[part 1 of 2: package /STELLANTIS/EPT/ASWCs]
AUTOSAR XML (schema 4-2-2)
package /STELLANTIS/EPT/ASWCs
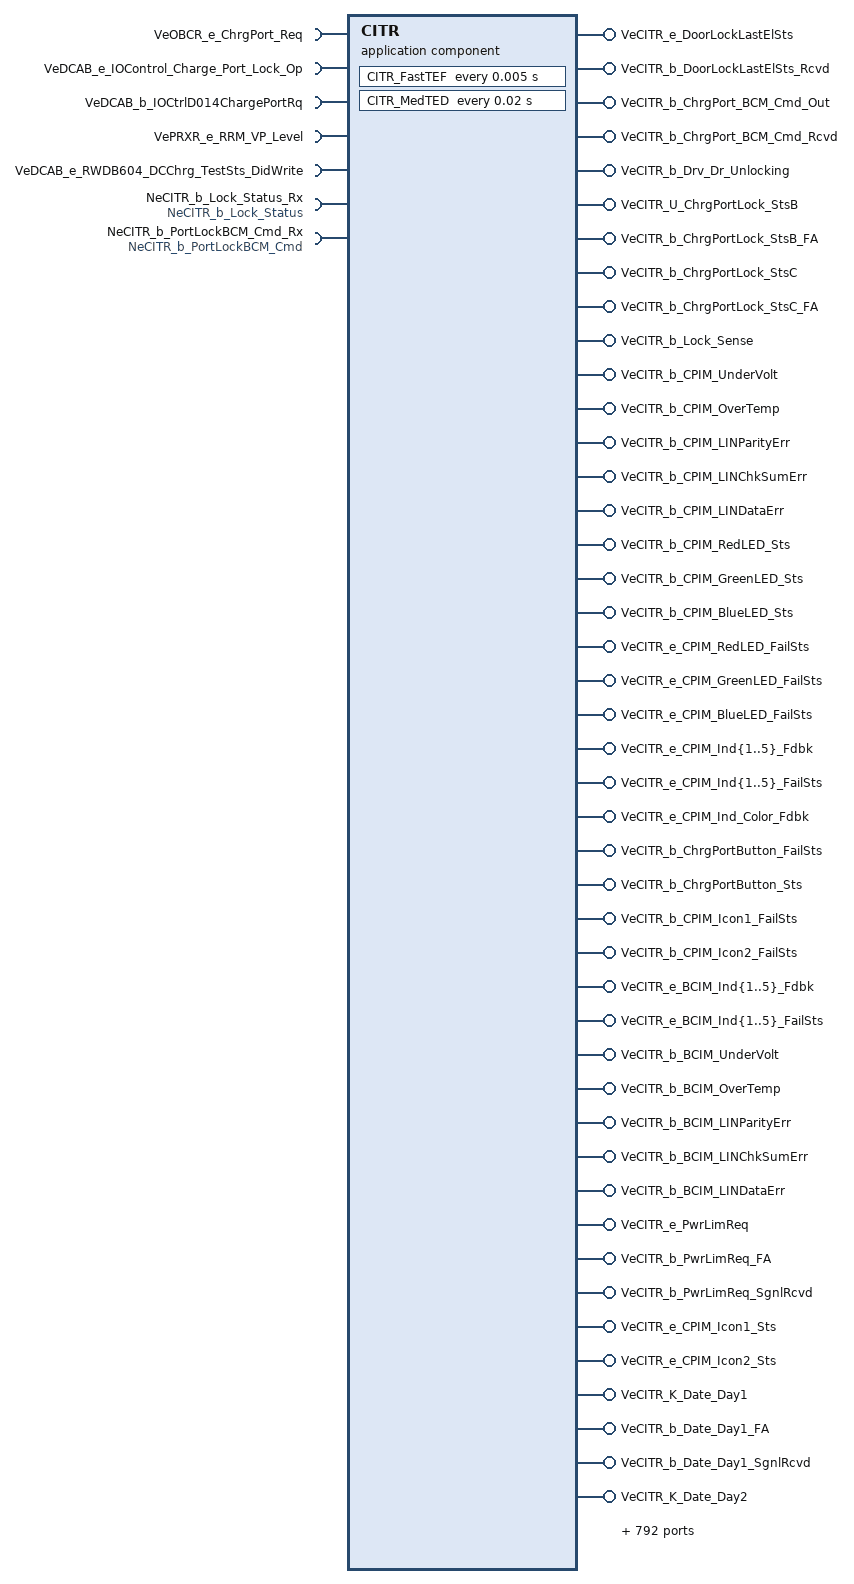
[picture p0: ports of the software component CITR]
  application sw component type CITR
    5 x require port:
      VeOBCR_e_ChrgPort_Req: nonqueued-receiver-com-spec{data-element=Value, init-value=CeOBCR_e_PortNoRequest}, required-interface=VeOBCR_e_ChrgPort_Req
      VeDCAB_e_IOControl_Charge_Port_Lock_Op: nonqueued-receiver-com-spec{data-element=Value, init-value=CeDCAB_e_IO_NOP}, required-interface=VeDCAB_e_IOControl_Charge_Port_Lock_Op
      VeDCAB_b_IOCtrlD014ChargePortRq: nonqueued-receiver-com-spec{data-element=Value, init-value=0}, required-interface=VeDCAB_b_IOCtrlD014ChargePortRq
      VePRXR_e_RRM_VP_Level: nonqueued-receiver-com-spec{data-element=Value, init-value=CePRXR_e_RRM_VP_Absent}, required-interface=VePRXR_e_RRM_VP_Level
      VeDCAB_e_RWDB604_DCChrg_TestSts_DidWrite: nonqueued-receiver-com-spec{data-element=Value, init-value=CeOBCR_e_DCChrg_TestSts_NotInit}, required-interface=VeDCAB_e_RWDB604_DCChrg_TestSts_DidWrite
    892 x provide port:
      VeCITR_e_DoorLockLastElSts: nonqueued-sender-com-spec{data-element=Value, init-value=CeOBCR_e_LKD}, provided-interface=VeCITR_e_DoorLockLastElSts
      VeCITR_b_DoorLockLastElSts_Rcvd: nonqueued-sender-com-spec{data-element=Value, init-value=0}, provided-interface=VeCITR_b_DoorLockLastElSts_Rcvd
      VeCITR_b_ChrgPort_BCM_Cmd_Out: nonqueued-sender-com-spec{data-element=Value, init-value=0}, provided-interface=VeCITR_b_ChrgPort_BCM_Cmd_Out
      VeCITR_b_ChrgPort_BCM_Cmd_Rcvd: nonqueued-sender-com-spec{data-element=Value, init-value=0}, provided-interface=VeCITR_b_ChrgPort_BCM_Cmd_Rcvd
      VeCITR_b_Drv_Dr_Unlocking: nonqueued-sender-com-spec{data-element=Value, init-value=0}, provided-interface=VeCITR_b_Drv_Dr_Unlocking
      VeCITR_U_ChrgPortLock_StsB: nonqueued-sender-com-spec{data-element=Value, init-value=0}, provided-interface=VeCITR_U_ChrgPortLock_StsB
      VeCITR_b_ChrgPortLock_StsB_FA: nonqueued-sender-com-spec{data-element=Value, init-value=0}, provided-interface=VeCITR_b_ChrgPortLock_StsB_FA
      VeCITR_b_ChrgPortLock_StsC: nonqueued-sender-com-spec{data-element=Value, init-value=0}, provided-interface=VeCITR_b_ChrgPortLock_StsC
      VeCITR_b_ChrgPortLock_StsC_FA: nonqueued-sender-com-spec{data-element=Value, init-value=0}, provided-interface=VeCITR_b_ChrgPortLock_StsC_FA
      VeCITR_b_Lock_Sense: nonqueued-sender-com-spec{data-element=Value, init-value=0}, provided-interface=VeCITR_b_Lock_Sense
      VeCITR_b_CPIM_UnderVolt: nonqueued-sender-com-spec{data-element=Value, init-value=0}, provided-interface=VeCITR_b_CPIM_UnderVolt
      VeCITR_b_CPIM_OverTemp: nonqueued-sender-com-spec{data-element=Value, init-value=0}, provided-interface=VeCITR_b_CPIM_OverTemp
      VeCITR_b_CPIM_LINParityErr: nonqueued-sender-com-spec{data-element=Value, init-value=0}, provided-interface=VeCITR_b_CPIM_LINParityErr
      VeCITR_b_CPIM_LINChkSumErr: nonqueued-sender-com-spec{data-element=Value, init-value=0}, provided-interface=VeCITR_b_CPIM_LINChkSumErr
      VeCITR_b_CPIM_LINDataErr: nonqueued-sender-com-spec{data-element=Value, init-value=0}, provided-interface=VeCITR_b_CPIM_LINDataErr
      VeCITR_b_CPIM_RedLED_Sts: nonqueued-sender-com-spec{data-element=Value, init-value=0}, provided-interface=VeCITR_b_CPIM_RedLED_Sts
      VeCITR_b_CPIM_GreenLED_Sts: nonqueued-sender-com-spec{data-element=Value, init-value=0}, provided-interface=VeCITR_b_CPIM_GreenLED_Sts
      VeCITR_b_CPIM_BlueLED_Sts: nonqueued-sender-com-spec{data-element=Value, init-value=0}, provided-interface=VeCITR_b_CPIM_BlueLED_Sts
      VeCITR_e_CPIM_RedLED_FailSts: nonqueued-sender-com-spec{data-element=Value, init-value=CeCITR_e_CPIM_LEDNormal}, provided-interface=VeCITR_e_CPIM_RedLED_FailSts
      VeCITR_e_CPIM_GreenLED_FailSts: nonqueued-sender-com-spec{data-element=Value, init-value=CeCITR_e_CPIM_LEDNormal}, provided-interface=VeCITR_e_CPIM_GreenLED_FailSts
      VeCITR_e_CPIM_BlueLED_FailSts: nonqueued-sender-com-spec{data-element=Value, init-value=CeCITR_e_CPIM_LEDNormal}, provided-interface=VeCITR_e_CPIM_BlueLED_FailSts
      VeCITR_e_CPIM_Ind{1..5}_Fdbk: nonqueued-sender-com-spec{data-element=Value, init-value=CeCITR_e_CPIM_Ind_Off}, provided-interface=VeCITR_e_CPIM_Ind{1..5}_Fdbk
      VeCITR_e_CPIM_Ind{1..5}_FailSts: nonqueued-sender-com-spec{data-element=Value, init-value=CeCITR_e_CPIM_LEDNormal}, provided-interface=VeCITR_e_CPIM_Ind{1..5}_FailSts
      VeCITR_e_CPIM_Ind_Color_Fdbk: nonqueued-sender-com-spec{data-element=Value, init-value=CeCITR_e_CPIM_NoColor}, provided-interface=VeCITR_e_CPIM_Ind_Color_Fdbk
      VeCITR_b_ChrgPortButton_FailSts: nonqueued-sender-com-spec{data-element=Value, init-value=0}, provided-interface=VeCITR_b_ChrgPortButton_FailSts
      VeCITR_b_ChrgPortButton_Sts: nonqueued-sender-com-spec{data-element=Value, init-value=0}, provided-interface=VeCITR_b_ChrgPortButton_Sts
      VeCITR_b_CPIM_Icon1_FailSts: nonqueued-sender-com-spec{data-element=Value, init-value=0}, provided-interface=VeCITR_b_CPIM_Icon1_FailSts
      VeCITR_b_CPIM_Icon2_FailSts: nonqueued-sender-com-spec{data-element=Value, init-value=0}, provided-interface=VeCITR_b_CPIM_Icon2_FailSts
      VeCITR_e_BCIM_Ind{1..5}_Fdbk: nonqueued-sender-com-spec{data-element=Value, init-value=CeCITR_e_BCIM_Ind_Off}, provided-interface=VeCITR_e_BCIM_Ind{1..5}_Fdbk
      VeCITR_e_BCIM_Ind{1..5}_FailSts: nonqueued-sender-com-spec{data-element=Value, init-value=CeCITR_e_BCIM_LEDNormal}, provided-interface=VeCITR_e_BCIM_Ind{1..5}_FailSts
      VeCITR_b_BCIM_UnderVolt: nonqueued-sender-com-spec{data-element=Value, init-value=0}, provided-interface=VeCITR_b_BCIM_UnderVolt
      VeCITR_b_BCIM_OverTemp: nonqueued-sender-com-spec{data-element=Value, init-value=0}, provided-interface=VeCITR_b_BCIM_OverTemp
      VeCITR_b_BCIM_LINParityErr: nonqueued-sender-com-spec{data-element=Value, init-value=0}, provided-interface=VeCITR_b_BCIM_LINParityErr
      VeCITR_b_BCIM_LINChkSumErr: nonqueued-sender-com-spec{data-element=Value, init-value=0}, provided-interface=VeCITR_b_BCIM_LINChkSumErr
      VeCITR_b_BCIM_LINDataErr: nonqueued-sender-com-spec{data-element=Value, init-value=0}, provided-interface=VeCITR_b_BCIM_LINDataErr
      VeCITR_e_PwrLimReq: nonqueued-sender-com-spec{data-element=Value, init-value=CeOBCR_e_PwrLimReq_SNA}, provided-interface=VeCITR_e_PwrLimReq
      VeCITR_b_PwrLimReq_FA: nonqueued-sender-com-spec{data-element=Value, init-value=0}, provided-interface=VeCITR_b_PwrLimReq_FA
      VeCITR_b_PwrLimReq_SgnlRcvd: nonqueued-sender-com-spec{data-element=Value, init-value=0}, provided-interface=VeCITR_b_PwrLimReq_SgnlRcvd
      VeCITR_e_CPIM_Icon1_Sts: nonqueued-sender-com-spec{data-element=Value, init-value=CeCITR_e_CPIM_Icon_OFF}, provided-interface=VeCITR_e_CPIM_Icon1_Sts
      VeCITR_e_CPIM_Icon2_Sts: nonqueued-sender-com-spec{data-element=Value, init-value=CeCITR_e_CPIM_Icon_OFF}, provided-interface=VeCITR_e_CPIM_Icon2_Sts
      VeCITR_K_Date_Day1: nonqueued-sender-com-spec{data-element=Value, init-value=0}, provided-interface=VeCITR_K_Date_Day1
      VeCITR_b_Date_Day1_FA: nonqueued-sender-com-spec{data-element=Value, init-value=0}, provided-interface=VeCITR_b_Date_Day1_FA
      VeCITR_b_Date_Day1_SgnlRcvd: nonqueued-sender-com-spec{data-element=Value, init-value=0}, provided-interface=VeCITR_b_Date_Day1_SgnlRcvd
      VeCITR_K_Date_Day2: nonqueued-sender-com-spec{data-element=Value, init-value=0}, provided-interface=VeCITR_K_Date_Day2
      VeCITR_K_Date_Month1: nonqueued-sender-com-spec{data-element=Value, init-value=0}, provided-interface=VeCITR_K_Date_Month1
      VeCITR_K_Date_Month2: nonqueued-sender-com-spec{data-element=Value, init-value=0}, provided-interface=VeCITR_K_Date_Month2
      VeCITR_K_Date_Year{1..4}: nonqueued-sender-com-spec{data-element=Value, init-value=0}, provided-interface=VeCITR_K_Date_Year{1..4}
      VeCITR_K_Time_Hour1: nonqueued-sender-com-spec{data-element=Value, init-value=0}, provided-interface=VeCITR_K_Time_Hour1
      VeCITR_K_Time_Hour2: nonqueued-sender-com-spec{data-element=Value, init-value=0}, provided-interface=VeCITR_K_Time_Hour2
      VeCITR_K_Time_Minute1: nonqueued-sender-com-spec{data-element=Value, init-value=0}, provided-interface=VeCITR_K_Time_Minute1
      VeCITR_K_Time_Minute2: nonqueued-sender-com-spec{data-element=Value, init-value=0}, provided-interface=VeCITR_K_Time_Minute2
      VeCITR_b_HU_Sch1_Priority: nonqueued-sender-com-spec{data-element=Value, init-value=0}, provided-interface=VeCITR_b_HU_Sch1_Priority
      VeCITR_b_HU_Sch1_ChargeUntilFull: nonqueued-sender-com-spec{data-element=Value, init-value=0}, provided-interface=VeCITR_b_HU_Sch1_ChargeUntilFull
      VeCITR_b_HU_Sch1_Do_Not_Repeat: nonqueued-sender-com-spec{data-element=Value, init-value=0}, provided-interface=VeCITR_b_HU_Sch1_Do_Not_Repeat
      VeCITR_b_HU_Sch1_Enbl: nonqueued-sender-com-spec{data-element=Value, init-value=0}, provided-interface=VeCITR_b_HU_Sch1_Enbl
      VeCITR_b_HU_Sch1_Submit: nonqueued-sender-com-spec{data-element=Value, init-value=0}, provided-interface=VeCITR_b_HU_Sch1_Submit
      VeCITR_K_HU_Sch1_Start_Time_Hr: nonqueued-sender-com-spec{data-element=Value, init-value=0}, provided-interface=VeCITR_K_HU_Sch1_Start_Time_Hr
      VeCITR_K_HU_Sch1_Start_Time_Min: nonqueued-sender-com-spec{data-element=Value, init-value=0}, provided-interface=VeCITR_K_HU_Sch1_Start_Time_Min
      VeCITR_K_HU_Sch1_End_Time_Hr: nonqueued-sender-com-spec{data-element=Value, init-value=0}, provided-interface=VeCITR_K_HU_Sch1_End_Time_Hr
      VeCITR_K_HU_Sch1_End_Time_Min: nonqueued-sender-com-spec{data-element=Value, init-value=0}, provided-interface=VeCITR_K_HU_Sch1_End_Time_Min
      VeCITR_e_HU_Sch1_Type: nonqueued-sender-com-spec{data-element=Value, init-value=CeCITR_e_SchType_NoSelection}, provided-interface=VeCITR_e_HU_Sch1_Type
      VeCITR_K_HU_Sch1_Day: nonqueued-sender-com-spec{data-element=Value, init-value=0}, provided-interface=VeCITR_K_HU_Sch1_Day
      VeCITR_b_HU_Sch1_Day_FA: nonqueued-sender-com-spec{data-element=Value, init-value=0}, provided-interface=VeCITR_b_HU_Sch1_Day_FA
      VeCITR_b_HU_Sch1_Day_SgnlRcvd: nonqueued-sender-com-spec{data-element=Value, init-value=0}, provided-interface=VeCITR_b_HU_Sch1_Day_SgnlRcvd
      VeCITR_b_TBM_Sch1_Priority: nonqueued-sender-com-spec{data-element=Value, init-value=0}, provided-interface=VeCITR_b_TBM_Sch1_Priority
      VeCITR_b_TBM_Sch1_ChargeUntilFull: nonqueued-sender-com-spec{data-element=Value, init-value=0}, provided-interface=VeCITR_b_TBM_Sch1_ChargeUntilFull
      VeCITR_b_TBM_Sch1_Do_Not_Repeat: nonqueued-sender-com-spec{data-element=Value, init-value=0}, provided-interface=VeCITR_b_TBM_Sch1_Do_Not_Repeat
      VeCITR_b_TBM_Sch1_Enbl: nonqueued-sender-com-spec{data-element=Value, init-value=0}, provided-interface=VeCITR_b_TBM_Sch1_Enbl
      VeCITR_b_TBM_Sch1_Submit: nonqueued-sender-com-spec{data-element=Value, init-value=0}, provided-interface=VeCITR_b_TBM_Sch1_Submit
      VeCITR_K_TBM_Sch1_Start_Time_Hr: nonqueued-sender-com-spec{data-element=Value, init-value=0}, provided-interface=VeCITR_K_TBM_Sch1_Start_Time_Hr
      VeCITR_K_TBM_Sch1_Start_Time_Min: nonqueued-sender-com-spec{data-element=Value, init-value=0}, provided-interface=VeCITR_K_TBM_Sch1_Start_Time_Min
      VeCITR_K_TBM_Sch1_End_Time_Hr: nonqueued-sender-com-spec{data-element=Value, init-value=0}, provided-interface=VeCITR_K_TBM_Sch1_End_Time_Hr
      VeCITR_K_TBM_Sch1_End_Time_Min: nonqueued-sender-com-spec{data-element=Value, init-value=0}, provided-interface=VeCITR_K_TBM_Sch1_End_Time_Min
      VeCITR_e_TBM_Sch1_Type: nonqueued-sender-com-spec{data-element=Value, init-value=CeCITR_e_SchType_NoSelection}, provided-interface=VeCITR_e_TBM_Sch1_Type
      VeCITR_K_TBM_Sch1_Day: nonqueued-sender-com-spec{data-element=Value, init-value=0}, provided-interface=VeCITR_K_TBM_Sch1_Day
      VeCITR_b_TBM_Sch1_Day_FA: nonqueued-sender-com-spec{data-element=Value, init-value=0}, provided-interface=VeCITR_b_TBM_Sch1_Day_FA
      VeCITR_b_TBM_Sch1_Day_SgnlRcvd: nonqueued-sender-com-spec{data-element=Value, init-value=0}, provided-interface=VeCITR_b_TBM_Sch1_Day_SgnlRcvd
      VeCITR_b_HU_Sch2_Priority: nonqueued-sender-com-spec{data-element=Value, init-value=0}, provided-interface=VeCITR_b_HU_Sch2_Priority
      VeCITR_b_HU_Sch2_ChargeUntilFull: nonqueued-sender-com-spec{data-element=Value, init-value=0}, provided-interface=VeCITR_b_HU_Sch2_ChargeUntilFull
      VeCITR_b_HU_Sch2_Do_Not_Repeat: nonqueued-sender-com-spec{data-element=Value, init-value=0}, provided-interface=VeCITR_b_HU_Sch2_Do_Not_Repeat
      VeCITR_b_HU_Sch2_Enbl: nonqueued-sender-com-spec{data-element=Value, init-value=0}, provided-interface=VeCITR_b_HU_Sch2_Enbl
      VeCITR_b_HU_Sch2_Submit: nonqueued-sender-com-spec{data-element=Value, init-value=0}, provided-interface=VeCITR_b_HU_Sch2_Submit
      VeCITR_K_HU_Sch2_Start_Time_Hr: nonqueued-sender-com-spec{data-element=Value, init-value=0}, provided-interface=VeCITR_K_HU_Sch2_Start_Time_Hr
      VeCITR_K_HU_Sch2_Start_Time_Min: nonqueued-sender-com-spec{data-element=Value, init-value=0}, provided-interface=VeCITR_K_HU_Sch2_Start_Time_Min
      VeCITR_K_HU_Sch2_End_Time_Hr: nonqueued-sender-com-spec{data-element=Value, init-value=0}, provided-interface=VeCITR_K_HU_Sch2_End_Time_Hr
      VeCITR_K_HU_Sch2_End_Time_Min: nonqueued-sender-com-spec{data-element=Value, init-value=0}, provided-interface=VeCITR_K_HU_Sch2_End_Time_Min
      VeCITR_e_HU_Sch2_Type: nonqueued-sender-com-spec{data-element=Value, init-value=CeCITR_e_SchType_NoSelection}, provided-interface=VeCITR_e_HU_Sch2_Type
      VeCITR_K_HU_Sch2_Day: nonqueued-sender-com-spec{data-element=Value, init-value=0}, provided-interface=VeCITR_K_HU_Sch2_Day
      VeCITR_b_HU_Sch2_Day_FA: nonqueued-sender-com-spec{data-element=Value, init-value=0}, provided-interface=VeCITR_b_HU_Sch2_Day_FA
      VeCITR_b_HU_Sch2_Day_SgnlRcvd: nonqueued-sender-com-spec{data-element=Value, init-value=0}, provided-interface=VeCITR_b_HU_Sch2_Day_SgnlRcvd
      VeCITR_b_TBM_Sch2_Priority: nonqueued-sender-com-spec{data-element=Value, init-value=0}, provided-interface=VeCITR_b_TBM_Sch2_Priority
      VeCITR_b_TBM_Sch2_ChargeUntilFull: nonqueued-sender-com-spec{data-element=Value, init-value=0}, provided-interface=VeCITR_b_TBM_Sch2_ChargeUntilFull
      VeCITR_b_TBM_Sch2_Do_Not_Repeat: nonqueued-sender-com-spec{data-element=Value, init-value=0}, provided-interface=VeCITR_b_TBM_Sch2_Do_Not_Repeat
      VeCITR_b_TBM_Sch2_Enbl: nonqueued-sender-com-spec{data-element=Value, init-value=0}, provided-interface=VeCITR_b_TBM_Sch2_Enbl
      VeCITR_b_TBM_Sch2_Submit: nonqueued-sender-com-spec{data-element=Value, init-value=0}, provided-interface=VeCITR_b_TBM_Sch2_Submit
      VeCITR_K_TBM_Sch2_Start_Time_Hr: nonqueued-sender-com-spec{data-element=Value, init-value=0}, provided-interface=VeCITR_K_TBM_Sch2_Start_Time_Hr
      VeCITR_K_TBM_Sch2_Start_Time_Min: nonqueued-sender-com-spec{data-element=Value, init-value=0}, provided-interface=VeCITR_K_TBM_Sch2_Start_Time_Min
      VeCITR_K_TBM_Sch2_End_Time_Hr: nonqueued-sender-com-spec{data-element=Value, init-value=0}, provided-interface=VeCITR_K_TBM_Sch2_End_Time_Hr
      VeCITR_K_TBM_Sch2_End_Time_Min: nonqueued-sender-com-spec{data-element=Value, init-value=0}, provided-interface=VeCITR_K_TBM_Sch2_End_Time_Min
      VeCITR_e_TBM_Sch2_Type: nonqueued-sender-com-spec{data-element=Value, init-value=CeCITR_e_SchType_NoSelection}, provided-interface=VeCITR_e_TBM_Sch2_Type
      VeCITR_K_TBM_Sch2_Day: nonqueued-sender-com-spec{data-element=Value, init-value=0}, provided-interface=VeCITR_K_TBM_Sch2_Day
      VeCITR_b_TBM_Sch2_Day_FA: nonqueued-sender-com-spec{data-element=Value, init-value=0}, provided-interface=VeCITR_b_TBM_Sch2_Day_FA
      VeCITR_b_TBM_Sch2_Day_SgnlRcvd: nonqueued-sender-com-spec{data-element=Value, init-value=0}, provided-interface=VeCITR_b_TBM_Sch2_Day_SgnlRcvd
      VeCITR_b_HU_Sch3_Priority: nonqueued-sender-com-spec{data-element=Value, init-value=0}, provided-interface=VeCITR_b_HU_Sch3_Priority
      VeCITR_b_HU_Sch3_ChargeUntilFull: nonqueued-sender-com-spec{data-element=Value, init-value=0}, provided-interface=VeCITR_b_HU_Sch3_ChargeUntilFull
      VeCITR_b_HU_Sch3_Do_Not_Repeat: nonqueued-sender-com-spec{data-element=Value, init-value=0}, provided-interface=VeCITR_b_HU_Sch3_Do_Not_Repeat
      VeCITR_b_HU_Sch3_Enbl: nonqueued-sender-com-spec{data-element=Value, init-value=0}, provided-interface=VeCITR_b_HU_Sch3_Enbl
      VeCITR_b_HU_Sch3_Submit: nonqueued-sender-com-spec{data-element=Value, init-value=0}, provided-interface=VeCITR_b_HU_Sch3_Submit
      VeCITR_K_HU_Sch3_Start_Time_Hr: nonqueued-sender-com-spec{data-element=Value, init-value=0}, provided-interface=VeCITR_K_HU_Sch3_Start_Time_Hr
      VeCITR_K_HU_Sch3_Start_Time_Min: nonqueued-sender-com-spec{data-element=Value, init-value=0}, provided-interface=VeCITR_K_HU_Sch3_Start_Time_Min
      VeCITR_K_HU_Sch3_End_Time_Hr: nonqueued-sender-com-spec{data-element=Value, init-value=0}, provided-interface=VeCITR_K_HU_Sch3_End_Time_Hr
      VeCITR_K_HU_Sch3_End_Time_Min: nonqueued-sender-com-spec{data-element=Value, init-value=0}, provided-interface=VeCITR_K_HU_Sch3_End_Time_Min
      VeCITR_e_HU_Sch3_Type: nonqueued-sender-com-spec{data-element=Value, init-value=CeCITR_e_SchType_NoSelection}, provided-interface=VeCITR_e_HU_Sch3_Type
      VeCITR_K_HU_Sch3_Day: nonqueued-sender-com-spec{data-element=Value, init-value=0}, provided-interface=VeCITR_K_HU_Sch3_Day
      VeCITR_b_HU_Sch3_Day_FA: nonqueued-sender-com-spec{data-element=Value, init-value=0}, provided-interface=VeCITR_b_HU_Sch3_Day_FA
      VeCITR_b_HU_Sch3_Day_SgnlRcvd: nonqueued-sender-com-spec{data-element=Value, init-value=0}, provided-interface=VeCITR_b_HU_Sch3_Day_SgnlRcvd
      VeCITR_b_TBM_Sch3_Priority: nonqueued-sender-com-spec{data-element=Value, init-value=0}, provided-interface=VeCITR_b_TBM_Sch3_Priority
      VeCITR_b_TBM_Sch3_ChargeUntilFull: nonqueued-sender-com-spec{data-element=Value, init-value=0}, provided-interface=VeCITR_b_TBM_Sch3_ChargeUntilFull
      VeCITR_b_TBM_Sch3_Do_Not_Repeat: nonqueued-sender-com-spec{data-element=Value, init-value=0}, provided-interface=VeCITR_b_TBM_Sch3_Do_Not_Repeat
      VeCITR_b_TBM_Sch3_Enbl: nonqueued-sender-com-spec{data-element=Value, init-value=0}, provided-interface=VeCITR_b_TBM_Sch3_Enbl
      VeCITR_b_TBM_Sch3_Submit: nonqueued-sender-com-spec{data-element=Value, init-value=0}, provided-interface=VeCITR_b_TBM_Sch3_Submit
      VeCITR_K_TBM_Sch3_Start_Time_Hr: nonqueued-sender-com-spec{data-element=Value, init-value=0}, provided-interface=VeCITR_K_TBM_Sch3_Start_Time_Hr
      VeCITR_K_TBM_Sch3_Start_Time_Min: nonqueued-sender-com-spec{data-element=Value, init-value=0}, provided-interface=VeCITR_K_TBM_Sch3_Start_Time_Min
      VeCITR_K_TBM_Sch3_End_Time_Hr: nonqueued-sender-com-spec{data-element=Value, init-value=0}, provided-interface=VeCITR_K_TBM_Sch3_End_Time_Hr
      VeCITR_K_TBM_Sch3_End_Time_Min: nonqueued-sender-com-spec{data-element=Value, init-value=0}, provided-interface=VeCITR_K_TBM_Sch3_End_Time_Min
      VeCITR_e_TBM_Sch3_Type: nonqueued-sender-com-spec{data-element=Value, init-value=CeCITR_e_SchType_NoSelection}, provided-interface=VeCITR_e_TBM_Sch3_Type
      VeCITR_K_TBM_Sch3_Day: nonqueued-sender-com-spec{data-element=Value, init-value=0}, provided-interface=VeCITR_K_TBM_Sch3_Day
      VeCITR_b_TBM_Sch3_Day_FA: nonqueued-sender-com-spec{data-element=Value, init-value=0}, provided-interface=VeCITR_b_TBM_Sch3_Day_FA
      VeCITR_b_TBM_Sch3_Day_SgnlRcvd: nonqueued-sender-com-spec{data-element=Value, init-value=0}, provided-interface=VeCITR_b_TBM_Sch3_Day_SgnlRcvd
      VeCITR_b_ChargeNow: nonqueued-sender-com-spec{data-element=Value, init-value=0}, provided-interface=VeCITR_b_ChargeNow
      VeCITR_e_CPIM_ChrgPortLock_FailSts: nonqueued-sender-com-spec{data-element=Value, init-value=CeCITR_e_CPIMLock_Nofailure}, provided-interface=VeCITR_e_CPIM_ChrgPortLock_FailSts
      VeCITR_e_RRM_VP_Level: nonqueued-sender-com-spec{data-element=Value, init-value=CeCITR_e_RRM_VP_Absent}, provided-interface=VeCITR_e_RRM_VP_Level
      VeCITR_b_ChrgPortDoorSts: nonqueued-sender-com-spec{data-element=Value, init-value=0}, provided-interface=VeCITR_b_ChrgPortDoorSts
      VeCITR_b_TBM_ChargeNow: nonqueued-sender-com-spec{data-element=Value, init-value=0}, provided-interface=VeCITR_b_TBM_ChargeNow
      VeCITR_d_ChrgPortHbridgeFlt: nonqueued-sender-com-spec{data-element=Value, init-value=0}, provided-interface=VeCITR_d_ChrgPortHbridgeFlt
      VeCITR_b_HU_Sch1_Start_Time_HrFA: nonqueued-sender-com-spec{data-element=Value, init-value=0}, provided-interface=VeCITR_b_HU_Sch1_Start_Time_HrFA
      VeCITR_b_HU_Sch1_Start_Time_MinFA: nonqueued-sender-com-spec{data-element=Value, init-value=0}, provided-interface=VeCITR_b_HU_Sch1_Start_Time_MinFA
      VeCITR_b_HU_Sch1_End_Time_HrFA: nonqueued-sender-com-spec{data-element=Value, init-value=0}, provided-interface=VeCITR_b_HU_Sch1_End_Time_HrFA
      VeCITR_b_HU_Sch1_End_Time_MinFA: nonqueued-sender-com-spec{data-element=Value, init-value=0}, provided-interface=VeCITR_b_HU_Sch1_End_Time_MinFA
      VeCITR_b_HU_Sch1_TypeFA: nonqueued-sender-com-spec{data-element=Value, init-value=0}, provided-interface=VeCITR_b_HU_Sch1_TypeFA
      VeCITR_b_HU_Sch2_Start_Time_HrFA: nonqueued-sender-com-spec{data-element=Value, init-value=0}, provided-interface=VeCITR_b_HU_Sch2_Start_Time_HrFA
      VeCITR_b_HU_Sch2_Start_Time_MinFA: nonqueued-sender-com-spec{data-element=Value, init-value=0}, provided-interface=VeCITR_b_HU_Sch2_Start_Time_MinFA
      VeCITR_b_HU_Sch2_End_Time_HrFA: nonqueued-sender-com-spec{data-element=Value, init-value=0}, provided-interface=VeCITR_b_HU_Sch2_End_Time_HrFA
      VeCITR_b_HU_Sch2_End_Time_MinFA: nonqueued-sender-com-spec{data-element=Value, init-value=0}, provided-interface=VeCITR_b_HU_Sch2_End_Time_MinFA
      VeCITR_b_HU_Sch2_TypeFA: nonqueued-sender-com-spec{data-element=Value, init-value=0}, provided-interface=VeCITR_b_HU_Sch2_TypeFA
      VeCITR_b_HU_Sch3_Start_Time_HrFA: nonqueued-sender-com-spec{data-element=Value, init-value=0}, provided-interface=VeCITR_b_HU_Sch3_Start_Time_HrFA
      VeCITR_b_HU_Sch3_Start_Time_MinFA: nonqueued-sender-com-spec{data-element=Value, init-value=0}, provided-interface=VeCITR_b_HU_Sch3_Start_Time_MinFA
      VeCITR_b_HU_Sch3_End_Time_HrFA: nonqueued-sender-com-spec{data-element=Value, init-value=0}, provided-interface=VeCITR_b_HU_Sch3_End_Time_HrFA
      VeCITR_b_HU_Sch3_End_Time_MinFA: nonqueued-sender-com-spec{data-element=Value, init-value=0}, provided-interface=VeCITR_b_HU_Sch3_End_Time_MinFA
      VeCITR_b_HU_Sch3_TypeFA: nonqueued-sender-com-spec{data-element=Value, init-value=0}, provided-interface=VeCITR_b_HU_Sch3_TypeFA
      VeCITR_b_TBM_Sch1_Start_Time_HrFA: nonqueued-sender-com-spec{data-element=Value, init-value=0}, provided-interface=VeCITR_b_TBM_Sch1_Start_Time_HrFA
      VeCITR_b_TBM_Sch1_Start_Time_MinFA: nonqueued-sender-com-spec{data-element=Value, init-value=0}, provided-interface=VeCITR_b_TBM_Sch1_Start_Time_MinFA
      VeCITR_b_TBM_Sch1_End_Time_HrFA: nonqueued-sender-com-spec{data-element=Value, init-value=0}, provided-interface=VeCITR_b_TBM_Sch1_End_Time_HrFA
      VeCITR_b_TBM_Sch1_End_Time_MinFA: nonqueued-sender-com-spec{data-element=Value, init-value=0}, provided-interface=VeCITR_b_TBM_Sch1_End_Time_MinFA
      VeCITR_b_TBM_Sch1_TypeFA: nonqueued-sender-com-spec{data-element=Value, init-value=0}, provided-interface=VeCITR_b_TBM_Sch1_TypeFA
      VeCITR_b_TBM_Sch2_Start_Time_HrFA: nonqueued-sender-com-spec{data-element=Value, init-value=0}, provided-interface=VeCITR_b_TBM_Sch2_Start_Time_HrFA
      VeCITR_b_TBM_Sch2_Start_Time_MinFA: nonqueued-sender-com-spec{data-element=Value, init-value=0}, provided-interface=VeCITR_b_TBM_Sch2_Start_Time_MinFA
      VeCITR_b_TBM_Sch2_End_Time_HrFA: nonqueued-sender-com-spec{data-element=Value, init-value=0}, provided-interface=VeCITR_b_TBM_Sch2_End_Time_HrFA
      VeCITR_b_TBM_Sch2_End_Time_MinFA: nonqueued-sender-com-spec{data-element=Value, init-value=0}, provided-interface=VeCITR_b_TBM_Sch2_End_Time_MinFA
      VeCITR_b_TBM_Sch2_TypeFA: nonqueued-sender-com-spec{data-element=Value, init-value=0}, provided-interface=VeCITR_b_TBM_Sch2_TypeFA
      VeCITR_b_TBM_Sch3_Start_Time_HrFA: nonqueued-sender-com-spec{data-element=Value, init-value=0}, provided-interface=VeCITR_b_TBM_Sch3_Start_Time_HrFA
      VeCITR_b_TBM_Sch3_Start_Time_MinFA: nonqueued-sender-com-spec{data-element=Value, init-value=0}, provided-interface=VeCITR_b_TBM_Sch3_Start_Time_MinFA
      VeCITR_b_TBM_Sch3_End_Time_HrFA: nonqueued-sender-com-spec{data-element=Value, init-value=0}, provided-interface=VeCITR_b_TBM_Sch3_End_Time_HrFA
      VeCITR_b_TBM_Sch3_End_Time_MinFA: nonqueued-sender-com-spec{data-element=Value, init-value=0}, provided-interface=VeCITR_b_TBM_Sch3_End_Time_MinFA
      VeCITR_b_TBM_Sch3_TypeFA: nonqueued-sender-com-spec{data-element=Value, init-value=0}, provided-interface=VeCITR_b_TBM_Sch3_TypeFA
      VeCITR_b_CPIM_Ind{1..5}_FdbkFA: nonqueued-sender-com-spec{data-element=Value, init-value=0}, provided-interface=VeCITR_b_CPIM_Ind{1..5}_FdbkFA
      VeCITR_b_CPIM_Ind_Color_FdbkFA: nonqueued-sender-com-spec{data-element=Value, init-value=0}, provided-interface=VeCITR_b_CPIM_Ind_Color_FdbkFA
      VeCITR_b_CPIM_Icon1_StsFA: nonqueued-sender-com-spec{data-element=Value, init-value=0}, provided-interface=VeCITR_b_CPIM_Icon1_StsFA
      VeCITR_b_CPIM_Icon2_StsFA: nonqueued-sender-com-spec{data-element=Value, init-value=0}, provided-interface=VeCITR_b_CPIM_Icon2_StsFA
      VeCITR_b_BCIM_Ind{1..5}_FdbkFA: nonqueued-sender-com-spec{data-element=Value, init-value=0}, provided-interface=VeCITR_b_BCIM_Ind{1..5}_FdbkFA
      VeCITR_b_ChrgPortLock_FailStsFA: nonqueued-sender-com-spec{data-element=Value, init-value=0}, provided-interface=VeCITR_b_ChrgPortLock_FailStsFA
      VeCITR_K_DateTmDay: nonqueued-sender-com-spec{data-element=Value, init-value=0}, provided-interface=VeCITR_K_DateTmDay
      VeCITR_b_DateTmDay_FA: nonqueued-sender-com-spec{data-element=Value, init-value=0}, provided-interface=VeCITR_b_DateTmDay_FA
      VeCITR_b_DateTmDay_SgnlRcvd: nonqueued-sender-com-spec{data-element=Value, init-value=0}, provided-interface=VeCITR_b_DateTmDay_SgnlRcvd
      VeCITR_K_DateTmMon: nonqueued-sender-com-spec{data-element=Value, init-value=0}, provided-interface=VeCITR_K_DateTmMon
      VeCITR_K_DateTmYear: nonqueued-sender-com-spec{data-element=Value, init-value=0}, provided-interface=VeCITR_K_DateTmYear
      VeCITR_K_DateTmHour: nonqueued-sender-com-spec{data-element=Value, init-value=0}, provided-interface=VeCITR_K_DateTmHour
      VeCITR_K_DateTmMin: nonqueued-sender-com-spec{data-element=Value, init-value=0}, provided-interface=VeCITR_K_DateTmMin
      VeCITR_K_DateTmSec: nonqueued-sender-com-spec{data-element=Value, init-value=0}, provided-interface=VeCITR_K_DateTmSec
      VeCITR_e_DateTmFormat: nonqueued-sender-com-spec{data-element=Value, init-value=CeCITR_e_DateTm_NotDef}, provided-interface=VeCITR_e_DateTmFormat
      VeCITR_b_DateTmFormat_FA: nonqueued-sender-com-spec{data-element=Value, init-value=0}, provided-interface=VeCITR_b_DateTmFormat_FA
      VeCITR_e_DVC_ChrgPort_IO: nonqueued-sender-com-spec{data-element=Value, init-value=CeODCR_e_Return_ECU_Cntrl}, provided-interface=VeCITR_e_DVC_ChrgPort_IO
      VeCITR_b_DVC_ChrgPortRq: nonqueued-sender-com-spec{data-element=Value, init-value=0}, provided-interface=VeCITR_b_DVC_ChrgPortRq
      VeCITR_e_DCChrg_TestSts: nonqueued-sender-com-spec{data-element=Value, init-value=CeOBCR_e_DCChrg_TestSts_NotInit}, provided-interface=VeCITR_e_DCChrg_TestSts
      VeCITR_Cnt_DCEOL_SgnlRcvd: nonqueued-sender-com-spec{data-element=Value, init-value=0}, provided-interface=VeCITR_Cnt_DCEOL_SgnlRcvd
      VeCITR_b_PortLockBCM_Cmd: nonqueued-sender-com-spec{data-element=Value, init-value=0}, provided-interface=VeCITR_b_PortLockBCM_Cmd
      VeCITR_e_ChrgPortLock_StsB: nonqueued-sender-com-spec{data-element=Value, init-value=CeOBCR_e_DefaultLock_Sts}, provided-interface=VeCITR_e_ChrgPortLock_StsB
      VeCITR_b_HBridge_ChrgPortLck_Cal: nonqueued-sender-com-spec{data-element=Value, init-value=0}, provided-interface=VeCITR_b_HBridge_ChrgPortLck_Cal
      VeCITR_b_ChrgPortLockSts: nonqueued-sender-com-spec{data-element=Value, init-value=0}, provided-interface=VeCITR_b_ChrgPortLockSts
      VeCITR_b_ChrgPortLockSts_FA: nonqueued-sender-com-spec{data-element=Value, init-value=0}, provided-interface=VeCITR_b_ChrgPortLockSts_FA
      VeCITR_b_ChrgPortSts: nonqueued-sender-com-spec{data-element=Value, init-value=0}, provided-interface=VeCITR_b_ChrgPortSts
      VeCITR_e_DVC_BCIM_IO: nonqueued-sender-com-spec{data-element=Value, init-value=CeODCR_e_Return_ECU_Cntrl}, provided-interface=VeCITR_e_DVC_BCIM_IO
      VeCITR_e_DVC_BCIM_Ind{1..5}: nonqueued-sender-com-spec{data-element=Value, init-value=CeCITR_e_BCIM_Ind_Off}, provided-interface=VeCITR_e_DVC_BCIM_Ind{1..5}
      VeCITR_e_DVC_CPIM_IO: nonqueued-sender-com-spec{data-element=Value, init-value=CeODCR_e_Return_ECU_Cntrl}, provided-interface=VeCITR_e_DVC_CPIM_IO
      VeCITR_e_DVC_CPIM_Ind{1..5}: nonqueued-sender-com-spec{data-element=Value, init-value=CeCITR_e_CPIM_Ind_Off}, provided-interface=VeCITR_e_DVC_CPIM_Ind{1..5}
      VeCITR_e_DVC_CPIMBlinkRate: nonqueued-sender-com-spec{data-element=Value, init-value=CeCITR_e_CPIM_NoBlink}, provided-interface=VeCITR_e_DVC_CPIMBlinkRate
      VeCITR_e_DVC_CPIM_Color: nonqueued-sender-com-spec{data-element=Value, init-value=CeCITR_e_CPIM_NoColor}, provided-interface=VeCITR_e_DVC_CPIM_Color
      VeCITR_e_DVC_CPIM_IconI1: nonqueued-sender-com-spec{data-element=Value, init-value=CeCITR_e_CPIM_Icon_OFF}, provided-interface=VeCITR_e_DVC_CPIM_IconI1
      VeCITR_e_DVC_CPIM_IconI2: nonqueued-sender-com-spec{data-element=Value, init-value=CeCITR_e_CPIM_Icon_OFF}, provided-interface=VeCITR_e_DVC_CPIM_IconI2
      VeCITR_e_DVC_BCIM_BlinkRate: nonqueued-sender-com-spec{data-element=Value, init-value=CeCITR_e_BCIM_NoBlink}, provided-interface=VeCITR_e_DVC_BCIM_BlinkRate
      VeCITR_T_HU_Sch1_Temperature: nonqueued-sender-com-spec{data-element=Value, init-value=0}, provided-interface=VeCITR_T_HU_Sch1_Temperature
      VeCITR_b_HU_Sch1_TemperatureFA: nonqueued-sender-com-spec{data-element=Value, init-value=0}, provided-interface=VeCITR_b_HU_Sch1_TemperatureFA
      VeCITR_T_TBM_Sch1_Temperature: nonqueued-sender-com-spec{data-element=Value, init-value=0}, provided-interface=VeCITR_T_TBM_Sch1_Temperature
      VeCITR_b_TBM_Sch1_TemperatureFA: nonqueued-sender-com-spec{data-element=Value, init-value=0}, provided-interface=VeCITR_b_TBM_Sch1_TemperatureFA
      VeCITR_T_HU_Sch2_Temperature: nonqueued-sender-com-spec{data-element=Value, init-value=0}, provided-interface=VeCITR_T_HU_Sch2_Temperature
      VeCITR_b_HU_Sch2_TemperatureFA: nonqueued-sender-com-spec{data-element=Value, init-value=0}, provided-interface=VeCITR_b_HU_Sch2_TemperatureFA
      VeCITR_T_TBM_Sch2_Temperature: nonqueued-sender-com-spec{data-element=Value, init-value=0}, provided-interface=VeCITR_T_TBM_Sch2_Temperature
      VeCITR_b_TBM_Sch2_TemperatureFA: nonqueued-sender-com-spec{data-element=Value, init-value=0}, provided-interface=VeCITR_b_TBM_Sch2_TemperatureFA
      VeCITR_T_HU_Sch3_Temperature: nonqueued-sender-com-spec{data-element=Value, init-value=0}, provided-interface=VeCITR_T_HU_Sch3_Temperature
      VeCITR_b_HU_Sch3_TemperatureFA: nonqueued-sender-com-spec{data-element=Value, init-value=0}, provided-interface=VeCITR_b_HU_Sch3_TemperatureFA
      VeCITR_T_TBM_Sch3_Temperature: nonqueued-sender-com-spec{data-element=Value, init-value=0}, provided-interface=VeCITR_T_TBM_Sch3_Temperature
      VeCITR_b_TBM_Sch3_TemperatureFA: nonqueued-sender-com-spec{data-element=Value, init-value=0}, provided-interface=VeCITR_b_TBM_Sch3_TemperatureFA
      VeCITR_e_HU_Sch3_Allow: nonqueued-sender-com-spec{data-element=Value, init-value=CeCITR_e_AnyTime}, provided-interface=VeCITR_e_HU_Sch3_Allow
      VeCITR_b_HU_Sch3_AllowFA: nonqueued-sender-com-spec{data-element=Value, init-value=0}, provided-interface=VeCITR_b_HU_Sch3_AllowFA
      VeCITR_e_TBM_Sch3_Allow: nonqueued-sender-com-spec{data-element=Value, init-value=CeCITR_e_AnyTime}, provided-interface=VeCITR_e_TBM_Sch3_Allow
      VeCITR_b_TBM_Sch3_AllowFA: nonqueued-sender-com-spec{data-element=Value, init-value=0}, provided-interface=VeCITR_b_TBM_Sch3_AllowFA
      VeCITR_b_HU_Sch4_Enbl: nonqueued-sender-com-spec{data-element=Value, init-value=0}, provided-interface=VeCITR_b_HU_Sch4_Enbl
      VeCITR_b_HU_Sch4_Submit: nonqueued-sender-com-spec{data-element=Value, init-value=0}, provided-interface=VeCITR_b_HU_Sch4_Submit
      VeCITR_K_HU_Sch4_Start_Time_Hr: nonqueued-sender-com-spec{data-element=Value, init-value=0}, provided-interface=VeCITR_K_HU_Sch4_Start_Time_Hr
      VeCITR_K_HU_Sch4_Start_Time_Min: nonqueued-sender-com-spec{data-element=Value, init-value=0}, provided-interface=VeCITR_K_HU_Sch4_Start_Time_Min
      VeCITR_K_HU_Sch4_Day: nonqueued-sender-com-spec{data-element=Value, init-value=0}, provided-interface=VeCITR_K_HU_Sch4_Day
      VeCITR_b_HU_Sch4_Day_FA: nonqueued-sender-com-spec{data-element=Value, init-value=0}, provided-interface=VeCITR_b_HU_Sch4_Day_FA
      VeCITR_b_HU_Sch4_Day_SgnlRcvd: nonqueued-sender-com-spec{data-element=Value, init-value=0}, provided-interface=VeCITR_b_HU_Sch4_Day_SgnlRcvd
      VeCITR_b_HU_Sch4_Start_Time_HrFA: nonqueued-sender-com-spec{data-element=Value, init-value=0}, provided-interface=VeCITR_b_HU_Sch4_Start_Time_HrFA
      VeCITR_b_HU_Sch4_Start_Time_MinFA: nonqueued-sender-com-spec{data-element=Value, init-value=0}, provided-interface=VeCITR_b_HU_Sch4_Start_Time_MinFA
      VeCITR_T_HU_Sch4_Temperature: nonqueued-sender-com-spec{data-element=Value, init-value=0}, provided-interface=VeCITR_T_HU_Sch4_Temperature
      VeCITR_b_HU_Sch4_TemperatureFA: nonqueued-sender-com-spec{data-element=Value, init-value=0}, provided-interface=VeCITR_b_HU_Sch4_TemperatureFA
      VeCITR_e_HU_Sch4_Allow: nonqueued-sender-com-spec{data-element=Value, init-value=CeCITR_e_AnyTime}, provided-interface=VeCITR_e_HU_Sch4_Allow
      VeCITR_b_HU_Sch4_AllowFA: nonqueued-sender-com-spec{data-element=Value, init-value=0}, provided-interface=VeCITR_b_HU_Sch4_AllowFA
      VeCITR_b_TBM_Sch4_Enbl: nonqueued-sender-com-spec{data-element=Value, init-value=0}, provided-interface=VeCITR_b_TBM_Sch4_Enbl
      VeCITR_b_TBM_Sch4_Submit: nonqueued-sender-com-spec{data-element=Value, init-value=0}, provided-interface=VeCITR_b_TBM_Sch4_Submit
      VeCITR_K_TBM_Sch4_Start_Time_Hr: nonqueued-sender-com-spec{data-element=Value, init-value=0}, provided-interface=VeCITR_K_TBM_Sch4_Start_Time_Hr
      VeCITR_K_TBM_Sch4_Start_Time_Min: nonqueued-sender-com-spec{data-element=Value, init-value=0}, provided-interface=VeCITR_K_TBM_Sch4_Start_Time_Min
      VeCITR_K_TBM_Sch4_Day: nonqueued-sender-com-spec{data-element=Value, init-value=0}, provided-interface=VeCITR_K_TBM_Sch4_Day
      VeCITR_b_TBM_Sch4_Day_FA: nonqueued-sender-com-spec{data-element=Value, init-value=0}, provided-interface=VeCITR_b_TBM_Sch4_Day_FA
      VeCITR_b_TBM_Sch4_Day_SgnlRcvd: nonqueued-sender-com-spec{data-element=Value, init-value=0}, provided-interface=VeCITR_b_TBM_Sch4_Day_SgnlRcvd
      VeCITR_b_TBM_Sch4_Start_Time_HrFA: nonqueued-sender-com-spec{data-element=Value, init-value=0}, provided-interface=VeCITR_b_TBM_Sch4_Start_Time_HrFA
      VeCITR_b_TBM_Sch4_Start_Time_MinFA: nonqueued-sender-com-spec{data-element=Value, init-value=0}, provided-interface=VeCITR_b_TBM_Sch4_Start_Time_MinFA
      VeCITR_T_TBM_Sch4_Temperature: nonqueued-sender-com-spec{data-element=Value, init-value=0}, provided-interface=VeCITR_T_TBM_Sch4_Temperature
      VeCITR_b_TBM_Sch4_TemperatureFA: nonqueued-sender-com-spec{data-element=Value, init-value=0}, provided-interface=VeCITR_b_TBM_Sch4_TemperatureFA
      VeCITR_e_TBM_Sch4_Allow: nonqueued-sender-com-spec{data-element=Value, init-value=CeCITR_e_AnyTime}, provided-interface=VeCITR_e_TBM_Sch4_Allow
      VeCITR_b_TBM_Sch4_AllowFA: nonqueued-sender-com-spec{data-element=Value, init-value=0}, provided-interface=VeCITR_b_TBM_Sch4_AllowFA
      VeCITR_P_ChargingDestinationPwr: nonqueued-sender-com-spec{data-element=Value, init-value=0}, provided-interface=VeCITR_P_ChargingDestinationPwr
      VeCITR_b_ChargingDestinationPwr_FA: nonqueued-sender-com-spec{data-element=Value, init-value=0}, provided-interface=VeCITR_b_ChargingDestinationPwr_FA
      VeCITR_l_DistanceToCharge: nonqueued-sender-com-spec{data-element=Value, init-value=0}, provided-interface=VeCITR_l_DistanceToCharge
      VeCITR_b_DistanceToCharge_FA: nonqueued-sender-com-spec{data-element=Value, init-value=0}, provided-interface=VeCITR_b_DistanceToCharge_FA
      VeCITR_t_TimeToCharge: nonqueued-sender-com-spec{data-element=Value, init-value=0}, provided-interface=VeCITR_t_TimeToCharge
      VeCITR_b_TimeToCharge_FA: nonqueued-sender-com-spec{data-element=Value, init-value=0}, provided-interface=VeCITR_b_TimeToCharge_FA
      VeCITR_e_FOTA_Install_Type: nonqueued-sender-com-spec{data-element=Value, init-value=CeCITR_e_NoFOTA}, provided-interface=VeCITR_e_FOTA_Install_Type
      VeCITR_b_FOTA_Install_Type_FA: nonqueued-sender-com-spec{data-element=Value, init-value=0}, provided-interface=VeCITR_b_FOTA_Install_Type_FA
      VeCITR_e_FOTA_Install_Status: nonqueued-sender-com-spec{data-element=Value, init-value=CeCITR_e_Installation_Default}, provided-interface=VeCITR_e_FOTA_Install_Status
      VeCITR_b_SOC_Max_Lev: nonqueued-sender-com-spec{data-element=Value, init-value=0}, provided-interface=VeCITR_b_SOC_Max_Lev
      VeCITR_b_SOC_Max_Lev_FA: nonqueued-sender-com-spec{data-element=Value, init-value=0}, provided-interface=VeCITR_b_SOC_Max_Lev_FA
      VeCITR_b_DC_PwrLev: nonqueued-sender-com-spec{data-element=Value, init-value=0}, provided-interface=VeCITR_b_DC_PwrLev
      VeCITR_b_DC_PwrLev_FA: nonqueued-sender-com-spec{data-element=Value, init-value=0}, provided-interface=VeCITR_b_DC_PwrLev_FA
      VeCITR_b_DC_PwrLev_SgnlRcvd: nonqueued-sender-com-spec{data-element=Value, init-value=0}, provided-interface=VeCITR_b_DC_PwrLev_SgnlRcvd
      VeCITR_e_ChrgrFlapSts: nonqueued-sender-com-spec{data-element=Value, init-value=CeCITR_e_ChrgrFlap_Closed}, provided-interface=VeCITR_e_ChrgrFlapSts
      VeCITR_b_ChrgrFlapSts_FA: nonqueued-sender-com-spec{data-element=Value, init-value=0}, provided-interface=VeCITR_b_ChrgrFlapSts_FA
      VeCITR_e_BCIM_Ind_Color_Fdbk: nonqueued-sender-com-spec{data-element=Value, init-value=CeCITR_e_BCIM_NoColor}, provided-interface=VeCITR_e_BCIM_Ind_Color_Fdbk
      VeCITR_b_BCIM_Ind_Color_FdbkFA: nonqueued-sender-com-spec{data-element=Value, init-value=0}, provided-interface=VeCITR_b_BCIM_Ind_Color_FdbkFA
      VeCITR_e_DVC_BCIM_Color: nonqueued-sender-com-spec{data-element=Value, init-value=CeCITR_e_BCIM_NoColor}, provided-interface=VeCITR_e_DVC_BCIM_Color
      VeCITR_e_HU_ChrgSchedType1: nonqueued-sender-com-spec{data-element=Value, init-value=CeCITR_e_No_Selection}, provided-interface=VeCITR_e_HU_ChrgSchedType1
      VeCITR_b_HU_ChrgSchedType1FA: nonqueued-sender-com-spec{data-element=Value, init-value=0}, provided-interface=VeCITR_b_HU_ChrgSchedType1FA
      VeCITR_e_HU_ChrgSchedType2: nonqueued-sender-com-spec{data-element=Value, init-value=CeCITR_e_No_Selection}, provided-interface=VeCITR_e_HU_ChrgSchedType2
      VeCITR_b_HU_ChrgSchedType2FA: nonqueued-sender-com-spec{data-element=Value, init-value=0}, provided-interface=VeCITR_b_HU_ChrgSchedType2FA
      VeCITR_Pct_HU_ExtChrgTarget1: nonqueued-sender-com-spec{data-element=Value, init-value=0}, provided-interface=VeCITR_Pct_HU_ExtChrgTarget1
      VeCITR_b_HU_ExtChrgTarget1FA: nonqueued-sender-com-spec{data-element=Value, init-value=0}, provided-interface=VeCITR_b_HU_ExtChrgTarget1FA
      VeCITR_Pct_HU_ExtChrgTarget2: nonqueued-sender-com-spec{data-element=Value, init-value=0}, provided-interface=VeCITR_Pct_HU_ExtChrgTarget2
      VeCITR_b_HU_ExtChrgTarget2FA: nonqueued-sender-com-spec{data-element=Value, init-value=0}, provided-interface=VeCITR_b_HU_ExtChrgTarget2FA
      VeCITR_Pct_HU_ImmChrgTarget1: nonqueued-sender-com-spec{data-element=Value, init-value=0}, provided-interface=VeCITR_Pct_HU_ImmChrgTarget1
      VeCITR_b_HU_ImmChrgTarget1FA: nonqueued-sender-com-spec{data-element=Value, init-value=0}, provided-interface=VeCITR_b_HU_ImmChrgTarget1FA
      VeCITR_Pct_HU_ImmChrgTarget2: nonqueued-sender-com-spec{data-element=Value, init-value=0}, provided-interface=VeCITR_Pct_HU_ImmChrgTarget2
      VeCITR_b_HU_ImmChrgTarget2FA: nonqueued-sender-com-spec{data-element=Value, init-value=0}, provided-interface=VeCITR_b_HU_ImmChrgTarget2FA
      VeCITR_b_CoopCh_VehLocation: nonqueued-sender-com-spec{data-element=Value, init-value=0}, provided-interface=VeCITR_b_CoopCh_VehLocation
      VeCITR_b_CoopCh_VehLocationFA: nonqueued-sender-com-spec{data-element=Value, init-value=0}, provided-interface=VeCITR_b_CoopCh_VehLocationFA
      VeCITR_e_RmtChrgPortLkCmd: nonqueued-sender-com-spec{data-element=Value, init-value=CeCITR_e_Default}, provided-interface=VeCITR_e_RmtChrgPortLkCmd
      VeCITR_b_RmtChrgPortLkCmdFA: nonqueued-sender-com-spec{data-element=Value, init-value=0}, provided-interface=VeCITR_b_RmtChrgPortLkCmdFA
      VeCITR_b_RmtChrgPortLkCmd_SgnlRcvd: nonqueued-sender-com-spec{data-element=Value, init-value=0}, provided-interface=VeCITR_b_RmtChrgPortLkCmd_SgnlRcvd
      VeCITR_e_CoopCh_ChrgCmd: nonqueued-sender-com-spec{data-element=Value, init-value=CeCITR_e_DEFAULT}, provided-interface=VeCITR_e_CoopCh_ChrgCmd
      VeCITR_b_CoopCh_ChrgCmdFA: nonqueued-sender-com-spec{data-element=Value, init-value=0}, provided-interface=VeCITR_b_CoopCh_ChrgCmdFA
      VeCITR_b_TBMStopChrg: nonqueued-sender-com-spec{data-element=Value, init-value=0}, provided-interface=VeCITR_b_TBMStopChrg
      VeCITR_b_TBMStopChrgFA: nonqueued-sender-com-spec{data-element=Value, init-value=0}, provided-interface=VeCITR_b_TBMStopChrgFA
      VeCITR_e_TBM_ChrgSchedType1: nonqueued-sender-com-spec{data-element=Value, init-value=CeCITR_e_No_Selection}, provided-interface=VeCITR_e_TBM_ChrgSchedType1
      VeCITR_b_TBM_ChrgSchedType1FA: nonqueued-sender-com-spec{data-element=Value, init-value=0}, provided-interface=VeCITR_b_TBM_ChrgSchedType1FA
      VeCITR_e_TBM_ChrgSchedType2: nonqueued-sender-com-spec{data-element=Value, init-value=CeCITR_e_No_Selection}, provided-interface=VeCITR_e_TBM_ChrgSchedType2
      VeCITR_b_TBM_ChrgSchedType2FA: nonqueued-sender-com-spec{data-element=Value, init-value=0}, provided-interface=VeCITR_b_TBM_ChrgSchedType2FA
      VeCITR_Pct_TBM_ExtChrgTarget1: nonqueued-sender-com-spec{data-element=Value, init-value=0}, provided-interface=VeCITR_Pct_TBM_ExtChrgTarget1
      VeCITR_b_TBM_ExtChrgTarget1FA: nonqueued-sender-com-spec{data-element=Value, init-value=0}, provided-interface=VeCITR_b_TBM_ExtChrgTarget1FA
      VeCITR_Pct_TBM_ExtChrgTarget2: nonqueued-sender-com-spec{data-element=Value, init-value=0}, provided-interface=VeCITR_Pct_TBM_ExtChrgTarget2
      VeCITR_b_TBM_ExtChrgTarget2FA: nonqueued-sender-com-spec{data-element=Value, init-value=0}, provided-interface=VeCITR_b_TBM_ExtChrgTarget2FA
      VeCITR_Pct_TBM_ImmChrgTarget1: nonqueued-sender-com-spec{data-element=Value, init-value=0}, provided-interface=VeCITR_Pct_TBM_ImmChrgTarget1
      VeCITR_b_TBM_ImmChrgTarget1FA: nonqueued-sender-com-spec{data-element=Value, init-value=0}, provided-interface=VeCITR_b_TBM_ImmChrgTarget1FA
      VeCITR_Pct_TBM_ImmChrgTarget2: nonqueued-sender-com-spec{data-element=Value, init-value=0}, provided-interface=VeCITR_Pct_TBM_ImmChrgTarget2
      VeCITR_b_TBM_ImmChrgTarget2FA: nonqueued-sender-com-spec{data-element=Value, init-value=0}, provided-interface=VeCITR_b_TBM_ImmChrgTarget2FA
      VeCITR_b_V2HModeReq: nonqueued-sender-com-spec{data-element=Value, init-value=0}, provided-interface=VeCITR_b_V2HModeReq
      VeCITR_b_V2HModeReqFA: nonqueued-sender-com-spec{data-element=Value, init-value=0}, provided-interface=VeCITR_b_V2HModeReqFA
      VeCITR_b_V2HReq: nonqueued-sender-com-spec{data-element=Value, init-value=0}, provided-interface=VeCITR_b_V2HReq
      VeCITR_b_V2HReqFA: nonqueued-sender-com-spec{data-element=Value, init-value=0}, provided-interface=VeCITR_b_V2HReqFA
      VeCITR_Pct_V2HRsrvBatt: nonqueued-sender-com-spec{data-element=Value, init-value=0}, provided-interface=VeCITR_Pct_V2HRsrvBatt
      VeCITR_b_V2HRsrvBattFA: nonqueued-sender-com-spec{data-element=Value, init-value=0}, provided-interface=VeCITR_b_V2HRsrvBattFA
      VeCITR_b_V2HSubmit: nonqueued-sender-com-spec{data-element=Value, init-value=0}, provided-interface=VeCITR_b_V2HSubmit
      VeCITR_b_V2HSubmitFA: nonqueued-sender-com-spec{data-element=Value, init-value=0}, provided-interface=VeCITR_b_V2HSubmitFA
      VeCITR_b_V2L_AllReq: nonqueued-sender-com-spec{data-element=Value, init-value=0}, provided-interface=VeCITR_b_V2L_AllReq
      VeCITR_b_V2L_AllReqFA: nonqueued-sender-com-spec{data-element=Value, init-value=0}, provided-interface=VeCITR_b_V2L_AllReqFA
      VeCITR_b_V2L_FrunkReq: nonqueued-sender-com-spec{data-element=Value, init-value=0}, provided-interface=VeCITR_b_V2L_FrunkReq
      VeCITR_b_V2L_FrunkReqFA: nonqueued-sender-com-spec{data-element=Value, init-value=0}, provided-interface=VeCITR_b_V2L_FrunkReqFA
      VeCITR_b_V2LModeReq: nonqueued-sender-com-spec{data-element=Value, init-value=0}, provided-interface=VeCITR_b_V2LModeReq
      VeCITR_b_V2LModeReqFA: nonqueued-sender-com-spec{data-element=Value, init-value=0}, provided-interface=VeCITR_b_V2LModeReqFA
      VeCITR_Pct_V2LRsrvBatt: nonqueued-sender-com-spec{data-element=Value, init-value=0}, provided-interface=VeCITR_Pct_V2LRsrvBatt
      VeCITR_b_V2LRsrvBattFA: nonqueued-sender-com-spec{data-element=Value, init-value=0}, provided-interface=VeCITR_b_V2LRsrvBattFA
      VeCITR_b_V2LSubmit: nonqueued-sender-com-spec{data-element=Value, init-value=0}, provided-interface=VeCITR_b_V2LSubmit
      VeCITR_b_V2LSubmitFA: nonqueued-sender-com-spec{data-element=Value, init-value=0}, provided-interface=VeCITR_b_V2LSubmitFA
      VeCITR_b_V2LTrunkReq: nonqueued-sender-com-spec{data-element=Value, init-value=0}, provided-interface=VeCITR_b_V2LTrunkReq
      VeCITR_b_V2LTrunkReqFA: nonqueued-sender-com-spec{data-element=Value, init-value=0}, provided-interface=VeCITR_b_V2LTrunkReqFA
      VeCITR_b_V2VModeReq: nonqueued-sender-com-spec{data-element=Value, init-value=0}, provided-interface=VeCITR_b_V2VModeReq
      VeCITR_b_V2VModeReqFA: nonqueued-sender-com-spec{data-element=Value, init-value=0}, provided-interface=VeCITR_b_V2VModeReqFA
      VeCITR_b_V2VReq: nonqueued-sender-com-spec{data-element=Value, init-value=0}, provided-interface=VeCITR_b_V2VReq
      VeCITR_b_V2VReqFA: nonqueued-sender-com-spec{data-element=Value, init-value=0}, provided-interface=VeCITR_b_V2VReqFA
      VeCITR_Pct_V2VRsrvBatt: nonqueued-sender-com-spec{data-element=Value, init-value=0}, provided-interface=VeCITR_Pct_V2VRsrvBatt
      VeCITR_b_V2VRsrvBattFA: nonqueued-sender-com-spec{data-element=Value, init-value=0}, provided-interface=VeCITR_b_V2VRsrvBattFA
      VeCITR_b_V2VSubmit: nonqueued-sender-com-spec{data-element=Value, init-value=0}, provided-interface=VeCITR_b_V2VSubmit
      VeCITR_b_V2VSubmitFA: nonqueued-sender-com-spec{data-element=Value, init-value=0}, provided-interface=VeCITR_b_V2VSubmitFA
      VeCITR_I_PPCurrentDrawSens1: nonqueued-sender-com-spec{data-element=Value, init-value=0}, provided-interface=VeCITR_I_PPCurrentDrawSens1
      VeCITR_b_PPCurrentDrawSens1FA: nonqueued-sender-com-spec{data-element=Value, init-value=0}, provided-interface=VeCITR_b_PPCurrentDrawSens1FA
      VeCITR_b_PPButtonSts: nonqueued-sender-com-spec{data-element=Value, init-value=0}, provided-interface=VeCITR_b_PPButtonSts
      VeCITR_b_PPButtonStsFA: nonqueued-sender-com-spec{data-element=Value, init-value=0}, provided-interface=VeCITR_b_PPButtonStsFA
      VeCITR_b_PPLidSwitchSts120A: nonqueued-sender-com-spec{data-element=Value, init-value=0}, provided-interface=VeCITR_b_PPLidSwitchSts120A
      VeCITR_b_PPLidSwitchSts120AFA: nonqueued-sender-com-spec{data-element=Value, init-value=0}, provided-interface=VeCITR_b_PPLidSwitchSts120AFA
      VeCITR_b_PPLidSwitchSts120B: nonqueued-sender-com-spec{data-element=Value, init-value=0}, provided-interface=VeCITR_b_PPLidSwitchSts120B
      VeCITR_b_PPLidSwitchSts120BFA: nonqueued-sender-com-spec{data-element=Value, init-value=0}, provided-interface=VeCITR_b_PPLidSwitchSts120BFA
      VeCITR_b_PPLidSwitchSts240: nonqueued-sender-com-spec{data-element=Value, init-value=0}, provided-interface=VeCITR_b_PPLidSwitchSts240
      VeCITR_b_PPLidSwitchSts240FA: nonqueued-sender-com-spec{data-element=Value, init-value=0}, provided-interface=VeCITR_b_PPLidSwitchSts240FA
      VeCITR_b_PPACPresentSens1: nonqueued-sender-com-spec{data-element=Value, init-value=0}, provided-interface=VeCITR_b_PPACPresentSens1
      VeCITR_b_PPACPresentSens1FA: nonqueued-sender-com-spec{data-element=Value, init-value=0}, provided-interface=VeCITR_b_PPACPresentSens1FA
      VeCITR_b_PPACPresentSens2: nonqueued-sender-com-spec{data-element=Value, init-value=0}, provided-interface=VeCITR_b_PPACPresentSens2
      VeCITR_b_PPACPresentSens2FA: nonqueued-sender-com-spec{data-element=Value, init-value=0}, provided-interface=VeCITR_b_PPACPresentSens2FA
      VeCITR_I_PPCurrentDrawSens2: nonqueued-sender-com-spec{data-element=Value, init-value=0}, provided-interface=VeCITR_I_PPCurrentDrawSens2
      VeCITR_b_PPCurrentDrawSens2FA: nonqueued-sender-com-spec{data-element=Value, init-value=0}, provided-interface=VeCITR_b_PPCurrentDrawSens2FA
      VeCITR_e_PPFaultRsn: nonqueued-sender-com-spec{data-element=Value, init-value=CeCITR_e_No_Fault}, provided-interface=VeCITR_e_PPFaultRsn
      VeCITR_b_PPFaultRsnFA: nonqueued-sender-com-spec{data-element=Value, init-value=0}, provided-interface=VeCITR_b_PPFaultRsnFA
      VeCITR_e_PPFault: nonqueued-sender-com-spec{data-element=Value, init-value=CeVTLR_e_NoFault}, provided-interface=VeCITR_e_PPFault
      VeCITR_b_PPFaultFA: nonqueued-sender-com-spec{data-element=Value, init-value=0}, provided-interface=VeCITR_b_PPFaultFA
      VeCITR_e_PPLEDFault: nonqueued-sender-com-spec{data-element=Value, init-value=CeCITR_e_LED_No_Fault}, provided-interface=VeCITR_e_PPLEDFault
      VeCITR_b_PPLEDFaultFA: nonqueued-sender-com-spec{data-element=Value, init-value=0}, provided-interface=VeCITR_b_PPLEDFaultFA
      VeCITR_b_RsErrSPP: nonqueued-sender-com-spec{data-element=Value, init-value=0}, provided-interface=VeCITR_b_RsErrSPP
      VeCITR_b_RsErrSPPFA: nonqueued-sender-com-spec{data-element=Value, init-value=0}, provided-interface=VeCITR_b_RsErrSPPFA
      VeCITR_P_PPRatedPower: nonqueued-sender-com-spec{data-element=Value, init-value=0}, provided-interface=VeCITR_P_PPRatedPower
      VeCITR_b_PPRatedPowerFA: nonqueued-sender-com-spec{data-element=Value, init-value=0}, provided-interface=VeCITR_b_PPRatedPowerFA
      VeCITR_I_PP2CurrentDrawSens1: nonqueued-sender-com-spec{data-element=Value, init-value=0}, provided-interface=VeCITR_I_PP2CurrentDrawSens1
      VeCITR_b_PP2CurrentDrawSens1FA: nonqueued-sender-com-spec{data-element=Value, init-value=0}, provided-interface=VeCITR_b_PP2CurrentDrawSens1FA
      VeCITR_b_PP2ButtonSts: nonqueued-sender-com-spec{data-element=Value, init-value=0}, provided-interface=VeCITR_b_PP2ButtonSts
      VeCITR_b_PP2ButtonStsFA: nonqueued-sender-com-spec{data-element=Value, init-value=0}, provided-interface=VeCITR_b_PP2ButtonStsFA
      VeCITR_b_PP2LidSwitchSts120A: nonqueued-sender-com-spec{data-element=Value, init-value=0}, provided-interface=VeCITR_b_PP2LidSwitchSts120A
      VeCITR_b_PP2LidSwitchSts120AFA: nonqueued-sender-com-spec{data-element=Value, init-value=0}, provided-interface=VeCITR_b_PP2LidSwitchSts120AFA
      VeCITR_b_PP2LidSwitchSts120B: nonqueued-sender-com-spec{data-element=Value, init-value=0}, provided-interface=VeCITR_b_PP2LidSwitchSts120B
      VeCITR_b_PP2LidSwitchSts120BFA: nonqueued-sender-com-spec{data-element=Value, init-value=0}, provided-interface=VeCITR_b_PP2LidSwitchSts120BFA
      VeCITR_b_PP2LidSwitchSts240: nonqueued-sender-com-spec{data-element=Value, init-value=0}, provided-interface=VeCITR_b_PP2LidSwitchSts240
      VeCITR_b_PP2LidSwitchSts240FA: nonqueued-sender-com-spec{data-element=Value, init-value=0}, provided-interface=VeCITR_b_PP2LidSwitchSts240FA
      VeCITR_b_PP2ACPresentSens1: nonqueued-sender-com-spec{data-element=Value, init-value=0}, provided-interface=VeCITR_b_PP2ACPresentSens1
      VeCITR_b_PP2ACPresentSens1FA: nonqueued-sender-com-spec{data-element=Value, init-value=0}, provided-interface=VeCITR_b_PP2ACPresentSens1FA
      VeCITR_b_PP2ACPresentSens2: nonqueued-sender-com-spec{data-element=Value, init-value=0}, provided-interface=VeCITR_b_PP2ACPresentSens2
      VeCITR_b_PP2ACPresentSens2FA: nonqueued-sender-com-spec{data-element=Value, init-value=0}, provided-interface=VeCITR_b_PP2ACPresentSens2FA
      VeCITR_I_PP2CurrentDrawSens2: nonqueued-sender-com-spec{data-element=Value, init-value=0}, provided-interface=VeCITR_I_PP2CurrentDrawSens2
      VeCITR_b_PP2CurrentDrawSens2FA: nonqueued-sender-com-spec{data-element=Value, init-value=0}, provided-interface=VeCITR_b_PP2CurrentDrawSens2FA
      VeCITR_e_PP2FaultRsn: nonqueued-sender-com-spec{data-element=Value, init-value=CeCITR_e_No_Fault}, provided-interface=VeCITR_e_PP2FaultRsn
      VeCITR_b_PP2FaultRsnFA: nonqueued-sender-com-spec{data-element=Value, init-value=0}, provided-interface=VeCITR_b_PP2FaultRsnFA
      VeCITR_e_PP2Fault: nonqueued-sender-com-spec{data-element=Value, init-value=CeVTLR_e_NoFaultPP2}, provided-interface=VeCITR_e_PP2Fault
      VeCITR_b_PP2FaultFA: nonqueued-sender-com-spec{data-element=Value, init-value=0}, provided-interface=VeCITR_b_PP2FaultFA
      VeCITR_e_PP2LEDFault: nonqueued-sender-com-spec{data-element=Value, init-value=CeCITR_e_LED_No_Fault}, provided-interface=VeCITR_e_PP2LEDFault
      VeCITR_b_PP2LEDFaultFA: nonqueued-sender-com-spec{data-element=Value, init-value=0}, provided-interface=VeCITR_b_PP2LEDFaultFA
      VeCITR_b_RsErrSPP2: nonqueued-sender-com-spec{data-element=Value, init-value=0}, provided-interface=VeCITR_b_RsErrSPP2
      VeCITR_b_RsErrSPP2FA: nonqueued-sender-com-spec{data-element=Value, init-value=0}, provided-interface=VeCITR_b_RsErrSPP2FA
      VeCITR_P_PP2RatedPower: nonqueued-sender-com-spec{data-element=Value, init-value=0}, provided-interface=VeCITR_P_PP2RatedPower
      VeCITR_b_PP2RatedPowerFA: nonqueued-sender-com-spec{data-element=Value, init-value=0}, provided-interface=VeCITR_b_PP2RatedPowerFA
      VeCITR_e_PP_LED_A_Feedback: nonqueued-sender-com-spec{data-element=Value, init-value=CeCITR_e_CPIM_Ind_Off}, provided-interface=VeCITR_e_PP_LED_A_Feedback
      VeCITR_b_PP_LED_A_Feedback_FA: nonqueued-sender-com-spec{data-element=Value, init-value=0}, provided-interface=VeCITR_b_PP_LED_A_Feedback_FA
      VeCITR_e_PP_LED_B_Feedback: nonqueued-sender-com-spec{data-element=Value, init-value=CeCITR_e_CPIM_Ind_Off}, provided-interface=VeCITR_e_PP_LED_B_Feedback
      VeCITR_b_PP_LED_B_Feedback_FA: nonqueued-sender-com-spec{data-element=Value, init-value=0}, provided-interface=VeCITR_b_PP_LED_B_Feedback_FA
      VeCITR_e_PP_LED_C_Feedback: nonqueued-sender-com-spec{data-element=Value, init-value=CeCITR_e_CPIM_Ind_Off}, provided-interface=VeCITR_e_PP_LED_C_Feedback
      VeCITR_b_PP_LED_C_Feedback_FA: nonqueued-sender-com-spec{data-element=Value, init-value=0}, provided-interface=VeCITR_b_PP_LED_C_Feedback_FA
      VeCITR_e_PP_LED_A_FailStatus: nonqueued-sender-com-spec{data-element=Value, init-value=CeCITR_e_CPIM_LEDNormal}, provided-interface=VeCITR_e_PP_LED_A_FailStatus
      VeCITR_b_PP_LED_A_FailStatus_FA: nonqueued-sender-com-spec{data-element=Value, init-value=0}, provided-interface=VeCITR_b_PP_LED_A_FailStatus_FA
      VeCITR_e_PP_LED_B_FailStatus: nonqueued-sender-com-spec{data-element=Value, init-value=CeCITR_e_CPIM_LEDNormal}, provided-interface=VeCITR_e_PP_LED_B_FailStatus
      VeCITR_b_PP_LED_B_FailStatus_FA: nonqueued-sender-com-spec{data-element=Value, init-value=0}, provided-interface=VeCITR_b_PP_LED_B_FailStatus_FA
      VeCITR_e_PP_LED_C_FailStatus: nonqueued-sender-com-spec{data-element=Value, init-value=CeCITR_e_CPIM_LEDNormal}, provided-interface=VeCITR_e_PP_LED_C_FailStatus
      VeCITR_b_PP_LED_C_FailStatus_FA: nonqueued-sender-com-spec{data-element=Value, init-value=0}, provided-interface=VeCITR_b_PP_LED_C_FailStatus_FA
      VeCITR_e_PP_LED_A_Color_Feedback: nonqueued-sender-com-spec{data-element=Value, init-value=CeCITR_e_PP_LED_Color_Init}, provided-interface=VeCITR_e_PP_LED_A_Color_Feedback
      VeCITR_b_PP_LED_A_Color_Feedback_FA: nonqueued-sender-com-spec{data-element=Value, init-value=0}, provided-interface=VeCITR_b_PP_LED_A_Color_Feedback_FA
      VeCITR_e_PP_LED_B_Color_Feedback: nonqueued-sender-com-spec{data-element=Value, init-value=CeCITR_e_PP_LED_Color_Init}, provided-interface=VeCITR_e_PP_LED_B_Color_Feedback
      VeCITR_b_PP_LED_B_Color_Feedback_FA: nonqueued-sender-com-spec{data-element=Value, init-value=0}, provided-interface=VeCITR_b_PP_LED_B_Color_Feedback_FA
      VeCITR_e_PP_LED_C_Color_Feedback: nonqueued-sender-com-spec{data-element=Value, init-value=CeCITR_e_PP_LED_Color_Init}, provided-interface=VeCITR_e_PP_LED_C_Color_Feedback
      VeCITR_b_PP_LED_C_Color_Feedback_FA: nonqueued-sender-com-spec{data-element=Value, init-value=0}, provided-interface=VeCITR_b_PP_LED_C_Color_Feedback_FA
      VeCITR_b_PP_LIN_Checksum_Error: nonqueued-sender-com-spec{data-element=Value, init-value=0}, provided-interface=VeCITR_b_PP_LIN_Checksum_Error
      VeCITR_b_PP_LIN_Checksum_Error_FA: nonqueued-sender-com-spec{data-element=Value, init-value=0}, provided-interface=VeCITR_b_PP_LIN_Checksum_Error_FA
      VeCITR_b_PP_LIN_Data_Error: nonqueued-sender-com-spec{data-element=Value, init-value=0}, provided-interface=VeCITR_b_PP_LIN_Data_Error
      VeCITR_b_PP_LIN_Data_Error_FA: nonqueued-sender-com-spec{data-element=Value, init-value=0}, provided-interface=VeCITR_b_PP_LIN_Data_Error_FA
      VeCITR_b_PP_LIN_Parity_Error: nonqueued-sender-com-spec{data-element=Value, init-value=0}, provided-interface=VeCITR_b_PP_LIN_Parity_Error
      VeCITR_b_PP_LIN_Parity_Error_FA: nonqueued-sender-com-spec{data-element=Value, init-value=0}, provided-interface=VeCITR_b_PP_LIN_Parity_Error_FA
      VeCITR_b_PP_Gnd_Fault_Detected: nonqueued-sender-com-spec{data-element=Value, init-value=0}, provided-interface=VeCITR_b_PP_Gnd_Fault_Detected
      VeCITR_b_PP_Gnd_Fault_Detected_FA: nonqueued-sender-com-spec{data-element=Value, init-value=0}, provided-interface=VeCITR_b_PP_Gnd_Fault_Detected_FA
      VeCITR_b_PP2_LIN_Checksum_Error: nonqueued-sender-com-spec{data-element=Value, init-value=0}, provided-interface=VeCITR_b_PP2_LIN_Checksum_Error
      VeCITR_b_PP2_LIN_Checksum_Error_FA: nonqueued-sender-com-spec{data-element=Value, init-value=0}, provided-interface=VeCITR_b_PP2_LIN_Checksum_Error_FA
      VeCITR_b_PP2_LIN_Data_Error: nonqueued-sender-com-spec{data-element=Value, init-value=0}, provided-interface=VeCITR_b_PP2_LIN_Data_Error
      VeCITR_b_PP2_LIN_Data_Error_FA: nonqueued-sender-com-spec{data-element=Value, init-value=0}, provided-interface=VeCITR_b_PP2_LIN_Data_Error_FA
      VeCITR_b_PP2_LIN_Parity_Error: nonqueued-sender-com-spec{data-element=Value, init-value=0}, provided-interface=VeCITR_b_PP2_LIN_Parity_Error
      VeCITR_b_PP2_LIN_Parity_Error_FA: nonqueued-sender-com-spec{data-element=Value, init-value=0}, provided-interface=VeCITR_b_PP2_LIN_Parity_Error_FA
      VeCITR_b_PP2_Gnd_Fault_Detected: nonqueued-sender-com-spec{data-element=Value, init-value=0}, provided-interface=VeCITR_b_PP2_Gnd_Fault_Detected
      VeCITR_b_PP2_Gnd_Fault_Detected_FA: nonqueued-sender-com-spec{data-element=Value, init-value=0}, provided-interface=VeCITR_b_PP2_Gnd_Fault_Detected_FA
      VeCITR_e_PP2_LED_A_Feedback: nonqueued-sender-com-spec{data-element=Value, init-value=CeCITR_e_CPIM_Ind_Off}, provided-interface=VeCITR_e_PP2_LED_A_Feedback
      VeCITR_b_PP2_LED_A_Feedback_FA: nonqueued-sender-com-spec{data-element=Value, init-value=0}, provided-interface=VeCITR_b_PP2_LED_A_Feedback_FA
      VeCITR_e_PP2_LED_B_Feedback: nonqueued-sender-com-spec{data-element=Value, init-value=CeCITR_e_CPIM_Ind_Off}, provided-interface=VeCITR_e_PP2_LED_B_Feedback
      VeCITR_b_PP2_LED_B_Feedback_FA: nonqueued-sender-com-spec{data-element=Value, init-value=0}, provided-interface=VeCITR_b_PP2_LED_B_Feedback_FA
      VeCITR_e_PP2_LED_A_FailStatus: nonqueued-sender-com-spec{data-element=Value, init-value=CeCITR_e_CPIM_LEDNormal}, provided-interface=VeCITR_e_PP2_LED_A_FailStatus
      VeCITR_b_PP2_LED_A_FailStatus_FA: nonqueued-sender-com-spec{data-element=Value, init-value=0}, provided-interface=VeCITR_b_PP2_LED_A_FailStatus_FA
      VeCITR_e_PP2_LED_B_FailStatus: nonqueued-sender-com-spec{data-element=Value, init-value=CeCITR_e_CPIM_LEDNormal}, provided-interface=VeCITR_e_PP2_LED_B_FailStatus
      VeCITR_b_PP2_LED_B_FailStatus_FA: nonqueued-sender-com-spec{data-element=Value, init-value=0}, provided-interface=VeCITR_b_PP2_LED_B_FailStatus_FA
      VeCITR_e_PP2_LED_A_Color_Feedback: nonqueued-sender-com-spec{data-element=Value, init-value=CeCITR_e_PP_LED_Color_Init}, provided-interface=VeCITR_e_PP2_LED_A_Color_Feedback
      VeCITR_b_PP2_LED_A_Color_Feedback_FA: nonqueued-sender-com-spec{data-element=Value, init-value=0}, provided-interface=VeCITR_b_PP2_LED_A_Color_Feedback_FA
      VeCITR_e_PP2_LED_B_Color_Feedback: nonqueued-sender-com-spec{data-element=Value, init-value=CeCITR_e_PP_LED_Color_Init}, provided-interface=VeCITR_e_PP2_LED_B_Color_Feedback
      VeCITR_b_PP2_LED_B_Color_Feedback_FA: nonqueued-sender-com-spec{data-element=Value, init-value=0}, provided-interface=VeCITR_b_PP2_LED_B_Color_Feedback_FA
      FsftCITR_I_PP2CurrentDrawSens1: server-com-spec=FsftCITR_I_PP2CurrentDrawSens1, provided-interface=FsftCITR_I_PP2CurrentDrawSens1
      FsftCITR_I_PP2CurrentDrawSens2: server-com-spec=FsftCITR_I_PP2CurrentDrawSens2, provided-interface=FsftCITR_I_PP2CurrentDrawSens2
      FsftCITR_I_PPCurrentDrawSens1: server-com-spec=FsftCITR_I_PPCurrentDrawSens1, provided-interface=FsftCITR_I_PPCurrentDrawSens1
      FsftCITR_I_PPCurrentDrawSens2: server-com-spec=FsftCITR_I_PPCurrentDrawSens2, provided-interface=FsftCITR_I_PPCurrentDrawSens2
      FsftCITR_P_ChargingDestinationPwr: server-com-spec=FsftCITR_P_ChargingDestinationPwr, provided-interface=FsftCITR_P_ChargingDestinationPwr
      FsftCITR_P_PP2RatedPower: server-com-spec=FsftCITR_P_PP2RatedPower, provided-interface=FsftCITR_P_PP2RatedPower
      FsftCITR_P_PPRatedPower: server-com-spec=FsftCITR_P_PPRatedPower, provided-interface=FsftCITR_P_PPRatedPower
      FsftCITR_Pct_HU_ExtChrgTarget1: server-com-spec=FsftCITR_Pct_HU_ExtChrgTarget1, provided-interface=FsftCITR_Pct_HU_ExtChrgTarget1
      FsftCITR_Pct_HU_ExtChrgTarget2: server-com-spec=FsftCITR_Pct_HU_ExtChrgTarget2, provided-interface=FsftCITR_Pct_HU_ExtChrgTarget2
      FsftCITR_Pct_HU_ImmChrgTarget1: server-com-spec=FsftCITR_Pct_HU_ImmChrgTarget1, provided-interface=FsftCITR_Pct_HU_ImmChrgTarget1
      FsftCITR_Pct_HU_ImmChrgTarget2: server-com-spec=FsftCITR_Pct_HU_ImmChrgTarget2, provided-interface=FsftCITR_Pct_HU_ImmChrgTarget2
      FsftCITR_Pct_TBM_ExtChrgTarget1: server-com-spec=FsftCITR_Pct_TBM_ExtChrgTarget1, provided-interface=FsftCITR_Pct_TBM_ExtChrgTarget1
      FsftCITR_Pct_TBM_ExtChrgTarget2: server-com-spec=FsftCITR_Pct_TBM_ExtChrgTarget2, provided-interface=FsftCITR_Pct_TBM_ExtChrgTarget2
      FsftCITR_Pct_TBM_ImmChrgTarget1: server-com-spec=FsftCITR_Pct_TBM_ImmChrgTarget1, provided-interface=FsftCITR_Pct_TBM_ImmChrgTarget1
      FsftCITR_Pct_TBM_ImmChrgTarget2: server-com-spec=FsftCITR_Pct_TBM_ImmChrgTarget2, provided-interface=FsftCITR_Pct_TBM_ImmChrgTarget2
      FsftCITR_Pct_V2HRsrvBatt: server-com-spec=FsftCITR_Pct_V2HRsrvBatt, provided-interface=FsftCITR_Pct_V2HRsrvBatt
      FsftCITR_Pct_V2LRsrvBatt: server-com-spec=FsftCITR_Pct_V2LRsrvBatt, provided-interface=FsftCITR_Pct_V2LRsrvBatt
      FsftCITR_Pct_V2VRsrvBatt: server-com-spec=FsftCITR_Pct_V2VRsrvBatt, provided-interface=FsftCITR_Pct_V2VRsrvBatt
      FsftCITR_b_ChrgPortDoor_Sts: server-com-spec=FsftCITR_b_ChrgPortDoor_Sts, provided-interface=FsftCITR_b_ChrgPortDoor_Sts
      FsftCITR_b_ChrgPortLock_StsC: server-com-spec=FsftCITR_b_ChrgPortLock_StsC, provided-interface=FsftCITR_b_ChrgPortLock_StsC
      FsftCITR_b_ChrgPort_BCM_Cmd: server-com-spec=FsftCITR_b_ChrgPort_BCM_Cmd, provided-interface=FsftCITR_b_ChrgPort_BCM_Cmd
      FsftCITR_b_CoopCh_VehLocation: server-com-spec=FsftCITR_b_CoopCh_VehLocation, provided-interface=FsftCITR_b_CoopCh_VehLocation
      FsftCITR_b_DC_PwrLev: server-com-spec=FsftCITR_b_DC_PwrLev, provided-interface=FsftCITR_b_DC_PwrLev
      FsftCITR_b_DateTmDay: server-com-spec=FsftCITR_b_DateTmDay, provided-interface=FsftCITR_b_DateTmDay
      FsftCITR_b_DateTmFormat: server-com-spec=FsftCITR_b_DateTmFormat, provided-interface=FsftCITR_b_DateTmFormat
      FsftCITR_b_Date_Day1: server-com-spec=FsftCITR_b_Date_Day1, provided-interface=FsftCITR_b_Date_Day1
      FsftCITR_b_HU_Sch1_CabTemp: server-com-spec=FsftCITR_b_HU_Sch1_CabTemp, provided-interface=FsftCITR_b_HU_Sch1_CabTemp
      FsftCITR_b_HU_Sch1_Day: server-com-spec=FsftCITR_b_HU_Sch1_Day, provided-interface=FsftCITR_b_HU_Sch1_Day
      FsftCITR_b_HU_Sch1_End_Time_Hr: server-com-spec=FsftCITR_b_HU_Sch1_End_Time_Hr, provided-interface=FsftCITR_b_HU_Sch1_End_Time_Hr
      FsftCITR_b_HU_Sch1_End_Time_Min: server-com-spec=FsftCITR_b_HU_Sch1_End_Time_Min, provided-interface=FsftCITR_b_HU_Sch1_End_Time_Min
      FsftCITR_b_HU_Sch1_Start_Time_Hr: server-com-spec=FsftCITR_b_HU_Sch1_Start_Time_Hr, provided-interface=FsftCITR_b_HU_Sch1_Start_Time_Hr
      FsftCITR_b_HU_Sch1_Start_Time_Min: server-com-spec=FsftCITR_b_HU_Sch1_Start_Time_Min, provided-interface=FsftCITR_b_HU_Sch1_Start_Time_Min
      FsftCITR_b_HU_Sch1_Type: server-com-spec=FsftCITR_b_HU_Sch1_Type, provided-interface=FsftCITR_b_HU_Sch1_Type
      FsftCITR_b_HU_Sch2_CabTemp: server-com-spec=FsftCITR_b_HU_Sch2_CabTemp, provided-interface=FsftCITR_b_HU_Sch2_CabTemp
      FsftCITR_b_HU_Sch2_Day: server-com-spec=FsftCITR_b_HU_Sch2_Day, provided-interface=FsftCITR_b_HU_Sch2_Day
      FsftCITR_b_HU_Sch2_End_Time_Hr: server-com-spec=FsftCITR_b_HU_Sch2_End_Time_Hr, provided-interface=FsftCITR_b_HU_Sch2_End_Time_Hr
      FsftCITR_b_HU_Sch2_End_Time_Min: server-com-spec=FsftCITR_b_HU_Sch2_End_Time_Min, provided-interface=FsftCITR_b_HU_Sch2_End_Time_Min
      FsftCITR_b_HU_Sch2_Start_Time_Hr: server-com-spec=FsftCITR_b_HU_Sch2_Start_Time_Hr, provided-interface=FsftCITR_b_HU_Sch2_Start_Time_Hr
      FsftCITR_b_HU_Sch2_Start_Time_Min: server-com-spec=FsftCITR_b_HU_Sch2_Start_Time_Min, provided-interface=FsftCITR_b_HU_Sch2_Start_Time_Min
      FsftCITR_b_HU_Sch2_Type: server-com-spec=FsftCITR_b_HU_Sch2_Type, provided-interface=FsftCITR_b_HU_Sch2_Type
      FsftCITR_b_HU_Sch3_Allow: server-com-spec=FsftCITR_b_HU_Sch3_Allow, provided-interface=FsftCITR_b_HU_Sch3_Allow
      FsftCITR_b_HU_Sch3_CabTemp: server-com-spec=FsftCITR_b_HU_Sch3_CabTemp, provided-interface=FsftCITR_b_HU_Sch3_CabTemp
      FsftCITR_b_HU_Sch3_Day: server-com-spec=FsftCITR_b_HU_Sch3_Day, provided-interface=FsftCITR_b_HU_Sch3_Day
      FsftCITR_b_HU_Sch3_End_Time_Hr: server-com-spec=FsftCITR_b_HU_Sch3_End_Time_Hr, provided-interface=FsftCITR_b_HU_Sch3_End_Time_Hr
      FsftCITR_b_HU_Sch3_End_Time_Min: server-com-spec=FsftCITR_b_HU_Sch3_End_Time_Min, provided-interface=FsftCITR_b_HU_Sch3_End_Time_Min
      FsftCITR_b_HU_Sch3_Start_Time_Hr: server-com-spec=FsftCITR_b_HU_Sch3_Start_Time_Hr, provided-interface=FsftCITR_b_HU_Sch3_Start_Time_Hr
      FsftCITR_b_HU_Sch3_Start_Time_Min: server-com-spec=FsftCITR_b_HU_Sch3_Start_Time_Min, provided-interface=FsftCITR_b_HU_Sch3_Start_Time_Min
      FsftCITR_b_HU_Sch3_Type: server-com-spec=FsftCITR_b_HU_Sch3_Type, provided-interface=FsftCITR_b_HU_Sch3_Type
      FsftCITR_b_HU_Sch4_Allow: server-com-spec=FsftCITR_b_HU_Sch4_Allow, provided-interface=FsftCITR_b_HU_Sch4_Allow
      FsftCITR_b_HU_Sch4_CabTemp: server-com-spec=FsftCITR_b_HU_Sch4_CabTemp, provided-interface=FsftCITR_b_HU_Sch4_CabTemp
      FsftCITR_b_HU_Sch4_Day: server-com-spec=FsftCITR_b_HU_Sch4_Day, provided-interface=FsftCITR_b_HU_Sch4_Day
      FsftCITR_b_HU_Sch4_Start_Time_Hr: server-com-spec=FsftCITR_b_HU_Sch4_Start_Time_Hr, provided-interface=FsftCITR_b_HU_Sch4_Start_Time_Hr
      FsftCITR_b_HU_Sch4_Start_Time_Min: server-com-spec=FsftCITR_b_HU_Sch4_Start_Time_Min, provided-interface=FsftCITR_b_HU_Sch4_Start_Time_Min
      FsftCITR_b_PP2ACPresentSens1: server-com-spec=FsftCITR_b_PP2ACPresentSens1, provided-interface=FsftCITR_b_PP2ACPresentSens1
      FsftCITR_b_PP2ACPresentSens2: server-com-spec=FsftCITR_b_PP2ACPresentSens2, provided-interface=FsftCITR_b_PP2ACPresentSens2
      FsftCITR_b_PP2ButtonSts: server-com-spec=FsftCITR_b_PP2ButtonSts, provided-interface=FsftCITR_b_PP2ButtonSts
      FsftCITR_b_PP2LidSwitchSts240: server-com-spec=FsftCITR_b_PP2LidSwitchSts240, provided-interface=FsftCITR_b_PP2LidSwitchSts240
      FsftCITR_b_PP2LidSwitchSts120A: server-com-spec=FsftCITR_b_PP2LidSwitchSts120A, provided-interface=FsftCITR_b_PP2LidSwitchSts120A
      FsftCITR_b_PP2LidSwitchSts120B: server-com-spec=FsftCITR_b_PP2LidSwitchSts120B, provided-interface=FsftCITR_b_PP2LidSwitchSts120B
      FsftCITR_b_PP2_Gnd_Fault_Det: server-com-spec=FsftCITR_b_PP2_Gnd_Fault_Det, provided-interface=FsftCITR_b_PP2_Gnd_Fault_Det
      FsftCITR_b_PP2_LIN_Cksm_Err: server-com-spec=FsftCITR_b_PP2_LIN_Cksm_Err, provided-interface=FsftCITR_b_PP2_LIN_Cksm_Err
      FsftCITR_b_PP2_LIN_Data_Err: server-com-spec=FsftCITR_b_PP2_LIN_Data_Err, provided-interface=FsftCITR_b_PP2_LIN_Data_Err
      FsftCITR_b_PP2_LIN_Parity_Err: server-com-spec=FsftCITR_b_PP2_LIN_Parity_Err, provided-interface=FsftCITR_b_PP2_LIN_Parity_Err
      FsftCITR_b_PPACPresentSens1: server-com-spec=FsftCITR_b_PPACPresentSens1, provided-interface=FsftCITR_b_PPACPresentSens1
      FsftCITR_b_PPACPresentSens2: server-com-spec=FsftCITR_b_PPACPresentSens2, provided-interface=FsftCITR_b_PPACPresentSens2
      FsftCITR_b_PPButtonSts: server-com-spec=FsftCITR_b_PPButtonSts, provided-interface=FsftCITR_b_PPButtonSts
      FsftCITR_b_PPLidSwitchSts120A: server-com-spec=FsftCITR_b_PPLidSwitchSts120A, provided-interface=FsftCITR_b_PPLidSwitchSts120A
      FsftCITR_b_PPLidSwitchSts120B: server-com-spec=FsftCITR_b_PPLidSwitchSts120B, provided-interface=FsftCITR_b_PPLidSwitchSts120B
      FsftCITR_b_PPLidSwitchSts240: server-com-spec=FsftCITR_b_PPLidSwitchSts240, provided-interface=FsftCITR_b_PPLidSwitchSts240
      FsftCITR_b_PP_Gnd_Fault_Det: server-com-spec=FsftCITR_b_PP_Gnd_Fault_Det, provided-interface=FsftCITR_b_PP_Gnd_Fault_Det
      FsftCITR_b_PP_LIN_Cksm_Err: server-com-spec=FsftCITR_b_PP_LIN_Cksm_Err, provided-interface=FsftCITR_b_PP_LIN_Cksm_Err
      FsftCITR_b_PP_LIN_Data_Err: server-com-spec=FsftCITR_b_PP_LIN_Data_Err, provided-interface=FsftCITR_b_PP_LIN_Data_Err
      FsftCITR_b_PP_LIN_Parity_Err: server-com-spec=FsftCITR_b_PP_LIN_Parity_Err, provided-interface=FsftCITR_b_PP_LIN_Parity_Err
      FsftCITR_b_RsErrSPP: server-com-spec=FsftCITR_b_RsErrSPP, provided-interface=FsftCITR_b_RsErrSPP
      FsftCITR_b_RsErrSPP2: server-com-spec=FsftCITR_b_RsErrSPP2, provided-interface=FsftCITR_b_RsErrSPP2
      FsftCITR_b_SOC_Max_Lev: server-com-spec=FsftCITR_b_SOC_Max_Lev, provided-interface=FsftCITR_b_SOC_Max_Lev
      FsftCITR_b_TBMStopChrg: server-com-spec=FsftCITR_b_TBMStopChrg, provided-interface=FsftCITR_b_TBMStopChrg
      FsftCITR_b_TBM_Sch1_CabTemp: server-com-spec=FsftCITR_b_TBM_Sch1_CabTemp, provided-interface=FsftCITR_b_TBM_Sch1_CabTemp
      FsftCITR_b_TBM_Sch1_Day: server-com-spec=FsftCITR_b_TBM_Sch1_Day, provided-interface=FsftCITR_b_TBM_Sch1_Day
      FsftCITR_b_TBM_Sch1_End_Time_Hr: server-com-spec=FsftCITR_b_TBM_Sch1_End_Time_Hr, provided-interface=FsftCITR_b_TBM_Sch1_End_Time_Hr
      FsftCITR_b_TBM_Sch1_End_Time_Min: server-com-spec=FsftCITR_b_TBM_Sch1_End_Time_Min, provided-interface=FsftCITR_b_TBM_Sch1_End_Time_Min
      FsftCITR_b_TBM_Sch1_Start_Time_Hr: server-com-spec=FsftCITR_b_TBM_Sch1_Start_Time_Hr, provided-interface=FsftCITR_b_TBM_Sch1_Start_Time_Hr
      FsftCITR_b_TBM_Sch1_Start_Time_Min: server-com-spec=FsftCITR_b_TBM_Sch1_Start_Time_Min, provided-interface=FsftCITR_b_TBM_Sch1_Start_Time_Min
      FsftCITR_b_TBM_Sch1_Type: server-com-spec=FsftCITR_b_TBM_Sch1_Type, provided-interface=FsftCITR_b_TBM_Sch1_Type
      FsftCITR_b_TBM_Sch2_CabTemp: server-com-spec=FsftCITR_b_TBM_Sch2_CabTemp, provided-interface=FsftCITR_b_TBM_Sch2_CabTemp
      FsftCITR_b_TBM_Sch2_Day: server-com-spec=FsftCITR_b_TBM_Sch2_Day, provided-interface=FsftCITR_b_TBM_Sch2_Day
      FsftCITR_b_TBM_Sch2_End_Time_Hr: server-com-spec=FsftCITR_b_TBM_Sch2_End_Time_Hr, provided-interface=FsftCITR_b_TBM_Sch2_End_Time_Hr
      FsftCITR_b_TBM_Sch2_End_Time_Min: server-com-spec=FsftCITR_b_TBM_Sch2_End_Time_Min, provided-interface=FsftCITR_b_TBM_Sch2_End_Time_Min
      FsftCITR_b_TBM_Sch2_Start_Time_Hr: server-com-spec=FsftCITR_b_TBM_Sch2_Start_Time_Hr, provided-interface=FsftCITR_b_TBM_Sch2_Start_Time_Hr
      FsftCITR_b_TBM_Sch2_Start_Time_Min: server-com-spec=FsftCITR_b_TBM_Sch2_Start_Time_Min, provided-interface=FsftCITR_b_TBM_Sch2_Start_Time_Min
      FsftCITR_b_TBM_Sch2_Type: server-com-spec=FsftCITR_b_TBM_Sch2_Type, provided-interface=FsftCITR_b_TBM_Sch2_Type
      FsftCITR_b_TBM_Sch3_Allow: server-com-spec=FsftCITR_b_TBM_Sch3_Allow, provided-interface=FsftCITR_b_TBM_Sch3_Allow
      FsftCITR_b_TBM_Sch3_CabTemp: server-com-spec=FsftCITR_b_TBM_Sch3_CabTemp, provided-interface=FsftCITR_b_TBM_Sch3_CabTemp
      FsftCITR_b_TBM_Sch3_Day: server-com-spec=FsftCITR_b_TBM_Sch3_Day, provided-interface=FsftCITR_b_TBM_Sch3_Day
      FsftCITR_b_TBM_Sch3_End_Time_Hr: server-com-spec=FsftCITR_b_TBM_Sch3_End_Time_Hr, provided-interface=FsftCITR_b_TBM_Sch3_End_Time_Hr
      FsftCITR_b_TBM_Sch3_End_Time_Min: server-com-spec=FsftCITR_b_TBM_Sch3_End_Time_Min, provided-interface=FsftCITR_b_TBM_Sch3_End_Time_Min
      FsftCITR_b_TBM_Sch3_Start_Time_Hr: server-com-spec=FsftCITR_b_TBM_Sch3_Start_Time_Hr, provided-interface=FsftCITR_b_TBM_Sch3_Start_Time_Hr
      FsftCITR_b_TBM_Sch3_Start_Time_Min: server-com-spec=FsftCITR_b_TBM_Sch3_Start_Time_Min, provided-interface=FsftCITR_b_TBM_Sch3_Start_Time_Min
      FsftCITR_b_TBM_Sch3_Type: server-com-spec=FsftCITR_b_TBM_Sch3_Type, provided-interface=FsftCITR_b_TBM_Sch3_Type
      FsftCITR_b_TBM_Sch4_Allow: server-com-spec=FsftCITR_b_TBM_Sch4_Allow, provided-interface=FsftCITR_b_TBM_Sch4_Allow
      FsftCITR_b_TBM_Sch4_CabTemp: server-com-spec=FsftCITR_b_TBM_Sch4_CabTemp, provided-interface=FsftCITR_b_TBM_Sch4_CabTemp
      FsftCITR_b_TBM_Sch4_Day: server-com-spec=FsftCITR_b_TBM_Sch4_Day, provided-interface=FsftCITR_b_TBM_Sch4_Day
      FsftCITR_b_TBM_Sch4_Start_Time_Hr: server-com-spec=FsftCITR_b_TBM_Sch4_Start_Time_Hr, provided-interface=FsftCITR_b_TBM_Sch4_Start_Time_Hr
      FsftCITR_b_TBM_Sch4_Start_Time_Min: server-com-spec=FsftCITR_b_TBM_Sch4_Start_Time_Min, provided-interface=FsftCITR_b_TBM_Sch4_Start_Time_Min
      FsftCITR_b_V2HModeReq: server-com-spec=FsftCITR_b_V2HModeReq, provided-interface=FsftCITR_b_V2HModeReq
      FsftCITR_b_V2HReq: server-com-spec=FsftCITR_b_V2HReq, provided-interface=FsftCITR_b_V2HReq
      FsftCITR_b_V2HSubmit: server-com-spec=FsftCITR_b_V2HSubmit, provided-interface=FsftCITR_b_V2HSubmit
      FsftCITR_b_V2LModeReq: server-com-spec=FsftCITR_b_V2LModeReq, provided-interface=FsftCITR_b_V2LModeReq
      FsftCITR_b_V2LSubmit: server-com-spec=FsftCITR_b_V2LSubmit, provided-interface=FsftCITR_b_V2LSubmit
      FsftCITR_b_V2LTrunkReq: server-com-spec=FsftCITR_b_V2LTrunkReq, provided-interface=FsftCITR_b_V2LTrunkReq
      FsftCITR_b_V2L_AllReq: server-com-spec=FsftCITR_b_V2L_AllReq, provided-interface=FsftCITR_b_V2L_AllReq
      FsftCITR_b_V2L_FrunkReq: server-com-spec=FsftCITR_b_V2L_FrunkReq, provided-interface=FsftCITR_b_V2L_FrunkReq
      FsftCITR_b_V2VModeReq: server-com-spec=FsftCITR_b_V2VModeReq, provided-interface=FsftCITR_b_V2VModeReq
      FsftCITR_b_V2VReq: server-com-spec=FsftCITR_b_V2VReq, provided-interface=FsftCITR_b_V2VReq
      FsftCITR_b_V2VSubmit: server-com-spec=FsftCITR_b_V2VSubmit, provided-interface=FsftCITR_b_V2VSubmit
      FsftCITR_e_BCIM_Ind{1..5}_Fdbk: server-com-spec=FsftCITR_e_BCIM_Ind{1..5}_Fdbk, provided-interface=FsftCITR_e_BCIM_Ind{1..5}_Fdbk
      FsftCITR_e_BCIM_Ind_Color_Fdbk: server-com-spec=FsftCITR_e_BCIM_Ind_Color_Fdbk, provided-interface=FsftCITR_e_BCIM_Ind_Color_Fdbk
      FsftCITR_e_CPIM_Icon1_Sts: server-com-spec=FsftCITR_e_CPIM_Icon1_Sts, provided-interface=FsftCITR_e_CPIM_Icon1_Sts
      FsftCITR_e_CPIM_Icon2_Sts: server-com-spec=FsftCITR_e_CPIM_Icon2_Sts, provided-interface=FsftCITR_e_CPIM_Icon2_Sts
      FsftCITR_e_CPIM_Ind{1..5}_Fdbk: server-com-spec=FsftCITR_e_CPIM_Ind{1..5}_Fdbk, provided-interface=FsftCITR_e_CPIM_Ind{1..5}_Fdbk
      FsftCITR_e_CPIM_Ind_Color_Fdbk: server-com-spec=FsftCITR_e_CPIM_Ind_Color_Fdbk, provided-interface=FsftCITR_e_CPIM_Ind_Color_Fdbk
      FsftCITR_e_ChrgPortLock_FailSts: server-com-spec=FsftCITR_e_ChrgPortLock_FailSts, provided-interface=FsftCITR_e_ChrgPortLock_FailSts
      FsftCITR_e_ChrgrFlapSts: server-com-spec=FsftCITR_e_ChrgrFlapSts, provided-interface=FsftCITR_e_ChrgrFlapSts
      FsftCITR_e_CoopCh_ChrgCmd: server-com-spec=FsftCITR_e_CoopCh_ChrgCmd, provided-interface=FsftCITR_e_CoopCh_ChrgCmd
      FsftCITR_e_DoorLockLastElSts: server-com-spec=FsftCITR_e_DoorLockLastElSts, provided-interface=FsftCITR_e_DoorLockLastElSts
      FsftCITR_e_DoorLockLastElSts_2: server-com-spec=FsftCITR_e_DoorLockLastElSts_2, provided-interface=FsftCITR_e_DoorLockLastElSts_2
      FsftCITR_e_FOTA_Install_Type: server-com-spec=FsftCITR_e_FOTA_Install_Type, provided-interface=FsftCITR_e_FOTA_Install_Type
      FsftCITR_e_HU_ChrgSchedType1: server-com-spec=FsftCITR_e_HU_ChrgSchedType1, provided-interface=FsftCITR_e_HU_ChrgSchedType1
      FsftCITR_e_HU_ChrgSchedType2: server-com-spec=FsftCITR_e_HU_ChrgSchedType2, provided-interface=FsftCITR_e_HU_ChrgSchedType2
      FsftCITR_e_PP2Fault: server-com-spec=FsftCITR_e_PP2Fault, provided-interface=FsftCITR_e_PP2Fault
      FsftCITR_e_PP2FaultRsn: server-com-spec=FsftCITR_e_PP2FaultRsn, provided-interface=FsftCITR_e_PP2FaultRsn
      FsftCITR_e_PP2LEDFault: server-com-spec=FsftCITR_e_PP2LEDFault, provided-interface=FsftCITR_e_PP2LEDFault
      FsftCITR_e_PP2_LED_A_ColorFeedback: server-com-spec=FsftCITR_e_PP2_LED_A_ColorFeedback, provided-interface=FsftCITR_e_PP2_LED_A_ColorFeedback
      FsftCITR_e_PP2_LED_A_FailSts: server-com-spec=FsftCITR_e_PP2_LED_A_FailSts, provided-interface=FsftCITR_e_PP2_LED_A_FailSts
      FsftCITR_e_PP2_LED_A_Feedback: server-com-spec=FsftCITR_e_PP2_LED_A_Feedback, provided-interface=FsftCITR_e_PP2_LED_A_Feedback
      FsftCITR_e_PP2_LED_B_FailSts: server-com-spec=FsftCITR_e_PP2_LED_B_FailSts, provided-interface=FsftCITR_e_PP2_LED_B_FailSts
      FsftCITR_e_PP2_LED_B_Feedback: server-com-spec=FsftCITR_e_PP2_LED_B_Feedback, provided-interface=FsftCITR_e_PP2_LED_B_Feedback
      FsftCITR_e_PPFault: server-com-spec=FsftCITR_e_PPFault, provided-interface=FsftCITR_e_PPFault
      FsftCITR_e_PPFaultRsn: server-com-spec=FsftCITR_e_PPFaultRsn, provided-interface=FsftCITR_e_PPFaultRsn
      FsftCITR_e_PPLEDFault: server-com-spec=FsftCITR_e_PPLEDFault, provided-interface=FsftCITR_e_PPLEDFault
      FsftCITR_e_PP_LED_A_ColorFeedback: server-com-spec=FsftCITR_e_PP_LED_A_ColorFeedback, provided-interface=FsftCITR_e_PP_LED_A_ColorFeedback
      FsftCITR_e_PP_LED_A_FailSts: server-com-spec=FsftCITR_e_PP_LED_A_FailSts, provided-interface=FsftCITR_e_PP_LED_A_FailSts
      FsftCITR_e_PP_LED_A_Feedback: server-com-spec=FsftCITR_e_PP_LED_A_Feedback, provided-interface=FsftCITR_e_PP_LED_A_Feedback
      FsftCITR_e_PP_LED_B_ColorFeedback: server-com-spec=FsftCITR_e_PP_LED_B_ColorFeedback, provided-interface=FsftCITR_e_PP_LED_B_ColorFeedback
      FsftCITR_e_PP2_LED_B_ColorFeedback: server-com-spec=FsftCITR_e_PP2_LED_B_ColorFeedback, provided-interface=FsftCITR_e_PP2_LED_B_ColorFeedback
      FsftCITR_e_PP_LED_B_FailSts: server-com-spec=FsftCITR_e_PP_LED_B_FailSts, provided-interface=FsftCITR_e_PP_LED_B_FailSts
      FsftCITR_e_PP_LED_B_Feedback: server-com-spec=FsftCITR_e_PP_LED_B_Feedback, provided-interface=FsftCITR_e_PP_LED_B_Feedback
      FsftCITR_e_PP_LED_C_ColorFeedback: server-com-spec=FsftCITR_e_PP_LED_C_ColorFeedback, provided-interface=FsftCITR_e_PP_LED_C_ColorFeedback
      FsftCITR_e_PP_LED_C_FailSts: server-com-spec=FsftCITR_e_PP_LED_C_FailSts, provided-interface=FsftCITR_e_PP_LED_C_FailSts
      FsftCITR_e_PP_LED_C_Feedback: server-com-spec=FsftCITR_e_PP_LED_C_Feedback, provided-interface=FsftCITR_e_PP_LED_C_Feedback
      FsftCITR_e_PowerLimitReq: server-com-spec=FsftCITR_e_PowerLimitReq, provided-interface=FsftCITR_e_PowerLimitReq
      FsftCITR_e_PowerLimitReq_2: server-com-spec=FsftCITR_e_PowerLimitReq_2, provided-interface=FsftCITR_e_PowerLimitReq_2
      FsftCITR_e_RmtChrgPortLkCmd: server-com-spec=FsftCITR_e_RmtChrgPortLkCmd, provided-interface=FsftCITR_e_RmtChrgPortLkCmd
      FsftCITR_e_TBM_ChrgSchedType1: server-com-spec=FsftCITR_e_TBM_ChrgSchedType1, provided-interface=FsftCITR_e_TBM_ChrgSchedType1
      FsftCITR_e_TBM_ChrgSchedType2: server-com-spec=FsftCITR_e_TBM_ChrgSchedType2, provided-interface=FsftCITR_e_TBM_ChrgSchedType2
      FsftCITR_l_DistanceToCharge: server-com-spec=FsftCITR_l_DistanceToCharge, provided-interface=FsftCITR_l_DistanceToCharge
      FsftCITR_t_TimeToCharge: server-com-spec=FsftCITR_t_TimeToCharge, provided-interface=FsftCITR_t_TimeToCharge
      PokeCITR_I_PP2CurrentDrawSens1: server-com-spec{operation=PokeCITR_I_PP2CurrentDrawSens1, queue-length=1}, provided-interface=PokeCITR_I_PP2CurrentDrawSens1
      PokeCITR_I_PP2CurrentDrawSens2: server-com-spec{operation=PokeCITR_I_PP2CurrentDrawSens2, queue-length=1}, provided-interface=PokeCITR_I_PP2CurrentDrawSens2
      PokeCITR_I_PPCurrentDrawSens1: server-com-spec{operation=PokeCITR_I_PPCurrentDrawSens1, queue-length=1}, provided-interface=PokeCITR_I_PPCurrentDrawSens1
      PokeCITR_I_PPCurrentDrawSens2: server-com-spec{operation=PokeCITR_I_PPCurrentDrawSens2, queue-length=1}, provided-interface=PokeCITR_I_PPCurrentDrawSens2
      PokeCITR_K_ChrgPortHbridgeFlt: server-com-spec{operation=PokeCITR_K_ChrgPortHbridgeFlt, queue-length=1}, provided-interface=PokeCITR_K_ChrgPortHbridgeFlt
      PokeCITR_K_DateTmDay: server-com-spec{operation=PokeCITR_K_DateTmDay, queue-length=1}, provided-interface=PokeCITR_K_DateTmDay
      PokeCITR_K_DateTmHour: server-com-spec{operation=PokeCITR_K_DateTmHour, queue-length=1}, provided-interface=PokeCITR_K_DateTmHour
      PokeCITR_K_DateTmMin: server-com-spec{operation=PokeCITR_K_DateTmMin, queue-length=1}, provided-interface=PokeCITR_K_DateTmMin
      PokeCITR_K_DateTmMon: server-com-spec{operation=PokeCITR_K_DateTmMon, queue-length=1}, provided-interface=PokeCITR_K_DateTmMon
      PokeCITR_K_DateTmSec: server-com-spec{operation=PokeCITR_K_DateTmSec, queue-length=1}, provided-interface=PokeCITR_K_DateTmSec
      PokeCITR_K_DateTmYear: server-com-spec{operation=PokeCITR_K_DateTmYear, queue-length=1}, provided-interface=PokeCITR_K_DateTmYear
      PokeCITR_K_Date_Day1: server-com-spec{operation=PokeCITR_K_Date_Day1, queue-length=1}, provided-interface=PokeCITR_K_Date_Day1
      PokeCITR_K_Date_Day2: server-com-spec{operation=PokeCITR_K_Date_Day2, queue-length=1}, provided-interface=PokeCITR_K_Date_Day2
      PokeCITR_K_Date_Month1: server-com-spec{operation=PokeCITR_K_Date_Month1, queue-length=1}, provided-interface=PokeCITR_K_Date_Month1
      PokeCITR_K_Date_Month2: server-com-spec{operation=PokeCITR_K_Date_Month2, queue-length=1}, provided-interface=PokeCITR_K_Date_Month2
      PokeCITR_K_Date_Year{1..4}: server-com-spec{operation=PokeCITR_K_Date_Year{1..4}, queue-length=1}, provided-interface=PokeCITR_K_Date_Year{1..4}
      PokeCITR_K_HU_Sch1_Day: server-com-spec{operation=PokeCITR_K_HU_Sch1_Day, queue-length=1}, provided-interface=PokeCITR_K_HU_Sch1_Day
      PokeCITR_K_HU_Sch1_End_Time_Hr: server-com-spec{operation=PokeCITR_K_HU_Sch1_End_Time_Hr, queue-length=1}, provided-interface=PokeCITR_K_HU_Sch1_End_Time_Hr
      PokeCITR_K_HU_Sch1_End_Time_Min: server-com-spec{operation=PokeCITR_K_HU_Sch1_End_Time_Min, queue-length=1}, provided-interface=PokeCITR_K_HU_Sch1_End_Time_Min
      PokeCITR_K_HU_Sch1_Start_Time_Hr: server-com-spec{operation=PokeCITR_K_HU_Sch1_Start_Time_Hr, queue-length=1}, provided-interface=PokeCITR_K_HU_Sch1_Start_Time_Hr
      PokeCITR_K_HU_Sch1_Start_Time_Min: server-com-spec{operation=PokeCITR_K_HU_Sch1_Start_Time_Min, queue-length=1}, provided-interface=PokeCITR_K_HU_Sch1_Start_Time_Min
      PokeCITR_K_HU_Sch2_Day: server-com-spec{operation=PokeCITR_K_HU_Sch2_Day, queue-length=1}, provided-interface=PokeCITR_K_HU_Sch2_Day
      PokeCITR_K_HU_Sch2_End_Time_Hr: server-com-spec{operation=PokeCITR_K_HU_Sch2_End_Time_Hr, queue-length=1}, provided-interface=PokeCITR_K_HU_Sch2_End_Time_Hr
      PokeCITR_K_HU_Sch2_End_Time_Min: server-com-spec{operation=PokeCITR_K_HU_Sch2_End_Time_Min, queue-length=1}, provided-interface=PokeCITR_K_HU_Sch2_End_Time_Min
      PokeCITR_K_HU_Sch2_Start_Time_Hr: server-com-spec{operation=PokeCITR_K_HU_Sch2_Start_Time_Hr, queue-length=1}, provided-interface=PokeCITR_K_HU_Sch2_Start_Time_Hr
      PokeCITR_K_HU_Sch2_Start_Time_Min: server-com-spec{operation=PokeCITR_K_HU_Sch2_Start_Time_Min, queue-length=1}, provided-interface=PokeCITR_K_HU_Sch2_Start_Time_Min
      PokeCITR_K_HU_Sch3_Day: server-com-spec{operation=PokeCITR_K_HU_Sch3_Day, queue-length=1}, provided-interface=PokeCITR_K_HU_Sch3_Day
      PokeCITR_K_HU_Sch3_End_Time_Hr: server-com-spec{operation=PokeCITR_K_HU_Sch3_End_Time_Hr, queue-length=1}, provided-interface=PokeCITR_K_HU_Sch3_End_Time_Hr
      PokeCITR_K_HU_Sch3_End_Time_Min: server-com-spec{operation=PokeCITR_K_HU_Sch3_End_Time_Min, queue-length=1}, provided-interface=PokeCITR_K_HU_Sch3_End_Time_Min
      PokeCITR_K_HU_Sch3_Start_Time_Hr: server-com-spec{operation=PokeCITR_K_HU_Sch3_Start_Time_Hr, queue-length=1}, provided-interface=PokeCITR_K_HU_Sch3_Start_Time_Hr
      PokeCITR_K_HU_Sch3_Start_Time_Min: server-com-spec{operation=PokeCITR_K_HU_Sch3_Start_Time_Min, queue-length=1}, provided-interface=PokeCITR_K_HU_Sch3_Start_Time_Min
      PokeCITR_K_HU_Sch4_Day: server-com-spec{operation=PokeCITR_K_HU_Sch4_Day, queue-length=1}, provided-interface=PokeCITR_K_HU_Sch4_Day
      PokeCITR_K_HU_Sch4_Start_Time_Hr: server-com-spec{operation=PokeCITR_K_HU_Sch4_Start_Time_Hr, queue-length=1}, provided-interface=PokeCITR_K_HU_Sch4_Start_Time_Hr
      PokeCITR_K_HU_Sch4_Start_Time_Min: server-com-spec{operation=PokeCITR_K_HU_Sch4_Start_Time_Min, queue-length=1}, provided-interface=PokeCITR_K_HU_Sch4_Start_Time_Min
      PokeCITR_K_TBM_Sch1_Day: server-com-spec{operation=PokeCITR_K_TBM_Sch1_Day, queue-length=1}, provided-interface=PokeCITR_K_TBM_Sch1_Day
      PokeCITR_K_TBM_Sch1_End_Time_Hr: server-com-spec{operation=PokeCITR_K_TBM_Sch1_End_Time_Hr, queue-length=1}, provided-interface=PokeCITR_K_TBM_Sch1_End_Time_Hr
      PokeCITR_K_TBM_Sch1_End_Time_Min: server-com-spec{operation=PokeCITR_K_TBM_Sch1_End_Time_Min, queue-length=1}, provided-interface=PokeCITR_K_TBM_Sch1_End_Time_Min
      PokeCITR_K_TBM_Sch1_Start_Time_Hr: server-com-spec{operation=PokeCITR_K_TBM_Sch1_Start_Time_Hr, queue-length=1}, provided-interface=PokeCITR_K_TBM_Sch1_Start_Time_Hr
      PokeCITR_K_TBM_Sch1_Start_Time_Min: server-com-spec{operation=PokeCITR_K_TBM_Sch1_Start_Time_Min, queue-length=1}, provided-interface=PokeCITR_K_TBM_Sch1_Start_Time_Min
      PokeCITR_K_TBM_Sch2_Day: server-com-spec{operation=PokeCITR_K_TBM_Sch2_Day, queue-length=1}, provided-interface=PokeCITR_K_TBM_Sch2_Day
      PokeCITR_K_TBM_Sch2_End_Time_Hr: server-com-spec{operation=PokeCITR_K_TBM_Sch2_End_Time_Hr, queue-length=1}, provided-interface=PokeCITR_K_TBM_Sch2_End_Time_Hr
      PokeCITR_K_TBM_Sch2_End_Time_Min: server-com-spec{operation=PokeCITR_K_TBM_Sch2_End_Time_Min, queue-length=1}, provided-interface=PokeCITR_K_TBM_Sch2_End_Time_Min
      PokeCITR_K_TBM_Sch2_Start_Time_Hr: server-com-spec{operation=PokeCITR_K_TBM_Sch2_Start_Time_Hr, queue-length=1}, provided-interface=PokeCITR_K_TBM_Sch2_Start_Time_Hr
      PokeCITR_K_TBM_Sch2_Start_Time_Min: server-com-spec{operation=PokeCITR_K_TBM_Sch2_Start_Time_Min, queue-length=1}, provided-interface=PokeCITR_K_TBM_Sch2_Start_Time_Min
      PokeCITR_K_TBM_Sch3_Day: server-com-spec{operation=PokeCITR_K_TBM_Sch3_Day, queue-length=1}, provided-interface=PokeCITR_K_TBM_Sch3_Day
      PokeCITR_K_TBM_Sch3_End_Time_Hr: server-com-spec{operation=PokeCITR_K_TBM_Sch3_End_Time_Hr, queue-length=1}, provided-interface=PokeCITR_K_TBM_Sch3_End_Time_Hr
      PokeCITR_K_TBM_Sch3_End_Time_Min: server-com-spec{operation=PokeCITR_K_TBM_Sch3_End_Time_Min, queue-length=1}, provided-interface=PokeCITR_K_TBM_Sch3_End_Time_Min
      PokeCITR_K_TBM_Sch3_Start_Time_Hr: server-com-spec{operation=PokeCITR_K_TBM_Sch3_Start_Time_Hr, queue-length=1}, provided-interface=PokeCITR_K_TBM_Sch3_Start_Time_Hr
      PokeCITR_K_TBM_Sch3_Start_Time_Min: server-com-spec{operation=PokeCITR_K_TBM_Sch3_Start_Time_Min, queue-length=1}, provided-interface=PokeCITR_K_TBM_Sch3_Start_Time_Min
      PokeCITR_K_TBM_Sch4_Day: server-com-spec{operation=PokeCITR_K_TBM_Sch4_Day, queue-length=1}, provided-interface=PokeCITR_K_TBM_Sch4_Day
      PokeCITR_K_TBM_Sch4_Start_Time_Hr: server-com-spec{operation=PokeCITR_K_TBM_Sch4_Start_Time_Hr, queue-length=1}, provided-interface=PokeCITR_K_TBM_Sch4_Start_Time_Hr
      PokeCITR_K_TBM_Sch4_Start_Time_Min: server-com-spec{operation=PokeCITR_K_TBM_Sch4_Start_Time_Min, queue-length=1}, provided-interface=PokeCITR_K_TBM_Sch4_Start_Time_Min
      PokeCITR_K_Time_Hour1: server-com-spec{operation=PokeCITR_K_Time_Hour1, queue-length=1}, provided-interface=PokeCITR_K_Time_Hour1
      PokeCITR_K_Time_Hour2: server-com-spec{operation=PokeCITR_K_Time_Hour2, queue-length=1}, provided-interface=PokeCITR_K_Time_Hour2
      PokeCITR_K_Time_Minute1: server-com-spec{operation=PokeCITR_K_Time_Minute1, queue-length=1}, provided-interface=PokeCITR_K_Time_Minute1
      PokeCITR_K_Time_Minute2: server-com-spec{operation=PokeCITR_K_Time_Minute2, queue-length=1}, provided-interface=PokeCITR_K_Time_Minute2
      PokeCITR_P_ChargingDestinationPwr: server-com-spec{operation=PokeCITR_P_ChargingDestinationPwr, queue-length=1}, provided-interface=PokeCITR_P_ChargingDestinationPwr
      PokeCITR_P_PP2RatedPower: server-com-spec{operation=PokeCITR_P_PP2RatedPower, queue-length=1}, provided-interface=PokeCITR_P_PP2RatedPower
      PokeCITR_P_PPRatedPower: server-com-spec{operation=PokeCITR_P_PPRatedPower, queue-length=1}, provided-interface=PokeCITR_P_PPRatedPower
      PokeCITR_Pct_HU_ExtChrgTarget1: server-com-spec{operation=PokeCITR_Pct_HU_ExtChrgTarget1, queue-length=1}, provided-interface=PokeCITR_Pct_HU_ExtChrgTarget1
      PokeCITR_Pct_HU_ExtChrgTarget2: server-com-spec{operation=PokeCITR_Pct_HU_ExtChrgTarget2, queue-length=1}, provided-interface=PokeCITR_Pct_HU_ExtChrgTarget2
      PokeCITR_Pct_HU_ImmChrgTarget1: server-com-spec{operation=PokeCITR_Pct_HU_ImmChrgTarget1, queue-length=1}, provided-interface=PokeCITR_Pct_HU_ImmChrgTarget1
      PokeCITR_Pct_HU_ImmChrgTarget2: server-com-spec{operation=PokeCITR_Pct_HU_ImmChrgTarget2, queue-length=1}, provided-interface=PokeCITR_Pct_HU_ImmChrgTarget2
      PokeCITR_Pct_TBM_ExtChrgTarget1: server-com-spec{operation=PokeCITR_Pct_TBM_ExtChrgTarget1, queue-length=1}, provided-interface=PokeCITR_Pct_TBM_ExtChrgTarget1
      PokeCITR_Pct_TBM_ExtChrgTarget2: server-com-spec{operation=PokeCITR_Pct_TBM_ExtChrgTarget2, queue-length=1}, provided-interface=PokeCITR_Pct_TBM_ExtChrgTarget2
      PokeCITR_Pct_TBM_ImmChrgTarget1: server-com-spec{operation=PokeCITR_Pct_TBM_ImmChrgTarget1, queue-length=1}, provided-interface=PokeCITR_Pct_TBM_ImmChrgTarget1
      PokeCITR_Pct_TBM_ImmChrgTarget2: server-com-spec{operation=PokeCITR_Pct_TBM_ImmChrgTarget2, queue-length=1}, provided-interface=PokeCITR_Pct_TBM_ImmChrgTarget2
      PokeCITR_Pct_V2HRsrvBatt: server-com-spec{operation=PokeCITR_Pct_V2HRsrvBatt, queue-length=1}, provided-interface=PokeCITR_Pct_V2HRsrvBatt
      PokeCITR_Pct_V2LRsrvBatt: server-com-spec{operation=PokeCITR_Pct_V2LRsrvBatt, queue-length=1}, provided-interface=PokeCITR_Pct_V2LRsrvBatt
      PokeCITR_Pct_V2VRsrvBatt: server-com-spec{operation=PokeCITR_Pct_V2VRsrvBatt, queue-length=1}, provided-interface=PokeCITR_Pct_V2VRsrvBatt
      PokeCITR_T_HU_Sch{1..4}_CabTemp: server-com-spec{operation=PokeCITR_T_HU_Sch{1..4}_CabTemp, queue-length=1}, provided-interface=PokeCITR_T_HU_Sch{1..4}_CabTemp
      PokeCITR_T_TBM_Sch{1..4}_CabTemp: server-com-spec{operation=PokeCITR_T_TBM_Sch{1..4}_CabTemp, queue-length=1}, provided-interface=PokeCITR_T_TBM_Sch{1..4}_CabTemp
      PokeCITR_U_ChrgPortLock_StsB: server-com-spec{operation=PokeCITR_U_ChrgPortLock_StsB, queue-length=1}, provided-interface=PokeCITR_U_ChrgPortLock_StsB
      PokeCITR_b_BCIM_LIN_Chksum_Error: server-com-spec{operation=PokeCITR_b_BCIM_LIN_Chksum_Error, queue-length=1}, provided-interface=PokeCITR_b_BCIM_LIN_Chksum_Error
      PokeCITR_b_BCIM_LIN_Data_Error: server-com-spec{operation=PokeCITR_b_BCIM_LIN_Data_Error, queue-length=1}, provided-interface=PokeCITR_b_BCIM_LIN_Data_Error
      PokeCITR_b_BCIM_LIN_Parity_Error: server-com-spec{operation=PokeCITR_b_BCIM_LIN_Parity_Error, queue-length=1}, provided-interface=PokeCITR_b_BCIM_LIN_Parity_Error
      PokeCITR_b_BCIM_Over_Temp: server-com-spec{operation=PokeCITR_b_BCIM_Over_Temp, queue-length=1}, provided-interface=PokeCITR_b_BCIM_Over_Temp
      PokeCITR_b_BCIM_Undervolt: server-com-spec{operation=PokeCITR_b_BCIM_Undervolt, queue-length=1}, provided-interface=PokeCITR_b_BCIM_Undervolt
      PokeCITR_b_CPIM_BlueLED_Sts: server-com-spec{operation=PokeCITR_b_CPIM_BlueLED_Sts, queue-length=1}, provided-interface=PokeCITR_b_CPIM_BlueLED_Sts
      PokeCITR_b_CPIM_GreenLED_Sts: server-com-spec{operation=PokeCITR_b_CPIM_GreenLED_Sts, queue-length=1}, provided-interface=PokeCITR_b_CPIM_GreenLED_Sts
      PokeCITR_b_CPIM_LINChkSumErr: server-com-spec{operation=PokeCITR_b_CPIM_LINChkSumErr, queue-length=1}, provided-interface=PokeCITR_b_CPIM_LINChkSumErr
      PokeCITR_b_CPIM_LINDataErr: server-com-spec{operation=PokeCITR_b_CPIM_LINDataErr, queue-length=1}, provided-interface=PokeCITR_b_CPIM_LINDataErr
      PokeCITR_b_CPIM_LINParityErr: server-com-spec{operation=PokeCITR_b_CPIM_LINParityErr, queue-length=1}, provided-interface=PokeCITR_b_CPIM_LINParityErr
      PokeCITR_b_CPIM_OverTemp: server-com-spec{operation=PokeCITR_b_CPIM_OverTemp, queue-length=1}, provided-interface=PokeCITR_b_CPIM_OverTemp
      PokeCITR_b_CPIM_RedLED_Sts: server-com-spec{operation=PokeCITR_b_CPIM_RedLED_Sts, queue-length=1}, provided-interface=PokeCITR_b_CPIM_RedLED_Sts
      PokeCITR_b_CPIM_UnderVolt: server-com-spec{operation=PokeCITR_b_CPIM_UnderVolt, queue-length=1}, provided-interface=PokeCITR_b_CPIM_UnderVolt
      PokeCITR_b_ChargeNow: server-com-spec{operation=PokeCITR_b_ChargeNow, queue-length=1}, provided-interface=PokeCITR_b_ChargeNow
      PokeCITR_b_ChrgPortButton_FailSts: server-com-spec{operation=PokeCITR_b_ChrgPortButton_FailSts, queue-length=1}, provided-interface=PokeCITR_b_ChrgPortButton_FailSts
      PokeCITR_b_ChrgPortButton_Sts: server-com-spec{operation=PokeCITR_b_ChrgPortButton_Sts, queue-length=1}, provided-interface=PokeCITR_b_ChrgPortButton_Sts
      PokeCITR_b_ChrgPortLock_StsC: server-com-spec{operation=PokeCITR_b_ChrgPortLock_StsC, queue-length=1}, provided-interface=PokeCITR_b_ChrgPortLock_StsC
      PokeCITR_b_ChrgPort_BCM_Cmd: server-com-spec{operation=PokeCITR_b_ChrgPort_BCM_Cmd, queue-length=1}, provided-interface=PokeCITR_b_ChrgPort_BCM_Cmd
      PokeCITR_b_ChrgPort_Fdbk: server-com-spec{operation=PokeCITR_b_ChrgPort_Fdbk, queue-length=1}, provided-interface=PokeCITR_b_ChrgPort_Fdbk
      PokeCITR_b_CoopCh_VehLocation: server-com-spec{operation=PokeCITR_b_CoopCh_VehLocation, queue-length=1}, provided-interface=PokeCITR_b_CoopCh_VehLocation
      PokeCITR_b_DC_PwrLev: server-com-spec{operation=PokeCITR_b_DC_PwrLev, queue-length=1}, provided-interface=PokeCITR_b_DC_PwrLev
      PokeCITR_b_Drv_Dr_Unlocking: server-com-spec{operation=PokeCITR_b_Drv_Dr_Unlocking, queue-length=1}, provided-interface=PokeCITR_b_Drv_Dr_Unlocking
      PokeCITR_b_HU_Sch1_ChargeUntilFull: server-com-spec{operation=PokeCITR_b_HU_Sch1_ChargeUntilFull, queue-length=1}, provided-interface=PokeCITR_b_HU_Sch1_ChargeUntilFull
      PokeCITR_b_HU_Sch1_Do_Not_Repeat: server-com-spec{operation=PokeCITR_b_HU_Sch1_Do_Not_Repeat, queue-length=1}, provided-interface=PokeCITR_b_HU_Sch1_Do_Not_Repeat
      PokeCITR_b_HU_Sch1_Enbl: server-com-spec{operation=PokeCITR_b_HU_Sch1_Enbl, queue-length=1}, provided-interface=PokeCITR_b_HU_Sch1_Enbl
      PokeCITR_b_HU_Sch1_Priority: server-com-spec{operation=PokeCITR_b_HU_Sch1_Priority, queue-length=1}, provided-interface=PokeCITR_b_HU_Sch1_Priority
      PokeCITR_b_HU_Sch1_Submit: server-com-spec{operation=PokeCITR_b_HU_Sch1_Submit, queue-length=1}, provided-interface=PokeCITR_b_HU_Sch1_Submit
      PokeCITR_b_HU_Sch2_ChargeUntilFull: server-com-spec{operation=PokeCITR_b_HU_Sch2_ChargeUntilFull, queue-length=1}, provided-interface=PokeCITR_b_HU_Sch2_ChargeUntilFull
      PokeCITR_b_HU_Sch2_Do_Not_Repeat: server-com-spec{operation=PokeCITR_b_HU_Sch2_Do_Not_Repeat, queue-length=1}, provided-interface=PokeCITR_b_HU_Sch2_Do_Not_Repeat
      PokeCITR_b_HU_Sch2_Enbl: server-com-spec{operation=PokeCITR_b_HU_Sch2_Enbl, queue-length=1}, provided-interface=PokeCITR_b_HU_Sch2_Enbl
      PokeCITR_b_HU_Sch2_Priority: server-com-spec{operation=PokeCITR_b_HU_Sch2_Priority, queue-length=1}, provided-interface=PokeCITR_b_HU_Sch2_Priority
      PokeCITR_b_HU_Sch2_Submit: server-com-spec{operation=PokeCITR_b_HU_Sch2_Submit, queue-length=1}, provided-interface=PokeCITR_b_HU_Sch2_Submit
      PokeCITR_b_HU_Sch3_ChargeUntilFull: server-com-spec{operation=PokeCITR_b_HU_Sch3_ChargeUntilFull, queue-length=1}, provided-interface=PokeCITR_b_HU_Sch3_ChargeUntilFull
      PokeCITR_b_HU_Sch3_Do_Not_Repeat: server-com-spec{operation=PokeCITR_b_HU_Sch3_Do_Not_Repeat, queue-length=1}, provided-interface=PokeCITR_b_HU_Sch3_Do_Not_Repeat
      PokeCITR_b_HU_Sch3_Enbl: server-com-spec{operation=PokeCITR_b_HU_Sch3_Enbl, queue-length=1}, provided-interface=PokeCITR_b_HU_Sch3_Enbl
      PokeCITR_b_HU_Sch3_Priority: server-com-spec{operation=PokeCITR_b_HU_Sch3_Priority, queue-length=1}, provided-interface=PokeCITR_b_HU_Sch3_Priority
      PokeCITR_b_HU_Sch3_Submit: server-com-spec{operation=PokeCITR_b_HU_Sch3_Submit, queue-length=1}, provided-interface=PokeCITR_b_HU_Sch3_Submit
      PokeCITR_b_HU_Sch4_Enbl: server-com-spec{operation=PokeCITR_b_HU_Sch4_Enbl, queue-length=1}, provided-interface=PokeCITR_b_HU_Sch4_Enbl
      PokeCITR_b_HU_Sch4_Submit: server-com-spec{operation=PokeCITR_b_HU_Sch4_Submit, queue-length=1}, provided-interface=PokeCITR_b_HU_Sch4_Submit
      PokeCITR_b_Icon1_FailSts: server-com-spec{operation=PokeCITR_b_Icon1_FailSts, queue-length=1}, provided-interface=PokeCITR_b_Icon1_FailSts
      PokeCITR_b_Icon2_FailSts: server-com-spec{operation=PokeCITR_b_Icon2_FailSts, queue-length=1}, provided-interface=PokeCITR_b_Icon2_FailSts
      PokeCITR_b_PP2ACPresentSens1: server-com-spec{operation=PokeCITR_b_PP2ACPresentSens1, queue-length=1}, provided-interface=PokeCITR_b_PP2ACPresentSens1
      PokeCITR_b_PP2ACPresentSens2: server-com-spec{operation=PokeCITR_b_PP2ACPresentSens2, queue-length=1}, provided-interface=PokeCITR_b_PP2ACPresentSens2
      PokeCITR_b_PP2ButtonSts: server-com-spec{operation=PokeCITR_b_PP2ButtonSts, queue-length=1}, provided-interface=PokeCITR_b_PP2ButtonSts
      PokeCITR_b_PP2LidSwitchSts240: server-com-spec{operation=PokeCITR_b_PP2LidSwitchSts240, queue-length=1}, provided-interface=PokeCITR_b_PP2LidSwitchSts240
      PokeCITR_b_PP2LidSwitchSts120A: server-com-spec{operation=PokeCITR_b_PP2LidSwitchSts120A, queue-length=1}, provided-interface=PokeCITR_b_PP2LidSwitchSts120A
      PokeCITR_b_PP2LidSwitchSts120B: server-com-spec{operation=PokeCITR_b_PP2LidSwitchSts120B, queue-length=1}, provided-interface=PokeCITR_b_PP2LidSwitchSts120B
      PokeCITR_b_PP2_Gnd_Fault_Det: server-com-spec{operation=PokeCITR_b_PP2_Gnd_Fault_Det, queue-length=1}, provided-interface=PokeCITR_b_PP2_Gnd_Fault_Det
      PokeCITR_b_PP2_LIN_Cksm_Err: server-com-spec{operation=PokeCITR_b_PP2_LIN_Cksm_Err, queue-length=1}, provided-interface=PokeCITR_b_PP2_LIN_Cksm_Err
      PokeCITR_b_PP2_LIN_Data_Err: server-com-spec{operation=PokeCITR_b_PP2_LIN_Data_Err, queue-length=1}, provided-interface=PokeCITR_b_PP2_LIN_Data_Err
      PokeCITR_b_PP2_LIN_Parity_Err: server-com-spec{operation=PokeCITR_b_PP2_LIN_Parity_Err, queue-length=1}, provided-interface=PokeCITR_b_PP2_LIN_Parity_Err
      PokeCITR_b_PPACPresentSens1: server-com-spec{operation=PokeCITR_b_PPACPresentSens1, queue-length=1}, provided-interface=PokeCITR_b_PPACPresentSens1
      PokeCITR_b_PPACPresentSens2: server-com-spec{operation=PokeCITR_b_PPACPresentSens2, queue-length=1}, provided-interface=PokeCITR_b_PPACPresentSens2
      PokeCITR_b_PPButtonSts: server-com-spec{operation=PokeCITR_b_PPButtonSts, queue-length=1}, provided-interface=PokeCITR_b_PPButtonSts
      PokeCITR_b_PPLidSwitchSts120A: server-com-spec{operation=PokeCITR_b_PPLidSwitchSts120A, queue-length=1}, provided-interface=PokeCITR_b_PPLidSwitchSts120A
      PokeCITR_b_PPLidSwitchSts120B: server-com-spec{operation=PokeCITR_b_PPLidSwitchSts120B, queue-length=1}, provided-interface=PokeCITR_b_PPLidSwitchSts120B
      PokeCITR_b_PPLidSwitchSts240: server-com-spec{operation=PokeCITR_b_PPLidSwitchSts240, queue-length=1}, provided-interface=PokeCITR_b_PPLidSwitchSts240
      PokeCITR_b_PP_Gnd_Fault_Det: server-com-spec{operation=PokeCITR_b_PP_Gnd_Fault_Det, queue-length=1}, provided-interface=PokeCITR_b_PP_Gnd_Fault_Det
      PokeCITR_b_PP_LIN_Cksm_Err: server-com-spec{operation=PokeCITR_b_PP_LIN_Cksm_Err, queue-length=1}, provided-interface=PokeCITR_b_PP_LIN_Cksm_Err
      PokeCITR_b_PP_LIN_Data_Err: server-com-spec{operation=PokeCITR_b_PP_LIN_Data_Err, queue-length=1}, provided-interface=PokeCITR_b_PP_LIN_Data_Err
      PokeCITR_b_PP_LIN_Parity_Err: server-com-spec{operation=PokeCITR_b_PP_LIN_Parity_Err, queue-length=1}, provided-interface=PokeCITR_b_PP_LIN_Parity_Err
      PokeCITR_b_RsErrSPP: server-com-spec{operation=PokeCITR_b_RsErrSPP, queue-length=1}, provided-interface=PokeCITR_b_RsErrSPP
      PokeCITR_b_RsErrSPP2: server-com-spec{operation=PokeCITR_b_RsErrSPP2, queue-length=1}, provided-interface=PokeCITR_b_RsErrSPP2
      PokeCITR_b_SOC_Max_Lev: server-com-spec{operation=PokeCITR_b_SOC_Max_Lev, queue-length=1}, provided-interface=PokeCITR_b_SOC_Max_Lev
      PokeCITR_b_TBMStopChrg: server-com-spec{operation=PokeCITR_b_TBMStopChrg, queue-length=1}, provided-interface=PokeCITR_b_TBMStopChrg
      PokeCITR_b_TBM_Charge_Now: server-com-spec{operation=PokeCITR_b_TBM_Charge_Now, queue-length=1}, provided-interface=PokeCITR_b_TBM_Charge_Now
      PokeCITR_b_TBM_Sch1_ChargeUntilFull: server-com-spec{operation=PokeCITR_b_TBM_Sch1_ChargeUntilFull, queue-length=1}, provided-interface=PokeCITR_b_TBM_Sch1_ChargeUntilFull
      PokeCITR_b_TBM_Sch1_Do_Not_Repeat: server-com-spec{operation=PokeCITR_b_TBM_Sch1_Do_Not_Repeat, queue-length=1}, provided-interface=PokeCITR_b_TBM_Sch1_Do_Not_Repeat
      PokeCITR_b_TBM_Sch1_Enbl: server-com-spec{operation=PokeCITR_b_TBM_Sch1_Enbl, queue-length=1}, provided-interface=PokeCITR_b_TBM_Sch1_Enbl
      PokeCITR_b_TBM_Sch1_Priority: server-com-spec{operation=PokeCITR_b_TBM_Sch1_Priority, queue-length=1}, provided-interface=PokeCITR_b_TBM_Sch1_Priority
      PokeCITR_b_TBM_Sch1_Submit: server-com-spec{operation=PokeCITR_b_TBM_Sch1_Submit, queue-length=1}, provided-interface=PokeCITR_b_TBM_Sch1_Submit
      PokeCITR_b_TBM_Sch2_ChargeUntilFull: server-com-spec{operation=PokeCITR_b_TBM_Sch2_ChargeUntilFull, queue-length=1}, provided-interface=PokeCITR_b_TBM_Sch2_ChargeUntilFull
      PokeCITR_b_TBM_Sch2_Do_Not_Repeat: server-com-spec{operation=PokeCITR_b_TBM_Sch2_Do_Not_Repeat, queue-length=1}, provided-interface=PokeCITR_b_TBM_Sch2_Do_Not_Repeat
      PokeCITR_b_TBM_Sch2_Enbl: server-com-spec{operation=PokeCITR_b_TBM_Sch2_Enbl, queue-length=1}, provided-interface=PokeCITR_b_TBM_Sch2_Enbl
      PokeCITR_b_TBM_Sch2_Priority: server-com-spec{operation=PokeCITR_b_TBM_Sch2_Priority, queue-length=1}, provided-interface=PokeCITR_b_TBM_Sch2_Priority
      PokeCITR_b_TBM_Sch2_Submit: server-com-spec{operation=PokeCITR_b_TBM_Sch2_Submit, queue-length=1}, provided-interface=PokeCITR_b_TBM_Sch2_Submit
      PokeCITR_b_TBM_Sch3_ChargeUntilFull: server-com-spec{operation=PokeCITR_b_TBM_Sch3_ChargeUntilFull, queue-length=1}, provided-interface=PokeCITR_b_TBM_Sch3_ChargeUntilFull
      PokeCITR_b_TBM_Sch3_Do_Not_Repeat: server-com-spec{operation=PokeCITR_b_TBM_Sch3_Do_Not_Repeat, queue-length=1}, provided-interface=PokeCITR_b_TBM_Sch3_Do_Not_Repeat
      PokeCITR_b_TBM_Sch3_Enbl: server-com-spec{operation=PokeCITR_b_TBM_Sch3_Enbl, queue-length=1}, provided-interface=PokeCITR_b_TBM_Sch3_Enbl
      PokeCITR_b_TBM_Sch3_Priority: server-com-spec{operation=PokeCITR_b_TBM_Sch3_Priority, queue-length=1}, provided-interface=PokeCITR_b_TBM_Sch3_Priority
      PokeCITR_b_TBM_Sch3_Submit: server-com-spec{operation=PokeCITR_b_TBM_Sch3_Submit, queue-length=1}, provided-interface=PokeCITR_b_TBM_Sch3_Submit
      PokeCITR_b_TBM_Sch4_Enbl: server-com-spec{operation=PokeCITR_b_TBM_Sch4_Enbl, queue-length=1}, provided-interface=PokeCITR_b_TBM_Sch4_Enbl
      PokeCITR_b_TBM_Sch4_Submit: server-com-spec{operation=PokeCITR_b_TBM_Sch4_Submit, queue-length=1}, provided-interface=PokeCITR_b_TBM_Sch4_Submit
      PokeCITR_b_V2HModeReq: server-com-spec{operation=PokeCITR_b_V2HModeReq, queue-length=1}, provided-interface=PokeCITR_b_V2HModeReq
      PokeCITR_b_V2HReq: server-com-spec{operation=PokeCITR_b_V2HReq, queue-length=1}, provided-interface=PokeCITR_b_V2HReq
      PokeCITR_b_V2HSubmit: server-com-spec{operation=PokeCITR_b_V2HSubmit, queue-length=1}, provided-interface=PokeCITR_b_V2HSubmit
      PokeCITR_b_V2LModeReq: server-com-spec{operation=PokeCITR_b_V2LModeReq, queue-length=1}, provided-interface=PokeCITR_b_V2LModeReq
      PokeCITR_b_V2LSubmit: server-com-spec{operation=PokeCITR_b_V2LSubmit, queue-length=1}, provided-interface=PokeCITR_b_V2LSubmit
      PokeCITR_b_V2LTrunkReq: server-com-spec{operation=PokeCITR_b_V2LTrunkReq, queue-length=1}, provided-interface=PokeCITR_b_V2LTrunkReq
      PokeCITR_b_V2L_AllReq: server-com-spec{operation=PokeCITR_b_V2L_AllReq, queue-length=1}, provided-interface=PokeCITR_b_V2L_AllReq
      PokeCITR_b_V2L_FrunkReq: server-com-spec{operation=PokeCITR_b_V2L_FrunkReq, queue-length=1}, provided-interface=PokeCITR_b_V2L_FrunkReq
      PokeCITR_b_V2VModeReq: server-com-spec{operation=PokeCITR_b_V2VModeReq, queue-length=1}, provided-interface=PokeCITR_b_V2VModeReq
      PokeCITR_b_V2VReq: server-com-spec{operation=PokeCITR_b_V2VReq, queue-length=1}, provided-interface=PokeCITR_b_V2VReq
      PokeCITR_b_V2VSubmit: server-com-spec{operation=PokeCITR_b_V2VSubmit, queue-length=1}, provided-interface=PokeCITR_b_V2VSubmit
      PokeCITR_e_BCIM_Ind1_FailSts: server-com-spec{operation=PokeCITR_e_BCIM_Ind1_FailSts, queue-length=1}, provided-interface=PokeCITR_e_BCIM_Ind1_FailSts
      PokeCITR_e_BCIM_Ind1_Fdbk: server-com-spec{operation=PokeCITR_e_BCIM_Ind1_Fdbk, queue-length=1}, provided-interface=PokeCITR_e_BCIM_Ind1_Fdbk
      PokeCITR_e_BCIM_Ind2_FailSts: server-com-spec{operation=PokeCITR_e_BCIM_Ind2_FailSts, queue-length=1}, provided-interface=PokeCITR_e_BCIM_Ind2_FailSts
      PokeCITR_e_BCIM_Ind2_Fdbk: server-com-spec{operation=PokeCITR_e_BCIM_Ind2_Fdbk, queue-length=1}, provided-interface=PokeCITR_e_BCIM_Ind2_Fdbk
      PokeCITR_e_BCIM_Ind3_FailSts: server-com-spec{operation=PokeCITR_e_BCIM_Ind3_FailSts, queue-length=1}, provided-interface=PokeCITR_e_BCIM_Ind3_FailSts
      PokeCITR_e_BCIM_Ind3_Fdbk: server-com-spec{operation=PokeCITR_e_BCIM_Ind3_Fdbk, queue-length=1}, provided-interface=PokeCITR_e_BCIM_Ind3_Fdbk
      PokeCITR_e_BCIM_Ind4_FailSts: server-com-spec{operation=PokeCITR_e_BCIM_Ind4_FailSts, queue-length=1}, provided-interface=PokeCITR_e_BCIM_Ind4_FailSts
      PokeCITR_e_BCIM_Ind4_Fdbk: server-com-spec{operation=PokeCITR_e_BCIM_Ind4_Fdbk, queue-length=1}, provided-interface=PokeCITR_e_BCIM_Ind4_Fdbk
      PokeCITR_e_BCIM_Ind5_FailSts: server-com-spec{operation=PokeCITR_e_BCIM_Ind5_FailSts, queue-length=1}, provided-interface=PokeCITR_e_BCIM_Ind5_FailSts
      PokeCITR_e_BCIM_Ind5_Fdbk: server-com-spec{operation=PokeCITR_e_BCIM_Ind5_Fdbk, queue-length=1}, provided-interface=PokeCITR_e_BCIM_Ind5_Fdbk
      PokeCITR_e_BCIM_Ind_Color_Fdbk: server-com-spec{operation=PokeCITR_e_BCIM_Ind_Color_Fdbk, queue-length=1}, provided-interface=PokeCITR_e_BCIM_Ind_Color_Fdbk
      PokeCITR_e_CPIM_BlueLED_FailSts: server-com-spec{operation=PokeCITR_e_CPIM_BlueLED_FailSts, queue-length=1}, provided-interface=PokeCITR_e_CPIM_BlueLED_FailSts
      PokeCITR_e_CPIM_GreenLED_FailSts: server-com-spec{operation=PokeCITR_e_CPIM_GreenLED_FailSts, queue-length=1}, provided-interface=PokeCITR_e_CPIM_GreenLED_FailSts
      PokeCITR_e_CPIM_Icon1_Sts: server-com-spec{operation=PokeCITR_e_CPIM_Icon1_Sts, queue-length=1}, provided-interface=PokeCITR_e_CPIM_Icon1_Sts
      PokeCITR_e_CPIM_Icon2_Sts: server-com-spec{operation=PokeCITR_e_CPIM_Icon2_Sts, queue-length=1}, provided-interface=PokeCITR_e_CPIM_Icon2_Sts
      PokeCITR_e_CPIM_Ind1_FailSts: server-com-spec{operation=PokeCITR_e_CPIM_Ind1_FailSts, queue-length=1}, provided-interface=PokeCITR_e_CPIM_Ind1_FailSts
      PokeCITR_e_CPIM_Ind1_Fdbk: server-com-spec{operation=PokeCITR_e_CPIM_Ind1_Fdbk, queue-length=1}, provided-interface=PokeCITR_e_CPIM_Ind1_Fdbk
      PokeCITR_e_CPIM_Ind2_FailSts: server-com-spec{operation=PokeCITR_e_CPIM_Ind2_FailSts, queue-length=1}, provided-interface=PokeCITR_e_CPIM_Ind2_FailSts
      PokeCITR_e_CPIM_Ind2_Fdbk: server-com-spec{operation=PokeCITR_e_CPIM_Ind2_Fdbk, queue-length=1}, provided-interface=PokeCITR_e_CPIM_Ind2_Fdbk
      PokeCITR_e_CPIM_Ind3_FailSts: server-com-spec{operation=PokeCITR_e_CPIM_Ind3_FailSts, queue-length=1}, provided-interface=PokeCITR_e_CPIM_Ind3_FailSts
      PokeCITR_e_CPIM_Ind3_Fdbk: server-com-spec{operation=PokeCITR_e_CPIM_Ind3_Fdbk, queue-length=1}, provided-interface=PokeCITR_e_CPIM_Ind3_Fdbk
      PokeCITR_e_CPIM_Ind4_FailSts: server-com-spec{operation=PokeCITR_e_CPIM_Ind4_FailSts, queue-length=1}, provided-interface=PokeCITR_e_CPIM_Ind4_FailSts
      PokeCITR_e_CPIM_Ind4_Fdbk: server-com-spec{operation=PokeCITR_e_CPIM_Ind4_Fdbk, queue-length=1}, provided-interface=PokeCITR_e_CPIM_Ind4_Fdbk
      PokeCITR_e_CPIM_Ind5_FailSts: server-com-spec{operation=PokeCITR_e_CPIM_Ind5_FailSts, queue-length=1}, provided-interface=PokeCITR_e_CPIM_Ind5_FailSts
      PokeCITR_e_CPIM_Ind5_Fdbk: server-com-spec{operation=PokeCITR_e_CPIM_Ind5_Fdbk, queue-length=1}, provided-interface=PokeCITR_e_CPIM_Ind5_Fdbk
      PokeCITR_e_CPIM_Ind_Color_Fdbk: server-com-spec{operation=PokeCITR_e_CPIM_Ind_Color_Fdbk, queue-length=1}, provided-interface=PokeCITR_e_CPIM_Ind_Color_Fdbk
      PokeCITR_e_CPIM_RedLED_FailSts: server-com-spec{operation=PokeCITR_e_CPIM_RedLED_FailSts, queue-length=1}, provided-interface=PokeCITR_e_CPIM_RedLED_FailSts
      PokeCITR_e_ChrgPortDoor_Sts: server-com-spec{operation=PokeCITR_e_ChrgPortDoor_Sts, queue-length=1}, provided-interface=PokeCITR_e_ChrgPortDoor_Sts
      PokeCITR_e_ChrgPortLock_FailSts: server-com-spec{operation=PokeCITR_e_ChrgPortLock_FailSts, queue-length=1}, provided-interface=PokeCITR_e_ChrgPortLock_FailSts
      PokeCITR_e_ChrgrFlapSts: server-com-spec{operation=PokeCITR_e_ChrgrFlapSts, queue-length=1}, provided-interface=PokeCITR_e_ChrgrFlapSts
      PokeCITR_e_CoopCh_ChrgCmd: server-com-spec{operation=PokeCITR_e_CoopCh_ChrgCmd, queue-length=1}, provided-interface=PokeCITR_e_CoopCh_ChrgCmd
      PokeCITR_e_DVC_IO_BCIM: server-com-spec{operation=PokeCITR_e_DVC_IO_BCIM, queue-length=1}, provided-interface=PokeCITR_e_DVC_IO_BCIM
      PokeCITR_e_DVC_IO_BCIM_JL: server-com-spec{operation=PokeCITR_e_DVC_IO_BCIM_JL, queue-length=1}, provided-interface=PokeCITR_e_DVC_IO_BCIM_JL
      PokeCITR_e_DVC_IO_CPIM: server-com-spec{operation=PokeCITR_e_DVC_IO_CPIM, queue-length=1}, provided-interface=PokeCITR_e_DVC_IO_CPIM
      PokeCITR_e_DateTmFormat: server-com-spec{operation=PokeCITR_e_DateTmFormat, queue-length=1}, provided-interface=PokeCITR_e_DateTmFormat
      PokeCITR_e_DoorLockLastElSts: server-com-spec{operation=PokeCITR_e_DoorLockLastElSts, queue-length=1}, provided-interface=PokeCITR_e_DoorLockLastElSts
      PokeCITR_e_DoorLockLastElSts_2: server-com-spec{operation=PokeCITR_e_DoorLockLastElSts_2, queue-length=1}, provided-interface=PokeCITR_e_DoorLockLastElSts_2
      PokeCITR_e_FOTA_Install_Type: server-com-spec{operation=PokeCITR_e_FOTA_Install_Type, queue-length=1}, provided-interface=PokeCITR_e_FOTA_Install_Type
      PokeCITR_e_FOTA_Installation_Status: server-com-spec{operation=PokeCITR_e_FOTA_Installation_Status, queue-length=1}, provided-interface=PokeCITR_e_FOTA_Installation_Status
      PokeCITR_e_HU_ChrgSchedType1: server-com-spec{operation=PokeCITR_e_HU_ChrgSchedType1, queue-length=1}, provided-interface=PokeCITR_e_HU_ChrgSchedType1
      PokeCITR_e_HU_ChrgSchedType2: server-com-spec{operation=PokeCITR_e_HU_ChrgSchedType2, queue-length=1}, provided-interface=PokeCITR_e_HU_ChrgSchedType2
      PokeCITR_e_HU_Sch1_Type: server-com-spec{operation=PokeCITR_e_HU_Sch1_Type, queue-length=1}, provided-interface=PokeCITR_e_HU_Sch1_Type
      PokeCITR_e_HU_Sch2_Type: server-com-spec{operation=PokeCITR_e_HU_Sch2_Type, queue-length=1}, provided-interface=PokeCITR_e_HU_Sch2_Type
      PokeCITR_e_HU_Sch3_Allow: server-com-spec{operation=PokeCITR_e_HU_Sch3_Allow, queue-length=1}, provided-interface=PokeCITR_e_HU_Sch3_Allow
      PokeCITR_e_HU_Sch3_Type: server-com-spec{operation=PokeCITR_e_HU_Sch3_Type, queue-length=1}, provided-interface=PokeCITR_e_HU_Sch3_Type
      PokeCITR_e_HU_Sch4_Allow: server-com-spec{operation=PokeCITR_e_HU_Sch4_Allow, queue-length=1}, provided-interface=PokeCITR_e_HU_Sch4_Allow
      PokeCITR_e_PP2Fault: server-com-spec{operation=PokeCITR_e_PP2Fault, queue-length=1}, provided-interface=PokeCITR_e_PP2Fault
      PokeCITR_e_PP2FaultRsn: server-com-spec{operation=PokeCITR_e_PP2FaultRsn, queue-length=1}, provided-interface=PokeCITR_e_PP2FaultRsn
      PokeCITR_e_PP2LEDFault: server-com-spec{operation=PokeCITR_e_PP2LEDFault, queue-length=1}, provided-interface=PokeCITR_e_PP2LEDFault
      PokeCITR_e_PP2_LED_A_ColorFeedback: server-com-spec{operation=PokeCITR_e_PP2_LED_A_ColorFeedback, queue-length=1}, provided-interface=PokeCITR_e_PP2_LED_A_ColorFeedback
      PokeCITR_e_PP2_LED_A_FailSts: server-com-spec{operation=PokeCITR_e_PP2_LED_A_FailSts, queue-length=1}, provided-interface=PokeCITR_e_PP2_LED_A_FailSts
      PokeCITR_e_PP2_LED_A_Feedback: server-com-spec{operation=PokeCITR_e_PP2_LED_A_Feedback, queue-length=1}, provided-interface=PokeCITR_e_PP2_LED_A_Feedback
      PokeCITR_e_PP2_LED_B_ColorFeedback: server-com-spec{operation=PokeCITR_e_PP2_LED_B_ColorFeedback, queue-length=1}, provided-interface=PokeCITR_e_PP2_LED_B_ColorFeedback
      PokeCITR_e_PP2_LED_B_FailSts: server-com-spec{operation=PokeCITR_e_PP2_LED_B_FailSts, queue-length=1}, provided-interface=PokeCITR_e_PP2_LED_B_FailSts
      PokeCITR_e_PP2_LED_B_Feedback: server-com-spec{operation=PokeCITR_e_PP2_LED_B_Feedback, queue-length=1}, provided-interface=PokeCITR_e_PP2_LED_B_Feedback
      PokeCITR_e_PPFault: server-com-spec{operation=PokeCITR_e_PPFault, queue-length=1}, provided-interface=PokeCITR_e_PPFault
      PokeCITR_e_PPFaultRsn: server-com-spec{operation=PokeCITR_e_PPFaultRsn, queue-length=1}, provided-interface=PokeCITR_e_PPFaultRsn
      PokeCITR_e_PPLEDFault: server-com-spec{operation=PokeCITR_e_PPLEDFault, queue-length=1}, provided-interface=PokeCITR_e_PPLEDFault
      PokeCITR_e_PP_LED_A_ColorFeedback: server-com-spec{operation=PokeCITR_e_PP_LED_A_ColorFeedback, queue-length=1}, provided-interface=PokeCITR_e_PP_LED_A_ColorFeedback
      PokeCITR_e_PP_LED_A_FailSts: server-com-spec{operation=PokeCITR_e_PP_LED_A_FailSts, queue-length=1}, provided-interface=PokeCITR_e_PP_LED_A_FailSts
      PokeCITR_e_PP_LED_A_Feedback: server-com-spec{operation=PokeCITR_e_PP_LED_A_Feedback, queue-length=1}, provided-interface=PokeCITR_e_PP_LED_A_Feedback
      PokeCITR_e_PP_LED_B_ColorFeedback: server-com-spec{operation=PokeCITR_e_PP_LED_B_ColorFeedback, queue-length=1}, provided-interface=PokeCITR_e_PP_LED_B_ColorFeedback
      PokeCITR_e_PP_LED_B_FailSts: server-com-spec{operation=PokeCITR_e_PP_LED_B_FailSts, queue-length=1}, provided-interface=PokeCITR_e_PP_LED_B_FailSts
      PokeCITR_e_PP_LED_B_Feedback: server-com-spec{operation=PokeCITR_e_PP_LED_B_Feedback, queue-length=1}, provided-interface=PokeCITR_e_PP_LED_B_Feedback
      PokeCITR_e_PP_LED_C_ColorFeedback: server-com-spec{operation=PokeCITR_e_PP_LED_C_ColorFeedback, queue-length=1}, provided-interface=PokeCITR_e_PP_LED_C_ColorFeedback
      PokeCITR_e_PP_LED_C_FailSts: server-com-spec{operation=PokeCITR_e_PP_LED_C_FailSts, queue-length=1}, provided-interface=PokeCITR_e_PP_LED_C_FailSts
      PokeCITR_e_PP_LED_C_Feedback: server-com-spec{operation=PokeCITR_e_PP_LED_C_Feedback, queue-length=1}, provided-interface=PokeCITR_e_PP_LED_C_Feedback
      PokeCITR_e_PowerLimit_Req: server-com-spec{operation=PokeCITR_e_PowerLimit_Req, queue-length=1}, provided-interface=PokeCITR_e_PowerLimit_Req
      PokeCITR_e_PowerLimit_Req_2: server-com-spec{operation=PokeCITR_e_PowerLimit_Req_2, queue-length=1}, provided-interface=PokeCITR_e_PowerLimit_Req_2
      PokeCITR_e_RmtChrgPortLkCmd: server-com-spec{operation=PokeCITR_e_RmtChrgPortLkCmd, queue-length=1}, provided-interface=PokeCITR_e_RmtChrgPortLkCmd
      PokeCITR_e_TBM_ChrgSchedType1: server-com-spec{operation=PokeCITR_e_TBM_ChrgSchedType1, queue-length=1}, provided-interface=PokeCITR_e_TBM_ChrgSchedType1
      PokeCITR_e_TBM_ChrgSchedType2: server-com-spec{operation=PokeCITR_e_TBM_ChrgSchedType2, queue-length=1}, provided-interface=PokeCITR_e_TBM_ChrgSchedType2
      PokeCITR_e_TBM_Sch1_Type: server-com-spec{operation=PokeCITR_e_TBM_Sch1_Type, queue-length=1}, provided-interface=PokeCITR_e_TBM_Sch1_Type
      PokeCITR_e_TBM_Sch2_Type: server-com-spec{operation=PokeCITR_e_TBM_Sch2_Type, queue-length=1}, provided-interface=PokeCITR_e_TBM_Sch2_Type
      PokeCITR_e_TBM_Sch3_Allow: server-com-spec{operation=PokeCITR_e_TBM_Sch3_Allow, queue-length=1}, provided-interface=PokeCITR_e_TBM_Sch3_Allow
      PokeCITR_e_TBM_Sch3_Type: server-com-spec{operation=PokeCITR_e_TBM_Sch3_Type, queue-length=1}, provided-interface=PokeCITR_e_TBM_Sch3_Type
      PokeCITR_e_TBM_Sch4_Allow: server-com-spec{operation=PokeCITR_e_TBM_Sch4_Allow, queue-length=1}, provided-interface=PokeCITR_e_TBM_Sch4_Allow
      PokeCITR_l_DistanceToCharge: server-com-spec{operation=PokeCITR_l_DistanceToCharge, queue-length=1}, provided-interface=PokeCITR_l_DistanceToCharge
      PokeCITR_t_TimeToCharge: server-com-spec{operation=PokeCITR_t_TimeToCharge, queue-length=1}, provided-interface=PokeCITR_t_TimeToCharge
      TmotCITR_b_ChrgPort_BCM_Cmd: server-com-spec=TmotCITR_b_ChrgPort_BCM_Cmd, provided-interface=TmotCITR_b_ChrgPort_BCM_Cmd
      TmotCITR_b_DC_PwrLev: server-com-spec=TmotCITR_b_DC_PwrLev, provided-interface=TmotCITR_b_DC_PwrLev
      TmotCITR_b_DateTmDay: server-com-spec=TmotCITR_b_DateTmDay, provided-interface=TmotCITR_b_DateTmDay
      TmotCITR_b_Date_Day1: server-com-spec=TmotCITR_b_Date_Day1, provided-interface=TmotCITR_b_Date_Day1
      TmotCITR_b_HU_Sch{1..4}_Day: server-com-spec=TmotCITR_b_HU_Sch{1..4}_Day, provided-interface=TmotCITR_b_HU_Sch{1..4}_Day
      TmotCITR_b_TBM_Sch{1..4}_Day: server-com-spec=TmotCITR_b_TBM_Sch{1..4}_Day, provided-interface=TmotCITR_b_TBM_Sch{1..4}_Day
      TmotCITR_e_DoorLockLastElSts: server-com-spec=TmotCITR_e_DoorLockLastElSts, provided-interface=TmotCITR_e_DoorLockLastElSts
      TmotCITR_e_DoorLockLastElSts_2: server-com-spec=TmotCITR_e_DoorLockLastElSts_2, provided-interface=TmotCITR_e_DoorLockLastElSts_2
      TmotCITR_e_PowerLimitReq: server-com-spec=TmotCITR_e_PowerLimitReq, provided-interface=TmotCITR_e_PowerLimitReq
      TmotCITR_e_PowerLimitReq_2: server-com-spec=TmotCITR_e_PowerLimitReq_2, provided-interface=TmotCITR_e_PowerLimitReq_2
      TmotCITR_e_RmtChrgPortLkCmd: server-com-spec=TmotCITR_e_RmtChrgPortLkCmd, provided-interface=TmotCITR_e_RmtChrgPortLkCmd
    require port NeCITR_b_Lock_Status_Rx: nv-require-com-spec{init-value=0, variable=NeCITR_b_Lock_Status}, required-interface=NeCITR_b_Lock_Status
    require port NeCITR_b_PortLockBCM_Cmd_Rx: nv-require-com-spec{init-value=0, variable=NeCITR_b_PortLockBCM_Cmd}, required-interface=NeCITR_b_PortLockBCM_Cmd
    provide port NeCITR_b_Lock_Status: nv-provide-com-spec{ram-block-init-value=0, variable=NeCITR_b_Lock_Status}, provided-interface=NeCITR_b_Lock_Status
    provide port NeCITR_b_PortLockBCM_Cmd: nv-provide-com-spec{ram-block-init-value=0, variable=NeCITR_b_PortLockBCM_Cmd}, provided-interface=NeCITR_b_PortLockBCM_Cmd
    behavior IB_CITR: data-type-mapping=msADTtoIDTMapping, handle-termination-and-restart=NO-SUPPORT
      timing event Event_FastTEF: start-on-event=CITR_FastTEF, period=0.005
      timing event Event_MedTED: start-on-event=CITR_MedTED, period=0.02
      437 x operation invoked event:
        Event_FsftCITR_I_PP2CurrentDrawSens1: start-on-event=FsftCITR_I_PP2CurrentDrawSens1, operation=FsftCITR_I_PP2CurrentDrawSens1.FsftCITR_I_PP2CurrentDrawSens1
        Event_FsftCITR_I_PP2CurrentDrawSens2: start-on-event=FsftCITR_I_PP2CurrentDrawSens2, operation=FsftCITR_I_PP2CurrentDrawSens2.FsftCITR_I_PP2CurrentDrawSens2
        Event_FsftCITR_I_PPCurrentDrawSens1: start-on-event=FsftCITR_I_PPCurrentDrawSens1, operation=FsftCITR_I_PPCurrentDrawSens1.FsftCITR_I_PPCurrentDrawSens1
        Event_FsftCITR_I_PPCurrentDrawSens2: start-on-event=FsftCITR_I_PPCurrentDrawSens2, operation=FsftCITR_I_PPCurrentDrawSens2.FsftCITR_I_PPCurrentDrawSens2
        Event_FsftCITR_P_ChargingDestinationPwr: start-on-event=FsftCITR_P_ChargingDestinationPwr, operation=FsftCITR_P_ChargingDestinationPwr.FsftCITR_P_ChargingDestinationPwr
        Event_FsftCITR_P_PP2RatedPower: start-on-event=FsftCITR_P_PP2RatedPower, operation=FsftCITR_P_PP2RatedPower.FsftCITR_P_PP2RatedPower
        Event_FsftCITR_P_PPRatedPower: start-on-event=FsftCITR_P_PPRatedPower, operation=FsftCITR_P_PPRatedPower.FsftCITR_P_PPRatedPower
        Event_FsftCITR_Pct_HU_ExtChrgTarget1: start-on-event=FsftCITR_Pct_HU_ExtChrgTarget1, operation=FsftCITR_Pct_HU_ExtChrgTarget1.FsftCITR_Pct_HU_ExtChrgTarget1
        Event_FsftCITR_Pct_HU_ExtChrgTarget2: start-on-event=FsftCITR_Pct_HU_ExtChrgTarget2, operation=FsftCITR_Pct_HU_ExtChrgTarget2.FsftCITR_Pct_HU_ExtChrgTarget2
        Event_FsftCITR_Pct_HU_ImmChrgTarget1: start-on-event=FsftCITR_Pct_HU_ImmChrgTarget1, operation=FsftCITR_Pct_HU_ImmChrgTarget1.FsftCITR_Pct_HU_ImmChrgTarget1
        Event_FsftCITR_Pct_HU_ImmChrgTarget2: start-on-event=FsftCITR_Pct_HU_ImmChrgTarget2, operation=FsftCITR_Pct_HU_ImmChrgTarget2.FsftCITR_Pct_HU_ImmChrgTarget2
        Event_FsftCITR_Pct_TBM_ExtChrgTarget1: start-on-event=FsftCITR_Pct_TBM_ExtChrgTarget1, operation=FsftCITR_Pct_TBM_ExtChrgTarget1.FsftCITR_Pct_TBM_ExtChrgTarget1
        Event_FsftCITR_Pct_TBM_ExtChrgTarget2: start-on-event=FsftCITR_Pct_TBM_ExtChrgTarget2, operation=FsftCITR_Pct_TBM_ExtChrgTarget2.FsftCITR_Pct_TBM_ExtChrgTarget2
        Event_FsftCITR_Pct_TBM_ImmChrgTarget1: start-on-event=FsftCITR_Pct_TBM_ImmChrgTarget1, operation=FsftCITR_Pct_TBM_ImmChrgTarget1.FsftCITR_Pct_TBM_ImmChrgTarget1
        Event_FsftCITR_Pct_TBM_ImmChrgTarget2: start-on-event=FsftCITR_Pct_TBM_ImmChrgTarget2, operation=FsftCITR_Pct_TBM_ImmChrgTarget2.FsftCITR_Pct_TBM_ImmChrgTarget2
        Event_FsftCITR_Pct_V2HRsrvBatt: start-on-event=FsftCITR_Pct_V2HRsrvBatt, operation=FsftCITR_Pct_V2HRsrvBatt.FsftCITR_Pct_V2HRsrvBatt
        Event_FsftCITR_Pct_V2LRsrvBatt: start-on-event=FsftCITR_Pct_V2LRsrvBatt, operation=FsftCITR_Pct_V2LRsrvBatt.FsftCITR_Pct_V2LRsrvBatt
        Event_FsftCITR_Pct_V2VRsrvBatt: start-on-event=FsftCITR_Pct_V2VRsrvBatt, operation=FsftCITR_Pct_V2VRsrvBatt.FsftCITR_Pct_V2VRsrvBatt
        Event_FsftCITR_b_ChrgPortDoor_Sts: start-on-event=FsftCITR_b_ChrgPortDoor_Sts, operation=FsftCITR_b_ChrgPortDoor_Sts.FsftCITR_b_ChrgPortDoor_Sts
        Event_FsftCITR_b_ChrgPortLock_StsC: start-on-event=FsftCITR_b_ChrgPortLock_StsC, operation=FsftCITR_b_ChrgPortLock_StsC.FsftCITR_b_ChrgPortLock_StsC
        Event_FsftCITR_b_ChrgPort_BCM_Cmd: start-on-event=FsftCITR_b_ChrgPort_BCM_Cmd, operation=FsftCITR_b_ChrgPort_BCM_Cmd.FsftCITR_b_ChrgPort_BCM_Cmd
        Event_FsftCITR_b_CoopCh_VehLocation: start-on-event=FsftCITR_b_CoopCh_VehLocation, operation=FsftCITR_b_CoopCh_VehLocation.FsftCITR_b_CoopCh_VehLocation
        Event_FsftCITR_b_DC_PwrLev: start-on-event=FsftCITR_b_DC_PwrLev, operation=FsftCITR_b_DC_PwrLev.FsftCITR_b_DC_PwrLev
        Event_FsftCITR_b_DateTmDay: start-on-event=FsftCITR_b_DateTmDay, operation=FsftCITR_b_DateTmDay.FsftCITR_b_DateTmDay
        Event_FsftCITR_b_DateTmFormat: start-on-event=FsftCITR_b_DateTmFormat, operation=FsftCITR_b_DateTmFormat.FsftCITR_b_DateTmFormat
        Event_FsftCITR_b_Date_Day1: start-on-event=FsftCITR_b_Date_Day1, operation=FsftCITR_b_Date_Day1.FsftCITR_b_Date_Day1
        Event_FsftCITR_b_HU_Sch1_CabTemp: start-on-event=FsftCITR_b_HU_Sch1_CabTemp, operation=FsftCITR_b_HU_Sch1_CabTemp.FsftCITR_b_HU_Sch1_CabTemp
        Event_FsftCITR_b_HU_Sch1_Day: start-on-event=FsftCITR_b_HU_Sch1_Day, operation=FsftCITR_b_HU_Sch1_Day.FsftCITR_b_HU_Sch1_Day
        Event_FsftCITR_b_HU_Sch1_End_Time_Hr: start-on-event=FsftCITR_b_HU_Sch1_End_Time_Hr, operation=FsftCITR_b_HU_Sch1_End_Time_Hr.FsftCITR_b_HU_Sch1_End_Time_Hr
        Event_FsftCITR_b_HU_Sch1_End_Time_Min: start-on-event=FsftCITR_b_HU_Sch1_End_Time_Min, operation=FsftCITR_b_HU_Sch1_End_Time_Min.FsftCITR_b_HU_Sch1_End_Time_Min
        Event_FsftCITR_b_HU_Sch1_Start_Time_Hr: start-on-event=FsftCITR_b_HU_Sch1_Start_Time_Hr, operation=FsftCITR_b_HU_Sch1_Start_Time_Hr.FsftCITR_b_HU_Sch1_Start_Time_Hr
        Event_FsftCITR_b_HU_Sch1_Start_Time_Min: start-on-event=FsftCITR_b_HU_Sch1_Start_Time_Min, operation=FsftCITR_b_HU_Sch1_Start_Time_Min.FsftCITR_b_HU_Sch1_Start_Time_Min
        Event_FsftCITR_b_HU_Sch1_Type: start-on-event=FsftCITR_b_HU_Sch1_Type, operation=FsftCITR_b_HU_Sch1_Type.FsftCITR_b_HU_Sch1_Type
        Event_FsftCITR_b_HU_Sch2_CabTemp: start-on-event=FsftCITR_b_HU_Sch2_CabTemp, operation=FsftCITR_b_HU_Sch2_CabTemp.FsftCITR_b_HU_Sch2_CabTemp
        Event_FsftCITR_b_HU_Sch2_Day: start-on-event=FsftCITR_b_HU_Sch2_Day, operation=FsftCITR_b_HU_Sch2_Day.FsftCITR_b_HU_Sch2_Day
        Event_FsftCITR_b_HU_Sch2_End_Time_Hr: start-on-event=FsftCITR_b_HU_Sch2_End_Time_Hr, operation=FsftCITR_b_HU_Sch2_End_Time_Hr.FsftCITR_b_HU_Sch2_End_Time_Hr
        Event_FsftCITR_b_HU_Sch2_End_Time_Min: start-on-event=FsftCITR_b_HU_Sch2_End_Time_Min, operation=FsftCITR_b_HU_Sch2_End_Time_Min.FsftCITR_b_HU_Sch2_End_Time_Min
        Event_FsftCITR_b_HU_Sch2_Start_Time_Hr: start-on-event=FsftCITR_b_HU_Sch2_Start_Time_Hr, operation=FsftCITR_b_HU_Sch2_Start_Time_Hr.FsftCITR_b_HU_Sch2_Start_Time_Hr
        Event_FsftCITR_b_HU_Sch2_Start_Time_Min: start-on-event=FsftCITR_b_HU_Sch2_Start_Time_Min, operation=FsftCITR_b_HU_Sch2_Start_Time_Min.FsftCITR_b_HU_Sch2_Start_Time_Min
        Event_FsftCITR_b_HU_Sch2_Type: start-on-event=FsftCITR_b_HU_Sch2_Type, operation=FsftCITR_b_HU_Sch2_Type.FsftCITR_b_HU_Sch2_Type
        Event_FsftCITR_b_HU_Sch3_Allow: start-on-event=FsftCITR_b_HU_Sch3_Allow, operation=FsftCITR_b_HU_Sch3_Allow.FsftCITR_b_HU_Sch3_Allow
        Event_FsftCITR_b_HU_Sch3_CabTemp: start-on-event=FsftCITR_b_HU_Sch3_CabTemp, operation=FsftCITR_b_HU_Sch3_CabTemp.FsftCITR_b_HU_Sch3_CabTemp
        Event_FsftCITR_b_HU_Sch3_Day: start-on-event=FsftCITR_b_HU_Sch3_Day, operation=FsftCITR_b_HU_Sch3_Day.FsftCITR_b_HU_Sch3_Day
        Event_FsftCITR_b_HU_Sch3_End_Time_Hr: start-on-event=FsftCITR_b_HU_Sch3_End_Time_Hr, operation=FsftCITR_b_HU_Sch3_End_Time_Hr.FsftCITR_b_HU_Sch3_End_Time_Hr
        Event_FsftCITR_b_HU_Sch3_End_Time_Min: start-on-event=FsftCITR_b_HU_Sch3_End_Time_Min, operation=FsftCITR_b_HU_Sch3_End_Time_Min.FsftCITR_b_HU_Sch3_End_Time_Min
        Event_FsftCITR_b_HU_Sch3_Start_Time_Hr: start-on-event=FsftCITR_b_HU_Sch3_Start_Time_Hr, operation=FsftCITR_b_HU_Sch3_Start_Time_Hr.FsftCITR_b_HU_Sch3_Start_Time_Hr
        Event_FsftCITR_b_HU_Sch3_Start_Time_Min: start-on-event=FsftCITR_b_HU_Sch3_Start_Time_Min, operation=FsftCITR_b_HU_Sch3_Start_Time_Min.FsftCITR_b_HU_Sch3_Start_Time_Min
        Event_FsftCITR_b_HU_Sch3_Type: start-on-event=FsftCITR_b_HU_Sch3_Type, operation=FsftCITR_b_HU_Sch3_Type.FsftCITR_b_HU_Sch3_Type
        Event_FsftCITR_b_HU_Sch4_Allow: start-on-event=FsftCITR_b_HU_Sch4_Allow, operation=FsftCITR_b_HU_Sch4_Allow.FsftCITR_b_HU_Sch4_Allow
        Event_FsftCITR_b_HU_Sch4_CabTemp: start-on-event=FsftCITR_b_HU_Sch4_CabTemp, operation=FsftCITR_b_HU_Sch4_CabTemp.FsftCITR_b_HU_Sch4_CabTemp
        Event_FsftCITR_b_HU_Sch4_Day: start-on-event=FsftCITR_b_HU_Sch4_Day, operation=FsftCITR_b_HU_Sch4_Day.FsftCITR_b_HU_Sch4_Day
        Event_FsftCITR_b_HU_Sch4_Start_Time_Hr: start-on-event=FsftCITR_b_HU_Sch4_Start_Time_Hr, operation=FsftCITR_b_HU_Sch4_Start_Time_Hr.FsftCITR_b_HU_Sch4_Start_Time_Hr
        Event_FsftCITR_b_HU_Sch4_Start_Time_Min: start-on-event=FsftCITR_b_HU_Sch4_Start_Time_Min, operation=FsftCITR_b_HU_Sch4_Start_Time_Min.FsftCITR_b_HU_Sch4_Start_Time_Min
        Event_FsftCITR_b_PP2ACPresentSens1: start-on-event=FsftCITR_b_PP2ACPresentSens1, operation=FsftCITR_b_PP2ACPresentSens1.FsftCITR_b_PP2ACPresentSens1
        Event_FsftCITR_b_PP2ACPresentSens2: start-on-event=FsftCITR_b_PP2ACPresentSens2, operation=FsftCITR_b_PP2ACPresentSens2.FsftCITR_b_PP2ACPresentSens2
        Event_FsftCITR_b_PP2ButtonSts: start-on-event=FsftCITR_b_PP2ButtonSts, operation=FsftCITR_b_PP2ButtonSts.FsftCITR_b_PP2ButtonSts
        Event_FsftCITR_b_PP2LidSwitchSts240: start-on-event=FsftCITR_b_PP2LidSwitchSts240, operation=FsftCITR_b_PP2LidSwitchSts240.FsftCITR_b_PP2LidSwitchSts240
        Event_FsftCITR_b_PP2LidSwitchSts120A: start-on-event=FsftCITR_b_PP2LidSwitchSts120A, operation=FsftCITR_b_PP2LidSwitchSts120A.FsftCITR_b_PP2LidSwitchSts120A
        Event_FsftCITR_b_PP2LidSwitchSts120B: start-on-event=FsftCITR_b_PP2LidSwitchSts120B, operation=FsftCITR_b_PP2LidSwitchSts120B.FsftCITR_b_PP2LidSwitchSts120B
        Event_FsftCITR_b_PP2_Gnd_Fault_Det: start-on-event=FsftCITR_b_PP2_Gnd_Fault_Det, operation=FsftCITR_b_PP2_Gnd_Fault_Det.FsftCITR_b_PP2_Gnd_Fault_Det
        Event_FsftCITR_b_PP2_LIN_Cksm_Err: start-on-event=FsftCITR_b_PP2_LIN_Cksm_Err, operation=FsftCITR_b_PP2_LIN_Cksm_Err.FsftCITR_b_PP2_LIN_Cksm_Err
        Event_FsftCITR_b_PP2_LIN_Data_Err: start-on-event=FsftCITR_b_PP2_LIN_Data_Err, operation=FsftCITR_b_PP2_LIN_Data_Err.FsftCITR_b_PP2_LIN_Data_Err
        Event_FsftCITR_b_PP2_LIN_Parity_Err: start-on-event=FsftCITR_b_PP2_LIN_Parity_Err, operation=FsftCITR_b_PP2_LIN_Parity_Err.FsftCITR_b_PP2_LIN_Parity_Err
        Event_FsftCITR_b_PPACPresentSens1: start-on-event=FsftCITR_b_PPACPresentSens1, operation=FsftCITR_b_PPACPresentSens1.FsftCITR_b_PPACPresentSens1
        Event_FsftCITR_b_PPACPresentSens2: start-on-event=FsftCITR_b_PPACPresentSens2, operation=FsftCITR_b_PPACPresentSens2.FsftCITR_b_PPACPresentSens2
        Event_FsftCITR_b_PPButtonSts: start-on-event=FsftCITR_b_PPButtonSts, operation=FsftCITR_b_PPButtonSts.FsftCITR_b_PPButtonSts
        Event_FsftCITR_b_PPLidSwitchSts120A: start-on-event=FsftCITR_b_PPLidSwitchSts120A, operation=FsftCITR_b_PPLidSwitchSts120A.FsftCITR_b_PPLidSwitchSts120A
        Event_FsftCITR_b_PPLidSwitchSts120B: start-on-event=FsftCITR_b_PPLidSwitchSts120B, operation=FsftCITR_b_PPLidSwitchSts120B.FsftCITR_b_PPLidSwitchSts120B
        Event_FsftCITR_b_PPLidSwitchSts240: start-on-event=FsftCITR_b_PPLidSwitchSts240, operation=FsftCITR_b_PPLidSwitchSts240.FsftCITR_b_PPLidSwitchSts240
        Event_FsftCITR_b_PP_Gnd_Fault_Det: start-on-event=FsftCITR_b_PP_Gnd_Fault_Det, operation=FsftCITR_b_PP_Gnd_Fault_Det.FsftCITR_b_PP_Gnd_Fault_Det
        Event_FsftCITR_b_PP_LIN_Cksm_Err: start-on-event=FsftCITR_b_PP_LIN_Cksm_Err, operation=FsftCITR_b_PP_LIN_Cksm_Err.FsftCITR_b_PP_LIN_Cksm_Err
        Event_FsftCITR_b_PP_LIN_Data_Err: start-on-event=FsftCITR_b_PP_LIN_Data_Err, operation=FsftCITR_b_PP_LIN_Data_Err.FsftCITR_b_PP_LIN_Data_Err
        Event_FsftCITR_b_PP_LIN_Parity_Err: start-on-event=FsftCITR_b_PP_LIN_Parity_Err, operation=FsftCITR_b_PP_LIN_Parity_Err.FsftCITR_b_PP_LIN_Parity_Err
        Event_FsftCITR_b_RsErrSPP: start-on-event=FsftCITR_b_RsErrSPP, operation=FsftCITR_b_RsErrSPP.FsftCITR_b_RsErrSPP
        Event_FsftCITR_b_RsErrSPP2: start-on-event=FsftCITR_b_RsErrSPP2, operation=FsftCITR_b_RsErrSPP2.FsftCITR_b_RsErrSPP2
        Event_FsftCITR_b_SOC_Max_Lev: start-on-event=FsftCITR_b_SOC_Max_Lev, operation=FsftCITR_b_SOC_Max_Lev.FsftCITR_b_SOC_Max_Lev
        Event_FsftCITR_b_TBMStopChrg: start-on-event=FsftCITR_b_TBMStopChrg, operation=FsftCITR_b_TBMStopChrg.FsftCITR_b_TBMStopChrg
        Event_FsftCITR_b_TBM_Sch1_CabTemp: start-on-event=FsftCITR_b_TBM_Sch1_CabTemp, operation=FsftCITR_b_TBM_Sch1_CabTemp.FsftCITR_b_TBM_Sch1_CabTemp
        Event_FsftCITR_b_TBM_Sch1_Day: start-on-event=FsftCITR_b_TBM_Sch1_Day, operation=FsftCITR_b_TBM_Sch1_Day.FsftCITR_b_TBM_Sch1_Day
        Event_FsftCITR_b_TBM_Sch1_End_Time_Hr: start-on-event=FsftCITR_b_TBM_Sch1_End_Time_Hr, operation=FsftCITR_b_TBM_Sch1_End_Time_Hr.FsftCITR_b_TBM_Sch1_End_Time_Hr
        Event_FsftCITR_b_TBM_Sch1_End_Time_Min: start-on-event=FsftCITR_b_TBM_Sch1_End_Time_Min, operation=FsftCITR_b_TBM_Sch1_End_Time_Min.FsftCITR_b_TBM_Sch1_End_Time_Min
        Event_FsftCITR_b_TBM_Sch1_Start_Time_Hr: start-on-event=FsftCITR_b_TBM_Sch1_Start_Time_Hr, operation=FsftCITR_b_TBM_Sch1_Start_Time_Hr.FsftCITR_b_TBM_Sch1_Start_Time_Hr
        Event_FsftCITR_b_TBM_Sch1_Start_Time_Min: start-on-event=FsftCITR_b_TBM_Sch1_Start_Time_Min, operation=FsftCITR_b_TBM_Sch1_Start_Time_Min.FsftCITR_b_TBM_Sch1_Start_Time_Min
        Event_FsftCITR_b_TBM_Sch1_Type: start-on-event=FsftCITR_b_TBM_Sch1_Type, operation=FsftCITR_b_TBM_Sch1_Type.FsftCITR_b_TBM_Sch1_Type
        Event_FsftCITR_b_TBM_Sch2_CabTemp: start-on-event=FsftCITR_b_TBM_Sch2_CabTemp, operation=FsftCITR_b_TBM_Sch2_CabTemp.FsftCITR_b_TBM_Sch2_CabTemp
        Event_FsftCITR_b_TBM_Sch2_Day: start-on-event=FsftCITR_b_TBM_Sch2_Day, operation=FsftCITR_b_TBM_Sch2_Day.FsftCITR_b_TBM_Sch2_Day
        Event_FsftCITR_b_TBM_Sch2_End_Time_Hr: start-on-event=FsftCITR_b_TBM_Sch2_End_Time_Hr, operation=FsftCITR_b_TBM_Sch2_End_Time_Hr.FsftCITR_b_TBM_Sch2_End_Time_Hr
        Event_FsftCITR_b_TBM_Sch2_End_Time_Min: start-on-event=FsftCITR_b_TBM_Sch2_End_Time_Min, operation=FsftCITR_b_TBM_Sch2_End_Time_Min.FsftCITR_b_TBM_Sch2_End_Time_Min
        Event_FsftCITR_b_TBM_Sch2_Start_Time_Hr: start-on-event=FsftCITR_b_TBM_Sch2_Start_Time_Hr, operation=FsftCITR_b_TBM_Sch2_Start_Time_Hr.FsftCITR_b_TBM_Sch2_Start_Time_Hr
        Event_FsftCITR_b_TBM_Sch2_Start_Time_Min: start-on-event=FsftCITR_b_TBM_Sch2_Start_Time_Min, operation=FsftCITR_b_TBM_Sch2_Start_Time_Min.FsftCITR_b_TBM_Sch2_Start_Time_Min
        Event_FsftCITR_b_TBM_Sch2_Type: start-on-event=FsftCITR_b_TBM_Sch2_Type, operation=FsftCITR_b_TBM_Sch2_Type.FsftCITR_b_TBM_Sch2_Type
        Event_FsftCITR_b_TBM_Sch3_Allow: start-on-event=FsftCITR_b_TBM_Sch3_Allow, operation=FsftCITR_b_TBM_Sch3_Allow.FsftCITR_b_TBM_Sch3_Allow
        Event_FsftCITR_b_TBM_Sch3_CabTemp: start-on-event=FsftCITR_b_TBM_Sch3_CabTemp, operation=FsftCITR_b_TBM_Sch3_CabTemp.FsftCITR_b_TBM_Sch3_CabTemp
        Event_FsftCITR_b_TBM_Sch3_Day: start-on-event=FsftCITR_b_TBM_Sch3_Day, operation=FsftCITR_b_TBM_Sch3_Day.FsftCITR_b_TBM_Sch3_Day
        Event_FsftCITR_b_TBM_Sch3_End_Time_Hr: start-on-event=FsftCITR_b_TBM_Sch3_End_Time_Hr, operation=FsftCITR_b_TBM_Sch3_End_Time_Hr.FsftCITR_b_TBM_Sch3_End_Time_Hr
        Event_FsftCITR_b_TBM_Sch3_End_Time_Min: start-on-event=FsftCITR_b_TBM_Sch3_End_Time_Min, operation=FsftCITR_b_TBM_Sch3_End_Time_Min.FsftCITR_b_TBM_Sch3_End_Time_Min
        Event_FsftCITR_b_TBM_Sch3_Start_Time_Hr: start-on-event=FsftCITR_b_TBM_Sch3_Start_Time_Hr, operation=FsftCITR_b_TBM_Sch3_Start_Time_Hr.FsftCITR_b_TBM_Sch3_Start_Time_Hr
        Event_FsftCITR_b_TBM_Sch3_Start_Time_Min: start-on-event=FsftCITR_b_TBM_Sch3_Start_Time_Min, operation=FsftCITR_b_TBM_Sch3_Start_Time_Min.FsftCITR_b_TBM_Sch3_Start_Time_Min
        Event_FsftCITR_b_TBM_Sch3_Type: start-on-event=FsftCITR_b_TBM_Sch3_Type, operation=FsftCITR_b_TBM_Sch3_Type.FsftCITR_b_TBM_Sch3_Type
        Event_FsftCITR_b_TBM_Sch4_Allow: start-on-event=FsftCITR_b_TBM_Sch4_Allow, operation=FsftCITR_b_TBM_Sch4_Allow.FsftCITR_b_TBM_Sch4_Allow
        Event_FsftCITR_b_TBM_Sch4_CabTemp: start-on-event=FsftCITR_b_TBM_Sch4_CabTemp, operation=FsftCITR_b_TBM_Sch4_CabTemp.FsftCITR_b_TBM_Sch4_CabTemp
        Event_FsftCITR_b_TBM_Sch4_Day: start-on-event=FsftCITR_b_TBM_Sch4_Day, operation=FsftCITR_b_TBM_Sch4_Day.FsftCITR_b_TBM_Sch4_Day
        Event_FsftCITR_b_TBM_Sch4_Start_Time_Hr: start-on-event=FsftCITR_b_TBM_Sch4_Start_Time_Hr, operation=FsftCITR_b_TBM_Sch4_Start_Time_Hr.FsftCITR_b_TBM_Sch4_Start_Time_Hr
        Event_FsftCITR_b_TBM_Sch4_Start_Time_Min: start-on-event=FsftCITR_b_TBM_Sch4_Start_Time_Min, operation=FsftCITR_b_TBM_Sch4_Start_Time_Min.FsftCITR_b_TBM_Sch4_Start_Time_Min
        Event_FsftCITR_b_V2HModeReq: start-on-event=FsftCITR_b_V2HModeReq, operation=FsftCITR_b_V2HModeReq.FsftCITR_b_V2HModeReq
        Event_FsftCITR_b_V2HReq: start-on-event=FsftCITR_b_V2HReq, operation=FsftCITR_b_V2HReq.FsftCITR_b_V2HReq
        Event_FsftCITR_b_V2HSubmit: start-on-event=FsftCITR_b_V2HSubmit, operation=FsftCITR_b_V2HSubmit.FsftCITR_b_V2HSubmit
        Event_FsftCITR_b_V2LModeReq: start-on-event=FsftCITR_b_V2LModeReq, operation=FsftCITR_b_V2LModeReq.FsftCITR_b_V2LModeReq
        Event_FsftCITR_b_V2LSubmit: start-on-event=FsftCITR_b_V2LSubmit, operation=FsftCITR_b_V2LSubmit.FsftCITR_b_V2LSubmit
        Event_FsftCITR_b_V2LTrunkReq: start-on-event=FsftCITR_b_V2LTrunkReq, operation=FsftCITR_b_V2LTrunkReq.FsftCITR_b_V2LTrunkReq
        Event_FsftCITR_b_V2L_AllReq: start-on-event=FsftCITR_b_V2L_AllReq, operation=FsftCITR_b_V2L_AllReq.FsftCITR_b_V2L_AllReq
        Event_FsftCITR_b_V2L_FrunkReq: start-on-event=FsftCITR_b_V2L_FrunkReq, operation=FsftCITR_b_V2L_FrunkReq.FsftCITR_b_V2L_FrunkReq
        Event_FsftCITR_b_V2VModeReq: start-on-event=FsftCITR_b_V2VModeReq, operation=FsftCITR_b_V2VModeReq.FsftCITR_b_V2VModeReq
        Event_FsftCITR_b_V2VReq: start-on-event=FsftCITR_b_V2VReq, operation=FsftCITR_b_V2VReq.FsftCITR_b_V2VReq
        Event_FsftCITR_b_V2VSubmit: start-on-event=FsftCITR_b_V2VSubmit, operation=FsftCITR_b_V2VSubmit.FsftCITR_b_V2VSubmit
        Event_FsftCITR_e_BCIM_Ind{1..5}_Fdbk: start-on-event=FsftCITR_e_BCIM_Ind{1..5}_Fdbk, operation=FsftCITR_e_BCIM_Ind{1..5}_Fdbk.FsftCITR_e_BCIM_Ind{1..5}_Fdbk
        Event_FsftCITR_e_BCIM_Ind_Color_Fdbk: start-on-event=FsftCITR_e_BCIM_Ind_Color_Fdbk, operation=FsftCITR_e_BCIM_Ind_Color_Fdbk.FsftCITR_e_BCIM_Ind_Color_Fdbk
        Event_FsftCITR_e_CPIM_Icon1_Sts: start-on-event=FsftCITR_e_CPIM_Icon1_Sts, operation=FsftCITR_e_CPIM_Icon1_Sts.FsftCITR_e_CPIM_Icon1_Sts
        Event_FsftCITR_e_CPIM_Icon2_Sts: start-on-event=FsftCITR_e_CPIM_Icon2_Sts, operation=FsftCITR_e_CPIM_Icon2_Sts.FsftCITR_e_CPIM_Icon2_Sts
        Event_FsftCITR_e_CPIM_Ind{1..5}_Fdbk: start-on-event=FsftCITR_e_CPIM_Ind{1..5}_Fdbk, operation=FsftCITR_e_CPIM_Ind{1..5}_Fdbk.FsftCITR_e_CPIM_Ind{1..5}_Fdbk
        Event_FsftCITR_e_CPIM_Ind_Color_Fdbk: start-on-event=FsftCITR_e_CPIM_Ind_Color_Fdbk, operation=FsftCITR_e_CPIM_Ind_Color_Fdbk.FsftCITR_e_CPIM_Ind_Color_Fdbk
        Event_FsftCITR_e_ChrgPortLock_FailSts: start-on-event=FsftCITR_e_ChrgPortLock_FailSts, operation=FsftCITR_e_ChrgPortLock_FailSts.FsftCITR_e_ChrgPortLock_FailSts
        Event_FsftCITR_e_ChrgrFlapSts: start-on-event=FsftCITR_e_ChrgrFlapSts, operation=FsftCITR_e_ChrgrFlapSts.FsftCITR_e_ChrgrFlapSts
        Event_FsftCITR_e_CoopCh_ChrgCmd: start-on-event=FsftCITR_e_CoopCh_ChrgCmd, operation=FsftCITR_e_CoopCh_ChrgCmd.FsftCITR_e_CoopCh_ChrgCmd
        Event_FsftCITR_e_DoorLockLastElSts: start-on-event=FsftCITR_e_DoorLockLastElSts, operation=FsftCITR_e_DoorLockLastElSts.FsftCITR_e_DoorLockLastElSts
        Event_FsftCITR_e_DoorLockLastElSts_2: start-on-event=FsftCITR_e_DoorLockLastElSts_2, operation=FsftCITR_e_DoorLockLastElSts_2.FsftCITR_e_DoorLockLastElSts_2
        Event_FsftCITR_e_FOTA_Install_Type: start-on-event=FsftCITR_e_FOTA_Install_Type, operation=FsftCITR_e_FOTA_Install_Type.FsftCITR_e_FOTA_Install_Type
        Event_FsftCITR_e_HU_ChrgSchedType1: start-on-event=FsftCITR_e_HU_ChrgSchedType1, operation=FsftCITR_e_HU_ChrgSchedType1.FsftCITR_e_HU_ChrgSchedType1
        Event_FsftCITR_e_HU_ChrgSchedType2: start-on-event=FsftCITR_e_HU_ChrgSchedType2, operation=FsftCITR_e_HU_ChrgSchedType2.FsftCITR_e_HU_ChrgSchedType2
        Event_FsftCITR_e_PP2Fault: start-on-event=FsftCITR_e_PP2Fault, operation=FsftCITR_e_PP2Fault.FsftCITR_e_PP2Fault
        Event_FsftCITR_e_PP2FaultRsn: start-on-event=FsftCITR_e_PP2FaultRsn, operation=FsftCITR_e_PP2FaultRsn.FsftCITR_e_PP2FaultRsn
        Event_FsftCITR_e_PP2LEDFault: start-on-event=FsftCITR_e_PP2LEDFault, operation=FsftCITR_e_PP2LEDFault.FsftCITR_e_PP2LEDFault
        Event_FsftCITR_e_PP2_LED_A_ColorFeedback: start-on-event=FsftCITR_e_PP2_LED_A_ColorFeedback, operation=FsftCITR_e_PP2_LED_A_ColorFeedback.FsftCITR_e_PP2_LED_A_ColorFeedback
        Event_FsftCITR_e_PP2_LED_A_FailSts: start-on-event=FsftCITR_e_PP2_LED_A_FailSts, operation=FsftCITR_e_PP2_LED_A_FailSts.FsftCITR_e_PP2_LED_A_FailSts
        Event_FsftCITR_e_PP2_LED_A_Feedback: start-on-event=FsftCITR_e_PP2_LED_A_Feedback, operation=FsftCITR_e_PP2_LED_A_Feedback.FsftCITR_e_PP2_LED_A_Feedback
        Event_FsftCITR_e_PP2_LED_B_FailSts: start-on-event=FsftCITR_e_PP2_LED_B_FailSts, operation=FsftCITR_e_PP2_LED_B_FailSts.FsftCITR_e_PP2_LED_B_FailSts
        Event_FsftCITR_e_PP2_LED_B_Feedback: start-on-event=FsftCITR_e_PP2_LED_B_Feedback, operation=FsftCITR_e_PP2_LED_B_Feedback.FsftCITR_e_PP2_LED_B_Feedback
        Event_FsftCITR_e_PPFault: start-on-event=FsftCITR_e_PPFault, operation=FsftCITR_e_PPFault.FsftCITR_e_PPFault
        Event_FsftCITR_e_PPFaultRsn: start-on-event=FsftCITR_e_PPFaultRsn, operation=FsftCITR_e_PPFaultRsn.FsftCITR_e_PPFaultRsn
        Event_FsftCITR_e_PPLEDFault: start-on-event=FsftCITR_e_PPLEDFault, operation=FsftCITR_e_PPLEDFault.FsftCITR_e_PPLEDFault
        Event_FsftCITR_e_PP_LED_A_ColorFeedback: start-on-event=FsftCITR_e_PP_LED_A_ColorFeedback, operation=FsftCITR_e_PP_LED_A_ColorFeedback.FsftCITR_e_PP_LED_A_ColorFeedback
        Event_FsftCITR_e_PP_LED_A_FailSts: start-on-event=FsftCITR_e_PP_LED_A_FailSts, operation=FsftCITR_e_PP_LED_A_FailSts.FsftCITR_e_PP_LED_A_FailSts
        Event_FsftCITR_e_PP_LED_A_Feedback: start-on-event=FsftCITR_e_PP_LED_A_Feedback, operation=FsftCITR_e_PP_LED_A_Feedback.FsftCITR_e_PP_LED_A_Feedback
        Event_FsftCITR_e_PP_LED_B_ColorFeedback: start-on-event=FsftCITR_e_PP_LED_B_ColorFeedback, operation=FsftCITR_e_PP_LED_B_ColorFeedback.FsftCITR_e_PP_LED_B_ColorFeedback
        Event_FsftCITR_e_PP2_LED_B_ColorFeedback: start-on-event=FsftCITR_e_PP2_LED_B_ColorFeedback, operation=FsftCITR_e_PP2_LED_B_ColorFeedback.FsftCITR_e_PP2_LED_B_ColorFeedback
        Event_FsftCITR_e_PP_LED_B_FailSts: start-on-event=FsftCITR_e_PP_LED_B_FailSts, operation=FsftCITR_e_PP_LED_B_FailSts.FsftCITR_e_PP_LED_B_FailSts
        Event_FsftCITR_e_PP_LED_B_Feedback: start-on-event=FsftCITR_e_PP_LED_B_Feedback, operation=FsftCITR_e_PP_LED_B_Feedback.FsftCITR_e_PP_LED_B_Feedback
        Event_FsftCITR_e_PP_LED_C_ColorFeedback: start-on-event=FsftCITR_e_PP_LED_C_ColorFeedback, operation=FsftCITR_e_PP_LED_C_ColorFeedback.FsftCITR_e_PP_LED_C_ColorFeedback
        Event_FsftCITR_e_PP_LED_C_FailSts: start-on-event=FsftCITR_e_PP_LED_C_FailSts, operation=FsftCITR_e_PP_LED_C_FailSts.FsftCITR_e_PP_LED_C_FailSts
        Event_FsftCITR_e_PP_LED_C_Feedback: start-on-event=FsftCITR_e_PP_LED_C_Feedback, operation=FsftCITR_e_PP_LED_C_Feedback.FsftCITR_e_PP_LED_C_Feedback
        Event_FsftCITR_e_PowerLimitReq: start-on-event=FsftCITR_e_PowerLimitReq, operation=FsftCITR_e_PowerLimitReq.FsftCITR_e_PowerLimitReq
        Event_FsftCITR_e_PowerLimitReq_2: start-on-event=FsftCITR_e_PowerLimitReq_2, operation=FsftCITR_e_PowerLimitReq_2.FsftCITR_e_PowerLimitReq_2
        Event_FsftCITR_e_RmtChrgPortLkCmd: start-on-event=FsftCITR_e_RmtChrgPortLkCmd, operation=FsftCITR_e_RmtChrgPortLkCmd.FsftCITR_e_RmtChrgPortLkCmd
        Event_FsftCITR_e_TBM_ChrgSchedType1: start-on-event=FsftCITR_e_TBM_ChrgSchedType1, operation=FsftCITR_e_TBM_ChrgSchedType1.FsftCITR_e_TBM_ChrgSchedType1
        Event_FsftCITR_e_TBM_ChrgSchedType2: start-on-event=FsftCITR_e_TBM_ChrgSchedType2, operation=FsftCITR_e_TBM_ChrgSchedType2.FsftCITR_e_TBM_ChrgSchedType2
        Event_FsftCITR_l_DistanceToCharge: start-on-event=FsftCITR_l_DistanceToCharge, operation=FsftCITR_l_DistanceToCharge.FsftCITR_l_DistanceToCharge
        Event_FsftCITR_t_TimeToCharge: start-on-event=FsftCITR_t_TimeToCharge, operation=FsftCITR_t_TimeToCharge.FsftCITR_t_TimeToCharge
        Event_PokeCITR_I_PP2CurrentDrawSens1: start-on-event=PokeCITR_I_PP2CurrentDrawSens1, operation=PokeCITR_I_PP2CurrentDrawSens1.PokeCITR_I_PP2CurrentDrawSens1
        Event_PokeCITR_I_PP2CurrentDrawSens2: start-on-event=PokeCITR_I_PP2CurrentDrawSens2, operation=PokeCITR_I_PP2CurrentDrawSens2.PokeCITR_I_PP2CurrentDrawSens2
        Event_PokeCITR_I_PPCurrentDrawSens1: start-on-event=PokeCITR_I_PPCurrentDrawSens1, operation=PokeCITR_I_PPCurrentDrawSens1.PokeCITR_I_PPCurrentDrawSens1
        Event_PokeCITR_I_PPCurrentDrawSens2: start-on-event=PokeCITR_I_PPCurrentDrawSens2, operation=PokeCITR_I_PPCurrentDrawSens2.PokeCITR_I_PPCurrentDrawSens2
        Event_PokeCITR_K_ChrgPortHbridgeFlt: start-on-event=PokeCITR_K_ChrgPortHbridgeFlt, operation=PokeCITR_K_ChrgPortHbridgeFlt.PokeCITR_K_ChrgPortHbridgeFlt
        Event_PokeCITR_K_DateTmDay: start-on-event=PokeCITR_K_DateTmDay, operation=PokeCITR_K_DateTmDay.PokeCITR_K_DateTmDay
        Event_PokeCITR_K_DateTmHour: start-on-event=PokeCITR_K_DateTmHour, operation=PokeCITR_K_DateTmHour.PokeCITR_K_DateTmHour
        Event_PokeCITR_K_DateTmMin: start-on-event=PokeCITR_K_DateTmMin, operation=PokeCITR_K_DateTmMin.PokeCITR_K_DateTmMin
        Event_PokeCITR_K_DateTmMon: start-on-event=PokeCITR_K_DateTmMon, operation=PokeCITR_K_DateTmMon.PokeCITR_K_DateTmMon
        Event_PokeCITR_K_DateTmSec: start-on-event=PokeCITR_K_DateTmSec, operation=PokeCITR_K_DateTmSec.PokeCITR_K_DateTmSec
        Event_PokeCITR_K_DateTmYear: start-on-event=PokeCITR_K_DateTmYear, operation=PokeCITR_K_DateTmYear.PokeCITR_K_DateTmYear
        Event_PokeCITR_K_Date_Day1: start-on-event=PokeCITR_K_Date_Day1, operation=PokeCITR_K_Date_Day1.PokeCITR_K_Date_Day1
        Event_PokeCITR_K_Date_Day2: start-on-event=PokeCITR_K_Date_Day2, operation=PokeCITR_K_Date_Day2.PokeCITR_K_Date_Day2
        Event_PokeCITR_K_Date_Month1: start-on-event=PokeCITR_K_Date_Month1, operation=PokeCITR_K_Date_Month1.PokeCITR_K_Date_Month1
        Event_PokeCITR_K_Date_Month2: start-on-event=PokeCITR_K_Date_Month2, operation=PokeCITR_K_Date_Month2.PokeCITR_K_Date_Month2
        Event_PokeCITR_K_Date_Year{1..4}: start-on-event=PokeCITR_K_Date_Year{1..4}, operation=PokeCITR_K_Date_Year{1..4}.PokeCITR_K_Date_Year{1..4}
        Event_PokeCITR_K_HU_Sch1_Day: start-on-event=PokeCITR_K_HU_Sch1_Day, operation=PokeCITR_K_HU_Sch1_Day.PokeCITR_K_HU_Sch1_Day
        Event_PokeCITR_K_HU_Sch1_End_Time_Hr: start-on-event=PokeCITR_K_HU_Sch1_End_Time_Hr, operation=PokeCITR_K_HU_Sch1_End_Time_Hr.PokeCITR_K_HU_Sch1_End_Time_Hr
        Event_PokeCITR_K_HU_Sch1_End_Time_Min: start-on-event=PokeCITR_K_HU_Sch1_End_Time_Min, operation=PokeCITR_K_HU_Sch1_End_Time_Min.PokeCITR_K_HU_Sch1_End_Time_Min
        Event_PokeCITR_K_HU_Sch1_Start_Time_Hr: start-on-event=PokeCITR_K_HU_Sch1_Start_Time_Hr, operation=PokeCITR_K_HU_Sch1_Start_Time_Hr.PokeCITR_K_HU_Sch1_Start_Time_Hr
        Event_PokeCITR_K_HU_Sch1_Start_Time_Min: start-on-event=PokeCITR_K_HU_Sch1_Start_Time_Min, operation=PokeCITR_K_HU_Sch1_Start_Time_Min.PokeCITR_K_HU_Sch1_Start_Time_Min
        Event_PokeCITR_K_HU_Sch2_Day: start-on-event=PokeCITR_K_HU_Sch2_Day, operation=PokeCITR_K_HU_Sch2_Day.PokeCITR_K_HU_Sch2_Day
        Event_PokeCITR_K_HU_Sch2_End_Time_Hr: start-on-event=PokeCITR_K_HU_Sch2_End_Time_Hr, operation=PokeCITR_K_HU_Sch2_End_Time_Hr.PokeCITR_K_HU_Sch2_End_Time_Hr
        Event_PokeCITR_K_HU_Sch2_End_Time_Min: start-on-event=PokeCITR_K_HU_Sch2_End_Time_Min, operation=PokeCITR_K_HU_Sch2_End_Time_Min.PokeCITR_K_HU_Sch2_End_Time_Min
        Event_PokeCITR_K_HU_Sch2_Start_Time_Hr: start-on-event=PokeCITR_K_HU_Sch2_Start_Time_Hr, operation=PokeCITR_K_HU_Sch2_Start_Time_Hr.PokeCITR_K_HU_Sch2_Start_Time_Hr
        Event_PokeCITR_K_HU_Sch2_Start_Time_Min: start-on-event=PokeCITR_K_HU_Sch2_Start_Time_Min, operation=PokeCITR_K_HU_Sch2_Start_Time_Min.PokeCITR_K_HU_Sch2_Start_Time_Min
        Event_PokeCITR_K_HU_Sch3_Day: start-on-event=PokeCITR_K_HU_Sch3_Day, operation=PokeCITR_K_HU_Sch3_Day.PokeCITR_K_HU_Sch3_Day
        Event_PokeCITR_K_HU_Sch3_End_Time_Hr: start-on-event=PokeCITR_K_HU_Sch3_End_Time_Hr, operation=PokeCITR_K_HU_Sch3_End_Time_Hr.PokeCITR_K_HU_Sch3_End_Time_Hr
        Event_PokeCITR_K_HU_Sch3_End_Time_Min: start-on-event=PokeCITR_K_HU_Sch3_End_Time_Min, operation=PokeCITR_K_HU_Sch3_End_Time_Min.PokeCITR_K_HU_Sch3_End_Time_Min
        Event_PokeCITR_K_HU_Sch3_Start_Time_Hr: start-on-event=PokeCITR_K_HU_Sch3_Start_Time_Hr, operation=PokeCITR_K_HU_Sch3_Start_Time_Hr.PokeCITR_K_HU_Sch3_Start_Time_Hr
        Event_PokeCITR_K_HU_Sch3_Start_Time_Min: start-on-event=PokeCITR_K_HU_Sch3_Start_Time_Min, operation=PokeCITR_K_HU_Sch3_Start_Time_Min.PokeCITR_K_HU_Sch3_Start_Time_Min
        Event_PokeCITR_K_HU_Sch4_Day: start-on-event=PokeCITR_K_HU_Sch4_Day, operation=PokeCITR_K_HU_Sch4_Day.PokeCITR_K_HU_Sch4_Day
        Event_PokeCITR_K_HU_Sch4_Start_Time_Hr: start-on-event=PokeCITR_K_HU_Sch4_Start_Time_Hr, operation=PokeCITR_K_HU_Sch4_Start_Time_Hr.PokeCITR_K_HU_Sch4_Start_Time_Hr
        Event_PokeCITR_K_HU_Sch4_Start_Time_Min: start-on-event=PokeCITR_K_HU_Sch4_Start_Time_Min, operation=PokeCITR_K_HU_Sch4_Start_Time_Min.PokeCITR_K_HU_Sch4_Start_Time_Min
        Event_PokeCITR_K_TBM_Sch1_Day: start-on-event=PokeCITR_K_TBM_Sch1_Day, operation=PokeCITR_K_TBM_Sch1_Day.PokeCITR_K_TBM_Sch1_Day
        Event_PokeCITR_K_TBM_Sch1_End_Time_Hr: start-on-event=PokeCITR_K_TBM_Sch1_End_Time_Hr, operation=PokeCITR_K_TBM_Sch1_End_Time_Hr.PokeCITR_K_TBM_Sch1_End_Time_Hr
        Event_PokeCITR_K_TBM_Sch1_End_Time_Min: start-on-event=PokeCITR_K_TBM_Sch1_End_Time_Min, operation=PokeCITR_K_TBM_Sch1_End_Time_Min.PokeCITR_K_TBM_Sch1_End_Time_Min
        Event_PokeCITR_K_TBM_Sch1_Start_Time_Hr: start-on-event=PokeCITR_K_TBM_Sch1_Start_Time_Hr, operation=PokeCITR_K_TBM_Sch1_Start_Time_Hr.PokeCITR_K_TBM_Sch1_Start_Time_Hr
        Event_PokeCITR_K_TBM_Sch1_Start_Time_Min: start-on-event=PokeCITR_K_TBM_Sch1_Start_Time_Min, operation=PokeCITR_K_TBM_Sch1_Start_Time_Min.PokeCITR_K_TBM_Sch1_Start_Time_Min
        Event_PokeCITR_K_TBM_Sch2_Day: start-on-event=PokeCITR_K_TBM_Sch2_Day, operation=PokeCITR_K_TBM_Sch2_Day.PokeCITR_K_TBM_Sch2_Day
        Event_PokeCITR_K_TBM_Sch2_End_Time_Hr: start-on-event=PokeCITR_K_TBM_Sch2_End_Time_Hr, operation=PokeCITR_K_TBM_Sch2_End_Time_Hr.PokeCITR_K_TBM_Sch2_End_Time_Hr
        Event_PokeCITR_K_TBM_Sch2_End_Time_Min: start-on-event=PokeCITR_K_TBM_Sch2_End_Time_Min, operation=PokeCITR_K_TBM_Sch2_End_Time_Min.PokeCITR_K_TBM_Sch2_End_Time_Min
        Event_PokeCITR_K_TBM_Sch2_Start_Time_Hr: start-on-event=PokeCITR_K_TBM_Sch2_Start_Time_Hr, operation=PokeCITR_K_TBM_Sch2_Start_Time_Hr.PokeCITR_K_TBM_Sch2_Start_Time_Hr
        Event_PokeCITR_K_TBM_Sch2_Start_Time_Min: start-on-event=PokeCITR_K_TBM_Sch2_Start_Time_Min, operation=PokeCITR_K_TBM_Sch2_Start_Time_Min.PokeCITR_K_TBM_Sch2_Start_Time_Min
        Event_PokeCITR_K_TBM_Sch3_Day: start-on-event=PokeCITR_K_TBM_Sch3_Day, operation=PokeCITR_K_TBM_Sch3_Day.PokeCITR_K_TBM_Sch3_Day
        Event_PokeCITR_K_TBM_Sch3_End_Time_Hr: start-on-event=PokeCITR_K_TBM_Sch3_End_Time_Hr, operation=PokeCITR_K_TBM_Sch3_End_Time_Hr.PokeCITR_K_TBM_Sch3_End_Time_Hr
        Event_PokeCITR_K_TBM_Sch3_End_Time_Min: start-on-event=PokeCITR_K_TBM_Sch3_End_Time_Min, operation=PokeCITR_K_TBM_Sch3_End_Time_Min.PokeCITR_K_TBM_Sch3_End_Time_Min
        Event_PokeCITR_K_TBM_Sch3_Start_Time_Hr: start-on-event=PokeCITR_K_TBM_Sch3_Start_Time_Hr, operation=PokeCITR_K_TBM_Sch3_Start_Time_Hr.PokeCITR_K_TBM_Sch3_Start_Time_Hr
        Event_PokeCITR_K_TBM_Sch3_Start_Time_Min: start-on-event=PokeCITR_K_TBM_Sch3_Start_Time_Min, operation=PokeCITR_K_TBM_Sch3_Start_Time_Min.PokeCITR_K_TBM_Sch3_Start_Time_Min
        Event_PokeCITR_K_TBM_Sch4_Day: start-on-event=PokeCITR_K_TBM_Sch4_Day, operation=PokeCITR_K_TBM_Sch4_Day.PokeCITR_K_TBM_Sch4_Day
        Event_PokeCITR_K_TBM_Sch4_Start_Time_Hr: start-on-event=PokeCITR_K_TBM_Sch4_Start_Time_Hr, operation=PokeCITR_K_TBM_Sch4_Start_Time_Hr.PokeCITR_K_TBM_Sch4_Start_Time_Hr
        Event_PokeCITR_K_TBM_Sch4_Start_Time_Min: start-on-event=PokeCITR_K_TBM_Sch4_Start_Time_Min, operation=PokeCITR_K_TBM_Sch4_Start_Time_Min.PokeCITR_K_TBM_Sch4_Start_Time_Min
        Event_PokeCITR_K_Time_Hour1: start-on-event=PokeCITR_K_Time_Hour1, operation=PokeCITR_K_Time_Hour1.PokeCITR_K_Time_Hour1
        Event_PokeCITR_K_Time_Hour2: start-on-event=PokeCITR_K_Time_Hour2, operation=PokeCITR_K_Time_Hour2.PokeCITR_K_Time_Hour2
        Event_PokeCITR_K_Time_Minute1: start-on-event=PokeCITR_K_Time_Minute1, operation=PokeCITR_K_Time_Minute1.PokeCITR_K_Time_Minute1
        Event_PokeCITR_K_Time_Minute2: start-on-event=PokeCITR_K_Time_Minute2, operation=PokeCITR_K_Time_Minute2.PokeCITR_K_Time_Minute2
        Event_PokeCITR_P_ChargingDestinationPwr: start-on-event=PokeCITR_P_ChargingDestinationPwr, operation=PokeCITR_P_ChargingDestinationPwr.PokeCITR_P_ChargingDestinationPwr
        Event_PokeCITR_P_PP2RatedPower: start-on-event=PokeCITR_P_PP2RatedPower, operation=PokeCITR_P_PP2RatedPower.PokeCITR_P_PP2RatedPower
        Event_PokeCITR_P_PPRatedPower: start-on-event=PokeCITR_P_PPRatedPower, operation=PokeCITR_P_PPRatedPower.PokeCITR_P_PPRatedPower
        Event_PokeCITR_Pct_HU_ExtChrgTarget1: start-on-event=PokeCITR_Pct_HU_ExtChrgTarget1, operation=PokeCITR_Pct_HU_ExtChrgTarget1.PokeCITR_Pct_HU_ExtChrgTarget1
        Event_PokeCITR_Pct_HU_ExtChrgTarget2: start-on-event=PokeCITR_Pct_HU_ExtChrgTarget2, operation=PokeCITR_Pct_HU_ExtChrgTarget2.PokeCITR_Pct_HU_ExtChrgTarget2
        Event_PokeCITR_Pct_HU_ImmChrgTarget1: start-on-event=PokeCITR_Pct_HU_ImmChrgTarget1, operation=PokeCITR_Pct_HU_ImmChrgTarget1.PokeCITR_Pct_HU_ImmChrgTarget1
        Event_PokeCITR_Pct_HU_ImmChrgTarget2: start-on-event=PokeCITR_Pct_HU_ImmChrgTarget2, operation=PokeCITR_Pct_HU_ImmChrgTarget2.PokeCITR_Pct_HU_ImmChrgTarget2
        Event_PokeCITR_Pct_TBM_ExtChrgTarget1: start-on-event=PokeCITR_Pct_TBM_ExtChrgTarget1, operation=PokeCITR_Pct_TBM_ExtChrgTarget1.PokeCITR_Pct_TBM_ExtChrgTarget1
        Event_PokeCITR_Pct_TBM_ExtChrgTarget2: start-on-event=PokeCITR_Pct_TBM_ExtChrgTarget2, operation=PokeCITR_Pct_TBM_ExtChrgTarget2.PokeCITR_Pct_TBM_ExtChrgTarget2
        Event_PokeCITR_Pct_TBM_ImmChrgTarget1: start-on-event=PokeCITR_Pct_TBM_ImmChrgTarget1, operation=PokeCITR_Pct_TBM_ImmChrgTarget1.PokeCITR_Pct_TBM_ImmChrgTarget1
        Event_PokeCITR_Pct_TBM_ImmChrgTarget2: start-on-event=PokeCITR_Pct_TBM_ImmChrgTarget2, operation=PokeCITR_Pct_TBM_ImmChrgTarget2.PokeCITR_Pct_TBM_ImmChrgTarget2
        Event_PokeCITR_Pct_V2HRsrvBatt: start-on-event=PokeCITR_Pct_V2HRsrvBatt, operation=PokeCITR_Pct_V2HRsrvBatt.PokeCITR_Pct_V2HRsrvBatt
        Event_PokeCITR_Pct_V2LRsrvBatt: start-on-event=PokeCITR_Pct_V2LRsrvBatt, operation=PokeCITR_Pct_V2LRsrvBatt.PokeCITR_Pct_V2LRsrvBatt
        Event_PokeCITR_Pct_V2VRsrvBatt: start-on-event=PokeCITR_Pct_V2VRsrvBatt, operation=PokeCITR_Pct_V2VRsrvBatt.PokeCITR_Pct_V2VRsrvBatt
        Event_PokeCITR_T_HU_Sch{1..4}_CabTemp: start-on-event=PokeCITR_T_HU_Sch{1..4}_CabTemp, operation=PokeCITR_T_HU_Sch{1..4}_CabTemp.PokeCITR_T_HU_Sch{1..4}_CabTemp
        Event_PokeCITR_T_TBM_Sch{1..4}_CabTemp: start-on-event=PokeCITR_T_TBM_Sch{1..4}_CabTemp, operation=PokeCITR_T_TBM_Sch{1..4}_CabTemp.PokeCITR_T_TBM_Sch{1..4}_CabTemp
        Event_PokeCITR_U_ChrgPortLock_StsB: start-on-event=PokeCITR_U_ChrgPortLock_StsB, operation=PokeCITR_U_ChrgPortLock_StsB.PokeCITR_U_ChrgPortLock_StsB
        Event_PokeCITR_b_BCIM_LIN_Chksum_Error: start-on-event=PokeCITR_b_BCIM_LIN_Chksum_Error, operation=PokeCITR_b_BCIM_LIN_Chksum_Error.PokeCITR_b_BCIM_LIN_Chksum_Error
        Event_PokeCITR_b_BCIM_LIN_Data_Error: start-on-event=PokeCITR_b_BCIM_LIN_Data_Error, operation=PokeCITR_b_BCIM_LIN_Data_Error.PokeCITR_b_BCIM_LIN_Data_Error
        Event_PokeCITR_b_BCIM_LIN_Parity_Error: start-on-event=PokeCITR_b_BCIM_LIN_Parity_Error, operation=PokeCITR_b_BCIM_LIN_Parity_Error.PokeCITR_b_BCIM_LIN_Parity_Error
        Event_PokeCITR_b_BCIM_Over_Temp: start-on-event=PokeCITR_b_BCIM_Over_Temp, operation=PokeCITR_b_BCIM_Over_Temp.PokeCITR_b_BCIM_Over_Temp
        Event_PokeCITR_b_BCIM_Undervolt: start-on-event=PokeCITR_b_BCIM_Undervolt, operation=PokeCITR_b_BCIM_Undervolt.PokeCITR_b_BCIM_Undervolt
        Event_PokeCITR_b_CPIM_BlueLED_Sts: start-on-event=PokeCITR_b_CPIM_BlueLED_Sts, operation=PokeCITR_b_CPIM_BlueLED_Sts.PokeCITR_b_CPIM_BlueLED_Sts
        Event_PokeCITR_b_CPIM_GreenLED_Sts: start-on-event=PokeCITR_b_CPIM_GreenLED_Sts, operation=PokeCITR_b_CPIM_GreenLED_Sts.PokeCITR_b_CPIM_GreenLED_Sts
        Event_PokeCITR_b_CPIM_LINChkSumErr: start-on-event=PokeCITR_b_CPIM_LINChkSumErr, operation=PokeCITR_b_CPIM_LINChkSumErr.PokeCITR_b_CPIM_LINChkSumErr
        Event_PokeCITR_b_CPIM_LINDataErr: start-on-event=PokeCITR_b_CPIM_LINDataErr, operation=PokeCITR_b_CPIM_LINDataErr.PokeCITR_b_CPIM_LINDataErr
        Event_PokeCITR_b_CPIM_LINParityErr: start-on-event=PokeCITR_b_CPIM_LINParityErr, operation=PokeCITR_b_CPIM_LINParityErr.PokeCITR_b_CPIM_LINParityErr
        Event_PokeCITR_b_CPIM_OverTemp: start-on-event=PokeCITR_b_CPIM_OverTemp, operation=PokeCITR_b_CPIM_OverTemp.PokeCITR_b_CPIM_OverTemp
        Event_PokeCITR_b_CPIM_RedLED_Sts: start-on-event=PokeCITR_b_CPIM_RedLED_Sts, operation=PokeCITR_b_CPIM_RedLED_Sts.PokeCITR_b_CPIM_RedLED_Sts
        Event_PokeCITR_b_CPIM_UnderVolt: start-on-event=PokeCITR_b_CPIM_UnderVolt, operation=PokeCITR_b_CPIM_UnderVolt.PokeCITR_b_CPIM_UnderVolt
        Event_PokeCITR_b_ChargeNow: start-on-event=PokeCITR_b_ChargeNow, operation=PokeCITR_b_ChargeNow.PokeCITR_b_ChargeNow
        Event_PokeCITR_b_ChrgPortButton_FailSts: start-on-event=PokeCITR_b_ChrgPortButton_FailSts, operation=PokeCITR_b_ChrgPortButton_FailSts.PokeCITR_b_ChrgPortButton_FailSts
        Event_PokeCITR_b_ChrgPortButton_Sts: start-on-event=PokeCITR_b_ChrgPortButton_Sts, operation=PokeCITR_b_ChrgPortButton_Sts.PokeCITR_b_ChrgPortButton_Sts
        Event_PokeCITR_b_ChrgPortLock_StsC: start-on-event=PokeCITR_b_ChrgPortLock_StsC, operation=PokeCITR_b_ChrgPortLock_StsC.PokeCITR_b_ChrgPortLock_StsC
        Event_PokeCITR_b_ChrgPort_BCM_Cmd: start-on-event=PokeCITR_b_ChrgPort_BCM_Cmd, operation=PokeCITR_b_ChrgPort_BCM_Cmd.PokeCITR_b_ChrgPort_BCM_Cmd
        Event_PokeCITR_b_ChrgPort_Fdbk: start-on-event=PokeCITR_b_ChrgPort_Fdbk, operation=PokeCITR_b_ChrgPort_Fdbk.PokeCITR_b_ChrgPort_Fdbk
        Event_PokeCITR_b_CoopCh_VehLocation: start-on-event=PokeCITR_b_CoopCh_VehLocation, operation=PokeCITR_b_CoopCh_VehLocation.PokeCITR_b_CoopCh_VehLocation
        Event_PokeCITR_b_DC_PwrLev: start-on-event=PokeCITR_b_DC_PwrLev, operation=PokeCITR_b_DC_PwrLev.PokeCITR_b_DC_PwrLev
        Event_PokeCITR_b_Drv_Dr_Unlocking: start-on-event=PokeCITR_b_Drv_Dr_Unlocking, operation=PokeCITR_b_Drv_Dr_Unlocking.PokeCITR_b_Drv_Dr_Unlocking
        Event_PokeCITR_b_HU_Sch1_ChargeUntilFull: start-on-event=PokeCITR_b_HU_Sch1_ChargeUntilFull, operation=PokeCITR_b_HU_Sch1_ChargeUntilFull.PokeCITR_b_HU_Sch1_ChargeUntilFull
        Event_PokeCITR_b_HU_Sch1_Do_Not_Repeat: start-on-event=PokeCITR_b_HU_Sch1_Do_Not_Repeat, operation=PokeCITR_b_HU_Sch1_Do_Not_Repeat.PokeCITR_b_HU_Sch1_Do_Not_Repeat
        Event_PokeCITR_b_HU_Sch1_Enbl: start-on-event=PokeCITR_b_HU_Sch1_Enbl, operation=PokeCITR_b_HU_Sch1_Enbl.PokeCITR_b_HU_Sch1_Enbl
        Event_PokeCITR_b_HU_Sch1_Priority: start-on-event=PokeCITR_b_HU_Sch1_Priority, operation=PokeCITR_b_HU_Sch1_Priority.PokeCITR_b_HU_Sch1_Priority
        Event_PokeCITR_b_HU_Sch1_Submit: start-on-event=PokeCITR_b_HU_Sch1_Submit, operation=PokeCITR_b_HU_Sch1_Submit.PokeCITR_b_HU_Sch1_Submit
        Event_PokeCITR_b_HU_Sch2_ChargeUntilFull: start-on-event=PokeCITR_b_HU_Sch2_ChargeUntilFull, operation=PokeCITR_b_HU_Sch2_ChargeUntilFull.PokeCITR_b_HU_Sch2_ChargeUntilFull
        Event_PokeCITR_b_HU_Sch2_Do_Not_Repeat: start-on-event=PokeCITR_b_HU_Sch2_Do_Not_Repeat, operation=PokeCITR_b_HU_Sch2_Do_Not_Repeat.PokeCITR_b_HU_Sch2_Do_Not_Repeat
        Event_PokeCITR_b_HU_Sch2_Enbl: start-on-event=PokeCITR_b_HU_Sch2_Enbl, operation=PokeCITR_b_HU_Sch2_Enbl.PokeCITR_b_HU_Sch2_Enbl
        Event_PokeCITR_b_HU_Sch2_Priority: start-on-event=PokeCITR_b_HU_Sch2_Priority, operation=PokeCITR_b_HU_Sch2_Priority.PokeCITR_b_HU_Sch2_Priority
        Event_PokeCITR_b_HU_Sch2_Submit: start-on-event=PokeCITR_b_HU_Sch2_Submit, operation=PokeCITR_b_HU_Sch2_Submit.PokeCITR_b_HU_Sch2_Submit
        Event_PokeCITR_b_HU_Sch3_ChargeUntilFull: start-on-event=PokeCITR_b_HU_Sch3_ChargeUntilFull, operation=PokeCITR_b_HU_Sch3_ChargeUntilFull.PokeCITR_b_HU_Sch3_ChargeUntilFull
        Event_PokeCITR_b_HU_Sch3_Do_Not_Repeat: start-on-event=PokeCITR_b_HU_Sch3_Do_Not_Repeat, operation=PokeCITR_b_HU_Sch3_Do_Not_Repeat.PokeCITR_b_HU_Sch3_Do_Not_Repeat
        Event_PokeCITR_b_HU_Sch3_Enbl: start-on-event=PokeCITR_b_HU_Sch3_Enbl, operation=PokeCITR_b_HU_Sch3_Enbl.PokeCITR_b_HU_Sch3_Enbl
        Event_PokeCITR_b_HU_Sch3_Priority: start-on-event=PokeCITR_b_HU_Sch3_Priority, operation=PokeCITR_b_HU_Sch3_Priority.PokeCITR_b_HU_Sch3_Priority
        Event_PokeCITR_b_HU_Sch3_Submit: start-on-event=PokeCITR_b_HU_Sch3_Submit, operation=PokeCITR_b_HU_Sch3_Submit.PokeCITR_b_HU_Sch3_Submit
        Event_PokeCITR_b_HU_Sch4_Enbl: start-on-event=PokeCITR_b_HU_Sch4_Enbl, operation=PokeCITR_b_HU_Sch4_Enbl.PokeCITR_b_HU_Sch4_Enbl
        Event_PokeCITR_b_HU_Sch4_Submit: start-on-event=PokeCITR_b_HU_Sch4_Submit, operation=PokeCITR_b_HU_Sch4_Submit.PokeCITR_b_HU_Sch4_Submit
        Event_PokeCITR_b_Icon1_FailSts: start-on-event=PokeCITR_b_Icon1_FailSts, operation=PokeCITR_b_Icon1_FailSts.PokeCITR_b_Icon1_FailSts
        Event_PokeCITR_b_Icon2_FailSts: start-on-event=PokeCITR_b_Icon2_FailSts, operation=PokeCITR_b_Icon2_FailSts.PokeCITR_b_Icon2_FailSts
        Event_PokeCITR_b_PP2ACPresentSens1: start-on-event=PokeCITR_b_PP2ACPresentSens1, operation=PokeCITR_b_PP2ACPresentSens1.PokeCITR_b_PP2ACPresentSens1
        Event_PokeCITR_b_PP2ACPresentSens2: start-on-event=PokeCITR_b_PP2ACPresentSens2, operation=PokeCITR_b_PP2ACPresentSens2.PokeCITR_b_PP2ACPresentSens2
        Event_PokeCITR_b_PP2ButtonSts: start-on-event=PokeCITR_b_PP2ButtonSts, operation=PokeCITR_b_PP2ButtonSts.PokeCITR_b_PP2ButtonSts
        Event_PokeCITR_b_PP2LidSwitchSts240: start-on-event=PokeCITR_b_PP2LidSwitchSts240, operation=PokeCITR_b_PP2LidSwitchSts240.PokeCITR_b_PP2LidSwitchSts240
        Event_PokeCITR_b_PP2LidSwitchSts120A: start-on-event=PokeCITR_b_PP2LidSwitchSts120A, operation=PokeCITR_b_PP2LidSwitchSts120A.PokeCITR_b_PP2LidSwitchSts120A
        Event_PokeCITR_b_PP2LidSwitchSts120B: start-on-event=PokeCITR_b_PP2LidSwitchSts120B, operation=PokeCITR_b_PP2LidSwitchSts120B.PokeCITR_b_PP2LidSwitchSts120B
        Event_PokeCITR_b_PP2_Gnd_Fault_Det: start-on-event=PokeCITR_b_PP2_Gnd_Fault_Det, operation=PokeCITR_b_PP2_Gnd_Fault_Det.PokeCITR_b_PP2_Gnd_Fault_Det
        Event_PokeCITR_b_PP2_LIN_Cksm_Err: start-on-event=PokeCITR_b_PP2_LIN_Cksm_Err, operation=PokeCITR_b_PP2_LIN_Cksm_Err.PokeCITR_b_PP2_LIN_Cksm_Err
        Event_PokeCITR_b_PP2_LIN_Data_Err: start-on-event=PokeCITR_b_PP2_LIN_Data_Err, operation=PokeCITR_b_PP2_LIN_Data_Err.PokeCITR_b_PP2_LIN_Data_Err
        Event_PokeCITR_b_PP2_LIN_Parity_Err: start-on-event=PokeCITR_b_PP2_LIN_Parity_Err, operation=PokeCITR_b_PP2_LIN_Parity_Err.PokeCITR_b_PP2_LIN_Parity_Err
        Event_PokeCITR_b_PPACPresentSens1: start-on-event=PokeCITR_b_PPACPresentSens1, operation=PokeCITR_b_PPACPresentSens1.PokeCITR_b_PPACPresentSens1
        Event_PokeCITR_b_PPACPresentSens2: start-on-event=PokeCITR_b_PPACPresentSens2, operation=PokeCITR_b_PPACPresentSens2.PokeCITR_b_PPACPresentSens2
        Event_PokeCITR_b_PPButtonSts: start-on-event=PokeCITR_b_PPButtonSts, operation=PokeCITR_b_PPButtonSts.PokeCITR_b_PPButtonSts
        Event_PokeCITR_b_PPLidSwitchSts120A: start-on-event=PokeCITR_b_PPLidSwitchSts120A, operation=PokeCITR_b_PPLidSwitchSts120A.PokeCITR_b_PPLidSwitchSts120A
        Event_PokeCITR_b_PPLidSwitchSts120B: start-on-event=PokeCITR_b_PPLidSwitchSts120B, operation=PokeCITR_b_PPLidSwitchSts120B.PokeCITR_b_PPLidSwitchSts120B
        Event_PokeCITR_b_PPLidSwitchSts240: start-on-event=PokeCITR_b_PPLidSwitchSts240, operation=PokeCITR_b_PPLidSwitchSts240.PokeCITR_b_PPLidSwitchSts240
        Event_PokeCITR_b_PP_Gnd_Fault_Det: start-on-event=PokeCITR_b_PP_Gnd_Fault_Det, operation=PokeCITR_b_PP_Gnd_Fault_Det.PokeCITR_b_PP_Gnd_Fault_Det
        Event_PokeCITR_b_PP_LIN_Cksm_Err: start-on-event=PokeCITR_b_PP_LIN_Cksm_Err, operation=PokeCITR_b_PP_LIN_Cksm_Err.PokeCITR_b_PP_LIN_Cksm_Err
        Event_PokeCITR_b_PP_LIN_Data_Err: start-on-event=PokeCITR_b_PP_LIN_Data_Err, operation=PokeCITR_b_PP_LIN_Data_Err.PokeCITR_b_PP_LIN_Data_Err
        Event_PokeCITR_b_PP_LIN_Parity_Err: start-on-event=PokeCITR_b_PP_LIN_Parity_Err, operation=PokeCITR_b_PP_LIN_Parity_Err.PokeCITR_b_PP_LIN_Parity_Err
        Event_PokeCITR_b_RsErrSPP: start-on-event=PokeCITR_b_RsErrSPP, operation=PokeCITR_b_RsErrSPP.PokeCITR_b_RsErrSPP
        Event_PokeCITR_b_RsErrSPP2: start-on-event=PokeCITR_b_RsErrSPP2, operation=PokeCITR_b_RsErrSPP2.PokeCITR_b_RsErrSPP2
        Event_PokeCITR_b_SOC_Max_Lev: start-on-event=PokeCITR_b_SOC_Max_Lev, operation=PokeCITR_b_SOC_Max_Lev.PokeCITR_b_SOC_Max_Lev
        Event_PokeCITR_b_TBMStopChrg: start-on-event=PokeCITR_b_TBMStopChrg, operation=PokeCITR_b_TBMStopChrg.PokeCITR_b_TBMStopChrg
        Event_PokeCITR_b_TBM_Charge_Now: start-on-event=PokeCITR_b_TBM_Charge_Now, operation=PokeCITR_b_TBM_Charge_Now.PokeCITR_b_TBM_Charge_Now
        Event_PokeCITR_b_TBM_Sch1_ChargeUntilFull: start-on-event=PokeCITR_b_TBM_Sch1_ChargeUntilFull, operation=PokeCITR_b_TBM_Sch1_ChargeUntilFull.PokeCITR_b_TBM_Sch1_ChargeUntilFull
        Event_PokeCITR_b_TBM_Sch1_Do_Not_Repeat: start-on-event=PokeCITR_b_TBM_Sch1_Do_Not_Repeat, operation=PokeCITR_b_TBM_Sch1_Do_Not_Repeat.PokeCITR_b_TBM_Sch1_Do_Not_Repeat
        Event_PokeCITR_b_TBM_Sch1_Enbl: start-on-event=PokeCITR_b_TBM_Sch1_Enbl, operation=PokeCITR_b_TBM_Sch1_Enbl.PokeCITR_b_TBM_Sch1_Enbl
        Event_PokeCITR_b_TBM_Sch1_Priority: start-on-event=PokeCITR_b_TBM_Sch1_Priority, operation=PokeCITR_b_TBM_Sch1_Priority.PokeCITR_b_TBM_Sch1_Priority
        Event_PokeCITR_b_TBM_Sch1_Submit: start-on-event=PokeCITR_b_TBM_Sch1_Submit, operation=PokeCITR_b_TBM_Sch1_Submit.PokeCITR_b_TBM_Sch1_Submit
        Event_PokeCITR_b_TBM_Sch2_ChargeUntilFull: start-on-event=PokeCITR_b_TBM_Sch2_ChargeUntilFull, operation=PokeCITR_b_TBM_Sch2_ChargeUntilFull.PokeCITR_b_TBM_Sch2_ChargeUntilFull
        Event_PokeCITR_b_TBM_Sch2_Do_Not_Repeat: start-on-event=PokeCITR_b_TBM_Sch2_Do_Not_Repeat, operation=PokeCITR_b_TBM_Sch2_Do_Not_Repeat.PokeCITR_b_TBM_Sch2_Do_Not_Repeat
        Event_PokeCITR_b_TBM_Sch2_Enbl: start-on-event=PokeCITR_b_TBM_Sch2_Enbl, operation=PokeCITR_b_TBM_Sch2_Enbl.PokeCITR_b_TBM_Sch2_Enbl
        Event_PokeCITR_b_TBM_Sch2_Priority: start-on-event=PokeCITR_b_TBM_Sch2_Priority, operation=PokeCITR_b_TBM_Sch2_Priority.PokeCITR_b_TBM_Sch2_Priority
        Event_PokeCITR_b_TBM_Sch2_Submit: start-on-event=PokeCITR_b_TBM_Sch2_Submit, operation=PokeCITR_b_TBM_Sch2_Submit.PokeCITR_b_TBM_Sch2_Submit
        Event_PokeCITR_b_TBM_Sch3_ChargeUntilFull: start-on-event=PokeCITR_b_TBM_Sch3_ChargeUntilFull, operation=PokeCITR_b_TBM_Sch3_ChargeUntilFull.PokeCITR_b_TBM_Sch3_ChargeUntilFull
        Event_PokeCITR_b_TBM_Sch3_Do_Not_Repeat: start-on-event=PokeCITR_b_TBM_Sch3_Do_Not_Repeat, operation=PokeCITR_b_TBM_Sch3_Do_Not_Repeat.PokeCITR_b_TBM_Sch3_Do_Not_Repeat
        Event_PokeCITR_b_TBM_Sch3_Enbl: start-on-event=PokeCITR_b_TBM_Sch3_Enbl, operation=PokeCITR_b_TBM_Sch3_Enbl.PokeCITR_b_TBM_Sch3_Enbl
        Event_PokeCITR_b_TBM_Sch3_Priority: start-on-event=PokeCITR_b_TBM_Sch3_Priority, operation=PokeCITR_b_TBM_Sch3_Priority.PokeCITR_b_TBM_Sch3_Priority
        Event_PokeCITR_b_TBM_Sch3_Submit: start-on-event=PokeCITR_b_TBM_Sch3_Submit, operation=PokeCITR_b_TBM_Sch3_Submit.PokeCITR_b_TBM_Sch3_Submit
        Event_PokeCITR_b_TBM_Sch4_Enbl: start-on-event=PokeCITR_b_TBM_Sch4_Enbl, operation=PokeCITR_b_TBM_Sch4_Enbl.PokeCITR_b_TBM_Sch4_Enbl
        Event_PokeCITR_b_TBM_Sch4_Submit: start-on-event=PokeCITR_b_TBM_Sch4_Submit, operation=PokeCITR_b_TBM_Sch4_Submit.PokeCITR_b_TBM_Sch4_Submit
        Event_PokeCITR_b_V2HModeReq: start-on-event=PokeCITR_b_V2HModeReq, operation=PokeCITR_b_V2HModeReq.PokeCITR_b_V2HModeReq
        Event_PokeCITR_b_V2HReq: start-on-event=PokeCITR_b_V2HReq, operation=PokeCITR_b_V2HReq.PokeCITR_b_V2HReq
        Event_PokeCITR_b_V2HSubmit: start-on-event=PokeCITR_b_V2HSubmit, operation=PokeCITR_b_V2HSubmit.PokeCITR_b_V2HSubmit
        Event_PokeCITR_b_V2LModeReq: start-on-event=PokeCITR_b_V2LModeReq, operation=PokeCITR_b_V2LModeReq.PokeCITR_b_V2LModeReq
        Event_PokeCITR_b_V2LSubmit: start-on-event=PokeCITR_b_V2LSubmit, operation=PokeCITR_b_V2LSubmit.PokeCITR_b_V2LSubmit
        Event_PokeCITR_b_V2LTrunkReq: start-on-event=PokeCITR_b_V2LTrunkReq, operation=PokeCITR_b_V2LTrunkReq.PokeCITR_b_V2LTrunkReq
        Event_PokeCITR_b_V2L_AllReq: start-on-event=PokeCITR_b_V2L_AllReq, operation=PokeCITR_b_V2L_AllReq.PokeCITR_b_V2L_AllReq
        Event_PokeCITR_b_V2L_FrunkReq: start-on-event=PokeCITR_b_V2L_FrunkReq, operation=PokeCITR_b_V2L_FrunkReq.PokeCITR_b_V2L_FrunkReq
        Event_PokeCITR_b_V2VModeReq: start-on-event=PokeCITR_b_V2VModeReq, operation=PokeCITR_b_V2VModeReq.PokeCITR_b_V2VModeReq
        Event_PokeCITR_b_V2VReq: start-on-event=PokeCITR_b_V2VReq, operation=PokeCITR_b_V2VReq.PokeCITR_b_V2VReq
        Event_PokeCITR_b_V2VSubmit: start-on-event=PokeCITR_b_V2VSubmit, operation=PokeCITR_b_V2VSubmit.PokeCITR_b_V2VSubmit
        Event_PokeCITR_e_BCIM_Ind1_FailSts: start-on-event=PokeCITR_e_BCIM_Ind1_FailSts, operation=PokeCITR_e_BCIM_Ind1_FailSts.PokeCITR_e_BCIM_Ind1_FailSts
        Event_PokeCITR_e_BCIM_Ind1_Fdbk: start-on-event=PokeCITR_e_BCIM_Ind1_Fdbk, operation=PokeCITR_e_BCIM_Ind1_Fdbk.PokeCITR_e_BCIM_Ind1_Fdbk
        Event_PokeCITR_e_BCIM_Ind2_FailSts: start-on-event=PokeCITR_e_BCIM_Ind2_FailSts, operation=PokeCITR_e_BCIM_Ind2_FailSts.PokeCITR_e_BCIM_Ind2_FailSts
        Event_PokeCITR_e_BCIM_Ind2_Fdbk: start-on-event=PokeCITR_e_BCIM_Ind2_Fdbk, operation=PokeCITR_e_BCIM_Ind2_Fdbk.PokeCITR_e_BCIM_Ind2_Fdbk
        Event_PokeCITR_e_BCIM_Ind3_FailSts: start-on-event=PokeCITR_e_BCIM_Ind3_FailSts, operation=PokeCITR_e_BCIM_Ind3_FailSts.PokeCITR_e_BCIM_Ind3_FailSts
        Event_PokeCITR_e_BCIM_Ind3_Fdbk: start-on-event=PokeCITR_e_BCIM_Ind3_Fdbk, operation=PokeCITR_e_BCIM_Ind3_Fdbk.PokeCITR_e_BCIM_Ind3_Fdbk
        Event_PokeCITR_e_BCIM_Ind4_FailSts: start-on-event=PokeCITR_e_BCIM_Ind4_FailSts, operation=PokeCITR_e_BCIM_Ind4_FailSts.PokeCITR_e_BCIM_Ind4_FailSts
        Event_PokeCITR_e_BCIM_Ind4_Fdbk: start-on-event=PokeCITR_e_BCIM_Ind4_Fdbk, operation=PokeCITR_e_BCIM_Ind4_Fdbk.PokeCITR_e_BCIM_Ind4_Fdbk
        Event_PokeCITR_e_BCIM_Ind5_FailSts: start-on-event=PokeCITR_e_BCIM_Ind5_FailSts, operation=PokeCITR_e_BCIM_Ind5_FailSts.PokeCITR_e_BCIM_Ind5_FailSts
        Event_PokeCITR_e_BCIM_Ind5_Fdbk: start-on-event=PokeCITR_e_BCIM_Ind5_Fdbk, operation=PokeCITR_e_BCIM_Ind5_Fdbk.PokeCITR_e_BCIM_Ind5_Fdbk
        Event_PokeCITR_e_BCIM_Ind_Color_Fdbk: start-on-event=PokeCITR_e_BCIM_Ind_Color_Fdbk, operation=PokeCITR_e_BCIM_Ind_Color_Fdbk.PokeCITR_e_BCIM_Ind_Color_Fdbk
        Event_PokeCITR_e_CPIM_BlueLED_FailSts: start-on-event=PokeCITR_e_CPIM_BlueLED_FailSts, operation=PokeCITR_e_CPIM_BlueLED_FailSts.PokeCITR_e_CPIM_BlueLED_FailSts
        Event_PokeCITR_e_CPIM_GreenLED_FailSts: start-on-event=PokeCITR_e_CPIM_GreenLED_FailSts, operation=PokeCITR_e_CPIM_GreenLED_FailSts.PokeCITR_e_CPIM_GreenLED_FailSts
        Event_PokeCITR_e_CPIM_Icon1_Sts: start-on-event=PokeCITR_e_CPIM_Icon1_Sts, operation=PokeCITR_e_CPIM_Icon1_Sts.PokeCITR_e_CPIM_Icon1_Sts
        Event_PokeCITR_e_CPIM_Icon2_Sts: start-on-event=PokeCITR_e_CPIM_Icon2_Sts, operation=PokeCITR_e_CPIM_Icon2_Sts.PokeCITR_e_CPIM_Icon2_Sts
        Event_PokeCITR_e_CPIM_Ind1_FailSts: start-on-event=PokeCITR_e_CPIM_Ind1_FailSts, operation=PokeCITR_e_CPIM_Ind1_FailSts.PokeCITR_e_CPIM_Ind1_FailSts
        Event_PokeCITR_e_CPIM_Ind1_Fdbk: start-on-event=PokeCITR_e_CPIM_Ind1_Fdbk, operation=PokeCITR_e_CPIM_Ind1_Fdbk.PokeCITR_e_CPIM_Ind1_Fdbk
        Event_PokeCITR_e_CPIM_Ind2_FailSts: start-on-event=PokeCITR_e_CPIM_Ind2_FailSts, operation=PokeCITR_e_CPIM_Ind2_FailSts.PokeCITR_e_CPIM_Ind2_FailSts
        Event_PokeCITR_e_CPIM_Ind2_Fdbk: start-on-event=PokeCITR_e_CPIM_Ind2_Fdbk, operation=PokeCITR_e_CPIM_Ind2_Fdbk.PokeCITR_e_CPIM_Ind2_Fdbk
        Event_PokeCITR_e_CPIM_Ind3_FailSts: start-on-event=PokeCITR_e_CPIM_Ind3_FailSts, operation=PokeCITR_e_CPIM_Ind3_FailSts.PokeCITR_e_CPIM_Ind3_FailSts
        Event_PokeCITR_e_CPIM_Ind3_Fdbk: start-on-event=PokeCITR_e_CPIM_Ind3_Fdbk, operation=PokeCITR_e_CPIM_Ind3_Fdbk.PokeCITR_e_CPIM_Ind3_Fdbk
        Event_PokeCITR_e_CPIM_Ind4_FailSts: start-on-event=PokeCITR_e_CPIM_Ind4_FailSts, operation=PokeCITR_e_CPIM_Ind4_FailSts.PokeCITR_e_CPIM_Ind4_FailSts
        Event_PokeCITR_e_CPIM_Ind4_Fdbk: start-on-event=PokeCITR_e_CPIM_Ind4_Fdbk, operation=PokeCITR_e_CPIM_Ind4_Fdbk.PokeCITR_e_CPIM_Ind4_Fdbk
        Event_PokeCITR_e_CPIM_Ind5_FailSts: start-on-event=PokeCITR_e_CPIM_Ind5_FailSts, operation=PokeCITR_e_CPIM_Ind5_FailSts.PokeCITR_e_CPIM_Ind5_FailSts
        Event_PokeCITR_e_CPIM_Ind5_Fdbk: start-on-event=PokeCITR_e_CPIM_Ind5_Fdbk, operation=PokeCITR_e_CPIM_Ind5_Fdbk.PokeCITR_e_CPIM_Ind5_Fdbk
        Event_PokeCITR_e_CPIM_Ind_Color_Fdbk: start-on-event=PokeCITR_e_CPIM_Ind_Color_Fdbk, operation=PokeCITR_e_CPIM_Ind_Color_Fdbk.PokeCITR_e_CPIM_Ind_Color_Fdbk
        Event_PokeCITR_e_CPIM_RedLED_FailSts: start-on-event=PokeCITR_e_CPIM_RedLED_FailSts, operation=PokeCITR_e_CPIM_RedLED_FailSts.PokeCITR_e_CPIM_RedLED_FailSts
        Event_PokeCITR_e_ChrgPortDoor_Sts: start-on-event=PokeCITR_e_ChrgPortDoor_Sts, operation=PokeCITR_e_ChrgPortDoor_Sts.PokeCITR_e_ChrgPortDoor_Sts
        Event_PokeCITR_e_ChrgPortLock_FailSts: start-on-event=PokeCITR_e_ChrgPortLock_FailSts, operation=PokeCITR_e_ChrgPortLock_FailSts.PokeCITR_e_ChrgPortLock_FailSts
        Event_PokeCITR_e_ChrgrFlapSts: start-on-event=PokeCITR_e_ChrgrFlapSts, operation=PokeCITR_e_ChrgrFlapSts.PokeCITR_e_ChrgrFlapSts
        Event_PokeCITR_e_CoopCh_ChrgCmd: start-on-event=PokeCITR_e_CoopCh_ChrgCmd, operation=PokeCITR_e_CoopCh_ChrgCmd.PokeCITR_e_CoopCh_ChrgCmd
        Event_PokeCITR_e_DVC_IO_BCIM: start-on-event=PokeCITR_e_DVC_IO_BCIM, operation=PokeCITR_e_DVC_IO_BCIM.PokeCITR_e_DVC_IO_BCIM
        Event_PokeCITR_e_DVC_IO_BCIM_JL: start-on-event=PokeCITR_e_DVC_IO_BCIM_JL, operation=PokeCITR_e_DVC_IO_BCIM_JL.PokeCITR_e_DVC_IO_BCIM_JL
        Event_PokeCITR_e_DVC_IO_CPIM: start-on-event=PokeCITR_e_DVC_IO_CPIM, operation=PokeCITR_e_DVC_IO_CPIM.PokeCITR_e_DVC_IO_CPIM
        Event_PokeCITR_e_DateTmFormat: start-on-event=PokeCITR_e_DateTmFormat, operation=PokeCITR_e_DateTmFormat.PokeCITR_e_DateTmFormat
        Event_PokeCITR_e_DoorLockLastElSts: start-on-event=PokeCITR_e_DoorLockLastElSts, operation=PokeCITR_e_DoorLockLastElSts.PokeCITR_e_DoorLockLastElSts
        Event_PokeCITR_e_DoorLockLastElSts_2: start-on-event=PokeCITR_e_DoorLockLastElSts_2, operation=PokeCITR_e_DoorLockLastElSts_2.PokeCITR_e_DoorLockLastElSts_2
        Event_PokeCITR_e_FOTA_Install_Type: start-on-event=PokeCITR_e_FOTA_Install_Type, operation=PokeCITR_e_FOTA_Install_Type.PokeCITR_e_FOTA_Install_Type
        Event_PokeCITR_e_FOTA_Installation_Status: start-on-event=PokeCITR_e_FOTA_Installation_Status, operation=PokeCITR_e_FOTA_Installation_Status.PokeCITR_e_FOTA_Installation_Status
        Event_PokeCITR_e_HU_ChrgSchedType1: start-on-event=PokeCITR_e_HU_ChrgSchedType1, operation=PokeCITR_e_HU_ChrgSchedType1.PokeCITR_e_HU_ChrgSchedType1
        Event_PokeCITR_e_HU_ChrgSchedType2: start-on-event=PokeCITR_e_HU_ChrgSchedType2, operation=PokeCITR_e_HU_ChrgSchedType2.PokeCITR_e_HU_ChrgSchedType2
        Event_PokeCITR_e_HU_Sch1_Type: start-on-event=PokeCITR_e_HU_Sch1_Type, operation=PokeCITR_e_HU_Sch1_Type.PokeCITR_e_HU_Sch1_Type
        Event_PokeCITR_e_HU_Sch2_Type: start-on-event=PokeCITR_e_HU_Sch2_Type, operation=PokeCITR_e_HU_Sch2_Type.PokeCITR_e_HU_Sch2_Type
        Event_PokeCITR_e_HU_Sch3_Allow: start-on-event=PokeCITR_e_HU_Sch3_Allow, operation=PokeCITR_e_HU_Sch3_Allow.PokeCITR_e_HU_Sch3_Allow
        Event_PokeCITR_e_HU_Sch3_Type: start-on-event=PokeCITR_e_HU_Sch3_Type, operation=PokeCITR_e_HU_Sch3_Type.PokeCITR_e_HU_Sch3_Type
        Event_PokeCITR_e_HU_Sch4_Allow: start-on-event=PokeCITR_e_HU_Sch4_Allow, operation=PokeCITR_e_HU_Sch4_Allow.PokeCITR_e_HU_Sch4_Allow
        Event_PokeCITR_e_PP2Fault: start-on-event=PokeCITR_e_PP2Fault, operation=PokeCITR_e_PP2Fault.PokeCITR_e_PP2Fault
        Event_PokeCITR_e_PP2FaultRsn: start-on-event=PokeCITR_e_PP2FaultRsn, operation=PokeCITR_e_PP2FaultRsn.PokeCITR_e_PP2FaultRsn
        Event_PokeCITR_e_PP2LEDFault: start-on-event=PokeCITR_e_PP2LEDFault, operation=PokeCITR_e_PP2LEDFault.PokeCITR_e_PP2LEDFault
        Event_PokeCITR_e_PP2_LED_A_ColorFeedback: start-on-event=PokeCITR_e_PP2_LED_A_ColorFeedback, operation=PokeCITR_e_PP2_LED_A_ColorFeedback.PokeCITR_e_PP2_LED_A_ColorFeedback
        Event_PokeCITR_e_PP2_LED_A_FailSts: start-on-event=PokeCITR_e_PP2_LED_A_FailSts, operation=PokeCITR_e_PP2_LED_A_FailSts.PokeCITR_e_PP2_LED_A_FailSts
        Event_PokeCITR_e_PP2_LED_A_Feedback: start-on-event=PokeCITR_e_PP2_LED_A_Feedback, operation=PokeCITR_e_PP2_LED_A_Feedback.PokeCITR_e_PP2_LED_A_Feedback
        Event_PokeCITR_e_PP2_LED_B_ColorFeedback: start-on-event=PokeCITR_e_PP2_LED_B_ColorFeedback, operation=PokeCITR_e_PP2_LED_B_ColorFeedback.PokeCITR_e_PP2_LED_B_ColorFeedback
        Event_PokeCITR_e_PP2_LED_B_FailSts: start-on-event=PokeCITR_e_PP2_LED_B_FailSts, operation=PokeCITR_e_PP2_LED_B_FailSts.PokeCITR_e_PP2_LED_B_FailSts
        Event_PokeCITR_e_PP2_LED_B_Feedback: start-on-event=PokeCITR_e_PP2_LED_B_Feedback, operation=PokeCITR_e_PP2_LED_B_Feedback.PokeCITR_e_PP2_LED_B_Feedback
        Event_PokeCITR_e_PPFault: start-on-event=PokeCITR_e_PPFault, operation=PokeCITR_e_PPFault.PokeCITR_e_PPFault
        Event_PokeCITR_e_PPFaultRsn: start-on-event=PokeCITR_e_PPFaultRsn, operation=PokeCITR_e_PPFaultRsn.PokeCITR_e_PPFaultRsn
        Event_PokeCITR_e_PPLEDFault: start-on-event=PokeCITR_e_PPLEDFault, operation=PokeCITR_e_PPLEDFault.PokeCITR_e_PPLEDFault
        Event_PokeCITR_e_PP_LED_A_ColorFeedback: start-on-event=PokeCITR_e_PP_LED_A_ColorFeedback, operation=PokeCITR_e_PP_LED_A_ColorFeedback.PokeCITR_e_PP_LED_A_ColorFeedback
        Event_PokeCITR_e_PP_LED_A_FailSts: start-on-event=PokeCITR_e_PP_LED_A_FailSts, operation=PokeCITR_e_PP_LED_A_FailSts.PokeCITR_e_PP_LED_A_FailSts
        Event_PokeCITR_e_PP_LED_A_Feedback: start-on-event=PokeCITR_e_PP_LED_A_Feedback, operation=PokeCITR_e_PP_LED_A_Feedback.PokeCITR_e_PP_LED_A_Feedback
        Event_PokeCITR_e_PP_LED_B_ColorFeedback: start-on-event=PokeCITR_e_PP_LED_B_ColorFeedback, operation=PokeCITR_e_PP_LED_B_ColorFeedback.PokeCITR_e_PP_LED_B_ColorFeedback
        Event_PokeCITR_e_PP_LED_B_FailSts: start-on-event=PokeCITR_e_PP_LED_B_FailSts, operation=PokeCITR_e_PP_LED_B_FailSts.PokeCITR_e_PP_LED_B_FailSts
        Event_PokeCITR_e_PP_LED_B_Feedback: start-on-event=PokeCITR_e_PP_LED_B_Feedback, operation=PokeCITR_e_PP_LED_B_Feedback.PokeCITR_e_PP_LED_B_Feedback
        Event_PokeCITR_e_PP_LED_C_ColorFeedback: start-on-event=PokeCITR_e_PP_LED_C_ColorFeedback, operation=PokeCITR_e_PP_LED_C_ColorFeedback.PokeCITR_e_PP_LED_C_ColorFeedback
        Event_PokeCITR_e_PP_LED_C_FailSts: start-on-event=PokeCITR_e_PP_LED_C_FailSts, operation=PokeCITR_e_PP_LED_C_FailSts.PokeCITR_e_PP_LED_C_FailSts
        Event_PokeCITR_e_PP_LED_C_Feedback: start-on-event=PokeCITR_e_PP_LED_C_Feedback, operation=PokeCITR_e_PP_LED_C_Feedback.PokeCITR_e_PP_LED_C_Feedback
        Event_PokeCITR_e_PowerLimit_Req: start-on-event=PokeCITR_e_PowerLimit_Req, operation=PokeCITR_e_PowerLimit_Req.PokeCITR_e_PowerLimit_Req
        Event_PokeCITR_e_PowerLimit_Req_2: start-on-event=PokeCITR_e_PowerLimit_Req_2, operation=PokeCITR_e_PowerLimit_Req_2.PokeCITR_e_PowerLimit_Req_2
        Event_PokeCITR_e_RmtChrgPortLkCmd: start-on-event=PokeCITR_e_RmtChrgPortLkCmd, operation=PokeCITR_e_RmtChrgPortLkCmd.PokeCITR_e_RmtChrgPortLkCmd
        Event_PokeCITR_e_TBM_ChrgSchedType1: start-on-event=PokeCITR_e_TBM_ChrgSchedType1, operation=PokeCITR_e_TBM_ChrgSchedType1.PokeCITR_e_TBM_ChrgSchedType1
        Event_PokeCITR_e_TBM_ChrgSchedType2: start-on-event=PokeCITR_e_TBM_ChrgSchedType2, operation=PokeCITR_e_TBM_ChrgSchedType2.PokeCITR_e_TBM_ChrgSchedType2
        Event_PokeCITR_e_TBM_Sch1_Type: start-on-event=PokeCITR_e_TBM_Sch1_Type, operation=PokeCITR_e_TBM_Sch1_Type.PokeCITR_e_TBM_Sch1_Type
        Event_PokeCITR_e_TBM_Sch2_Type: start-on-event=PokeCITR_e_TBM_Sch2_Type, operation=PokeCITR_e_TBM_Sch2_Type.PokeCITR_e_TBM_Sch2_Type
        Event_PokeCITR_e_TBM_Sch3_Allow: start-on-event=PokeCITR_e_TBM_Sch3_Allow, operation=PokeCITR_e_TBM_Sch3_Allow.PokeCITR_e_TBM_Sch3_Allow
        Event_PokeCITR_e_TBM_Sch3_Type: start-on-event=PokeCITR_e_TBM_Sch3_Type, operation=PokeCITR_e_TBM_Sch3_Type.PokeCITR_e_TBM_Sch3_Type
        Event_PokeCITR_e_TBM_Sch4_Allow: start-on-event=PokeCITR_e_TBM_Sch4_Allow, operation=PokeCITR_e_TBM_Sch4_Allow.PokeCITR_e_TBM_Sch4_Allow
        Event_PokeCITR_l_DistanceToCharge: start-on-event=PokeCITR_l_DistanceToCharge, operation=PokeCITR_l_DistanceToCharge.PokeCITR_l_DistanceToCharge
        Event_PokeCITR_t_TimeToCharge: start-on-event=PokeCITR_t_TimeToCharge, operation=PokeCITR_t_TimeToCharge.PokeCITR_t_TimeToCharge
        Event_TmotCITR_b_ChrgPort_BCM_Cmd: start-on-event=TmotCITR_b_ChrgPort_BCM_Cmd, operation=TmotCITR_b_ChrgPort_BCM_Cmd.TmotCITR_b_ChrgPort_BCM_Cmd
        Event_TmotCITR_b_DC_PwrLev: start-on-event=TmotCITR_b_DC_PwrLev, operation=TmotCITR_b_DC_PwrLev.TmotCITR_b_DC_PwrLev
        Event_TmotCITR_b_DateTmDay: start-on-event=TmotCITR_b_DateTmDay, operation=TmotCITR_b_DateTmDay.TmotCITR_b_DateTmDay
        Event_TmotCITR_b_Date_Day1: start-on-event=TmotCITR_b_Date_Day1, operation=TmotCITR_b_Date_Day1.TmotCITR_b_Date_Day1
        Event_TmotCITR_b_HU_Sch{1..4}_Day: start-on-event=TmotCITR_b_HU_Sch{1..4}_Day, operation=TmotCITR_b_HU_Sch{1..4}_Day.TmotCITR_b_HU_Sch{1..4}_Day
        Event_TmotCITR_b_TBM_Sch{1..4}_Day: start-on-event=TmotCITR_b_TBM_Sch{1..4}_Day, operation=TmotCITR_b_TBM_Sch{1..4}_Day.TmotCITR_b_TBM_Sch{1..4}_Day
        Event_TmotCITR_e_DoorLockLastElSts: start-on-event=TmotCITR_e_DoorLockLastElSts, operation=TmotCITR_e_DoorLockLastElSts.TmotCITR_e_DoorLockLastElSts
        Event_TmotCITR_e_DoorLockLastElSts_2: start-on-event=TmotCITR_e_DoorLockLastElSts_2, operation=TmotCITR_e_DoorLockLastElSts_2.TmotCITR_e_DoorLockLastElSts_2
        Event_TmotCITR_e_PowerLimitReq: start-on-event=TmotCITR_e_PowerLimitReq, operation=TmotCITR_e_PowerLimitReq.TmotCITR_e_PowerLimitReq
        Event_TmotCITR_e_PowerLimitReq_2: start-on-event=TmotCITR_e_PowerLimitReq_2, operation=TmotCITR_e_PowerLimitReq_2.TmotCITR_e_PowerLimitReq_2
        Event_TmotCITR_e_RmtChrgPortLkCmd: start-on-event=TmotCITR_e_RmtChrgPortLkCmd, operation=TmotCITR_e_RmtChrgPortLkCmd.TmotCITR_e_RmtChrgPortLkCmd
